VERSION "HNNBNNNYNNNNNNNNNNNNNNNNNNNNNNNNNNNNNNNNNN/4/%%%/4/'%**4NNN///"

NS_ :

BS_:

BU_: BAP_Tester ELV Gateway_Max HUD Kombi

BO_ 997 TSG_FT_02: 8 Gateway_Max
 SG_ TSG_FT_02_CRC : 0|8@1+ (1,0) [0|255] ""  Kombi
 SG_ TSG_FT_02_BZ : 8|4@1+ (1,0) [0|15] ""  Kombi
 SG_ FT_Tuer_Status : 12|2@1+ (1.0,0.0) [0.0|3] ""  Vector__XXX
 SG_ FT_Tuer_Status_QBit : 14|1@1+ (1.0,0.0) [0.0|1] ""  Vector__XXX
 SG_ FT_Lock_Taster_02 : 15|1@1+ (1.0,0.0) [0.0|1] ""  Vector__XXX
 SG_ FT_Schluesselschalter_zu_02 : 16|1@1+ (1.0,0.0) [0.0|1] ""  Vector__XXX
 SG_ FT_BFS_Tuer_Status : 17|2@1+ (1.0,0.0) [0.0|3] ""  Vector__XXX
 SG_ FT_HBFS_Tuer_Status : 19|2@1+ (1.0,0.0) [0.0|3] ""  Vector__XXX
 SG_ FT_HFS_Tuer_Status : 21|2@1+ (1.0,0.0) [0.0|3] ""  Vector__XXX
 SG_ FT_Tueroeffnen_Warnung : 23|1@1+ (1.0,0.0) [0.0|1] ""  Vector__XXX
 SG_ FT_SP_Heizung_ein : 24|1@1+ (1.0,0.0) [0.0|1] ""  Vector__XXX
 SG_ FT_Kisi_Taster_li_02 : 25|1@1+ (1.0,0.0) [0.0|1] ""  Vector__XXX
 SG_ FT_Kisi_Taster_re_02 : 26|1@1+ (1.0,0.0) [0.0|1] ""  Vector__XXX
 SG_ FT_TD_Taste_Status : 27|2@1+ (1.0,0.0) [0.0|3] ""  Vector__XXX
 SG_ FT_TCR_Mode_aktiv : 29|1@1+ (1.0,0.0) [0.0|1] ""  Vector__XXX
 SG_ TBF_FS_Touch_Event : 30|4@1+ (1.0,0.0) [0.0|15] ""  Vector__XXX
 SG_ FT_KiSi_Status_Soll_HBFS : 34|1@1+ (1.0,0.0) [0.0|1] ""  Vector__XXX
 SG_ FT_KiSi_Status_Soll_HFS : 35|1@1+ (1.0,0.0) [0.0|1] ""  Vector__XXX
 SG_ FS_Push_Tuergriff : 36|1@1+ (1.0,0.0) [0.0|1] ""  Vector__XXX
 SG_ TSG_FS_Spiegel_angeklappt : 37|1@1+ (1.0,0.0) [0.0|1] ""  Vector__XXX
 SG_ FT_Cargolock_bet : 38|1@1+ (1.0,0.0) [0.0|1] ""  Vector__XXX
 SG_ FT_kisi_asynchron : 40|1@1+ (1.0,0.0) [0.0|1] ""  Vector__XXX
 SG_ eTAB_FS_Bowdenzug_Auswerfen : 41|1@1+ (1.0,0.0) [0.0|1] ""  Vector__XXX
 SG_ FS_Status_eTAG_ext : 42|3@1+ (1.0,0.0) [0.0|7] ""  Vector__XXX
 SG_ FT_ASW_Warnton : 45|2@1+ (1.0,0.0) [0.0|3] ""  Vector__XXX
 SG_ SSA_FT_ASW_Status : 47|2@1+ (1.0,0.0) [0.0|3] ""  Vector__XXX

BO_ 975 TSG_HBFS_01: 8 Gateway_Max
 SG_ HBFS_Tuer_geoeffnet : 0|1@1+ (1.0,0.0) [0.0|1] ""  Vector__XXX
 SG_ HBFS_verriegelt : 1|1@1+ (1.0,0.0) [0.0|1] ""  Vector__XXX
 SG_ HBFS_gesafet : 2|1@1+ (1.0,0.0) [0.0|1] ""  Vector__XXX
 SG_ HBFS_Heckrollotaster_betaetigt : 3|1@1+ (1.0,0.0) [0.0|1] ""  Vector__XXX
 SG_ HBFS_Tuerschloss_defekt : 4|1@1+ (1.0,0.0) [0.0|1] ""  Vector__XXX
 SG_ HBFS_Unlock_Taster : 5|1@1+ (1.0,0.0) [0.0|1] ""  Vector__XXX
 SG_ HBFS_Lock_Taster : 6|1@1+ (1.0,0.0) [0.0|1] ""  Vector__XXX
 SG_ HBFS_Sperrklinke : 7|1@1+ (1.0,0.0) [0.0|1] ""  Vector__XXX
 SG_ HBFS_TAG_betaetigt : 8|1@1+ (1.0,0.0) [0.0|1] ""  Vector__XXX
 SG_ HBFS_TIG_betaetigt : 9|1@1+ (1.0,0.0) [0.0|1] ""  Vector__XXX
 SG_ HBFS_FH_S_HFS_AutoHoch : 10|1@1+ (1.0,0.0) [0.0|1] ""  Vector__XXX
 SG_ HBFS_FH_S_HFS_AutoTief : 11|1@1+ (1.0,0.0) [0.0|1] ""  Vector__XXX
 SG_ HBFS_FH_S_HFS_ManHoch : 12|1@1+ (1.0,0.0) [0.0|1] ""  Vector__XXX
 SG_ HBFS_FH_S_HFS_ManTief : 13|1@1+ (1.0,0.0) [0.0|1] ""  Vector__XXX
 SG_ HBFS_Tuer_Status : 14|2@1+ (1.0,0.0) [0.0|3] ""  Vector__XXX
 SG_ HBFS_SAD_Schalter : 16|4@1+ (1.0,0.0) [0.0|15] ""  Vector__XXX
 SG_ HBFS_FH_S_ManHoch : 20|1@1+ (1.0,0.0) [0.0|1] ""  Vector__XXX
 SG_ HBFS_FH_S_AutoHoch : 21|1@1+ (1.0,0.0) [0.0|1] ""  Vector__XXX
 SG_ HBFS_FH_S_ManTief : 22|1@1+ (1.0,0.0) [0.0|1] ""  Vector__XXX
 SG_ HBFS_FH_S_AutoTief : 23|1@1+ (1.0,0.0) [0.0|1] ""  Vector__XXX
 SG_ HBFS_FH_Oeffnung : 24|8@1+ (0.5,0) [0.0|100.0] "Unit_PerCent"  Vector__XXX
 SG_ HBFS_FH_Bew_hoch : 32|1@1+ (1.0,0.0) [0.0|1] ""  Vector__XXX
 SG_ HBFS_FH_Bew_tief : 33|1@1+ (1.0,0.0) [0.0|1] ""  Vector__XXX
 SG_ HBFS_FH_Fang : 34|1@1+ (1.0,0.0) [0.0|1] ""  Vector__XXX
 SG_ HBFS_FH_Block : 35|1@1+ (1.0,0.0) [0.0|1] ""  Vector__XXX
 SG_ HBFS_FH_Thermo : 36|1@1+ (1.0,0.0) [0.0|1] ""  Vector__XXX
 SG_ HBFS_UEKB_aktiviert : 37|1@1+ (1.0,0.0) [0.0|1] ""  Vector__XXX
 SG_ HBFS_Tueroeffnen_Warnung : 38|1@1+ (1.0,0.0) [0.0|1] ""  Vector__XXX
 SG_ HBFS_FH_normiert : 39|1@1+ (1.0,0.0) [0.0|1] ""  Vector__XXX
 SG_ ASW_Warnung_aktiv_HBFS : 40|1@1+ (1.0,0.0) [0.0|1] ""  Vector__XXX
 SG_ HBFS_Zuziehhilfe_aktiv : 41|1@1+ (1.0,0.0) [0.0|1] ""  Vector__XXX
 SG_ HBFS_Seitenrollo_hoch : 42|1@1+ (1.0,0.0) [0.0|1] ""  Vector__XXX
 SG_ HBFS_Seitenrollo_tief : 43|1@1+ (1.0,0.0) [0.0|1] ""  Vector__XXX
 SG_ HBFS_Status_KiSi : 44|1@1+ (1.0,0.0) [0.0|1] ""  Vector__XXX
 SG_ SSR_HBFS_Pos_Unten : 45|1@1+ (1.0,0.0) [0.0|1] ""  Vector__XXX
 SG_ HBFS_Oben_Block_erw : 46|1@1+ (1.0,0.0) [0.0|1] ""  Vector__XXX
 SG_ HBFS_Unten_Block_erw : 47|1@1+ (1.0,0.0) [0.0|1] ""  Vector__XXX
 SG_ MTHBFS_M_Taste : 48|1@1+ (1.0,0.0) [0.0|1] ""  Vector__XXX
 SG_ MTHBFS_Pos1 : 49|1@1+ (1.0,0.0) [0.0|1] ""  Vector__XXX
 SG_ MTHBFS_Pos2 : 50|1@1+ (1.0,0.0) [0.0|1] ""  Vector__XXX
 SG_ MTHBFS_Pos3 : 51|1@1+ (1.0,0.0) [0.0|1] ""  Vector__XXX
 SG_ HBFS_MRollo_Schalter : 52|3@1+ (1.0,0.0) [0.0|7] ""  Vector__XXX
 SG_ HBFS_Lock_Taster_inv : 55|1@1+ (1.0,0.0) [0.0|1] ""  Vector__XXX
 SG_ HBFS_Status_KiSi_inv : 56|1@1+ (1.0,0.0) [0.0|1] ""  Vector__XXX
 SG_ HBFS_Status_eTAG : 57|2@1+ (1.0,0.0) [0.0|3] ""  Vector__XXX
 SG_ HBFS_Tuer_Status_QBit : 59|1@1+ (1.0,0.0) [0.0|1] ""  Vector__XXX
 SG_ HBFS_TIG_betaetigt_schliessen : 60|1@1+ (1.0,0.0) [0.0|1] ""  Vector__XXX
 SG_ HBFS_TIG_betaetigt_oeffnen : 61|1@1+ (1.0,0.0) [0.0|1] ""  Vector__XXX
 SG_ HBFS_Vorraste_betaetigt : 62|1@1+ (1.0,0.0) [0.0|1] ""  Vector__XXX
 SG_ HBFS_SK_betaetigt : 63|1@1+ (1.0,0.0) [0.0|1] ""  Vector__XXX

BO_ 974 TSG_HFS_01: 8 Gateway_Max
 SG_ HFS_Tuer_geoeffnet : 0|1@1+ (1.0,0.0) [0.0|1] ""  Vector__XXX
 SG_ HFS_verriegelt : 1|1@1+ (1.0,0.0) [0.0|1] ""  Vector__XXX
 SG_ HFS_gesafet : 2|1@1+ (1.0,0.0) [0.0|1] ""  Vector__XXX
 SG_ HFS_Heckrollotaster_betaetigt : 3|1@1+ (1.0,0.0) [0.0|1] ""  Vector__XXX
 SG_ HFS_Tuerschloss_defekt : 4|1@1+ (1.0,0.0) [0.0|1] ""  Vector__XXX
 SG_ HFS_Unlock_Taster : 5|1@1+ (1.0,0.0) [0.0|1] ""  Vector__XXX
 SG_ HFS_Lock_Taster : 6|1@1+ (1.0,0.0) [0.0|1] ""  Vector__XXX
 SG_ HFS_Sperrklinke : 7|1@1+ (1.0,0.0) [0.0|1] ""  Vector__XXX
 SG_ HFS_TAG_betaetigt : 8|1@1+ (1.0,0.0) [0.0|1] ""  Vector__XXX
 SG_ HFS_TIG_betaetigt : 9|1@1+ (1.0,0.0) [0.0|1] ""  Vector__XXX
 SG_ HFS_FH_S_HBFS_AutoHoch : 10|1@1+ (1.0,0.0) [0.0|1] ""  Vector__XXX
 SG_ HFS_FH_S_HBFS_AutoTief : 11|1@1+ (1.0,0.0) [0.0|1] ""  Vector__XXX
 SG_ HFS_FH_S_HBFS_ManHoch : 12|1@1+ (1.0,0.0) [0.0|1] ""  Vector__XXX
 SG_ HFS_FH_S_HBFS_ManTief : 13|1@1+ (1.0,0.0) [0.0|1] ""  Vector__XXX
 SG_ HFS_Tuer_Status : 14|2@1+ (1.0,0.0) [0.0|3] ""  Vector__XXX
 SG_ HFS_SAD_Schalter : 16|4@1+ (1.0,0.0) [0.0|15] ""  Vector__XXX
 SG_ HFS_FH_S_ManHoch : 20|1@1+ (1.0,0.0) [0.0|1] ""  Vector__XXX
 SG_ HFS_FH_S_AutoHoch : 21|1@1+ (1.0,0.0) [0.0|1] ""  Vector__XXX
 SG_ HFS_FH_S_ManTief : 22|1@1+ (1.0,0.0) [0.0|1] ""  Vector__XXX
 SG_ HFS_FH_S_AutoTief : 23|1@1+ (1.0,0.0) [0.0|1] ""  Vector__XXX
 SG_ HFS_FH_Oeffnung : 24|8@1+ (0.5,0) [0.0|100.0] "Unit_PerCent"  Vector__XXX
 SG_ HFS_FH_Bew_hoch : 32|1@1+ (1.0,0.0) [0.0|1] ""  Vector__XXX
 SG_ HFS_FH_Bew_tief : 33|1@1+ (1.0,0.0) [0.0|1] ""  Vector__XXX
 SG_ HFS_FH_Fang : 34|1@1+ (1.0,0.0) [0.0|1] ""  Vector__XXX
 SG_ HFS_FH_Block : 35|1@1+ (1.0,0.0) [0.0|1] ""  Vector__XXX
 SG_ HFS_FH_Thermo : 36|1@1+ (1.0,0.0) [0.0|1] ""  Vector__XXX
 SG_ HFS_UEKB_aktiviert : 37|1@1+ (1.0,0.0) [0.0|1] ""  Vector__XXX
 SG_ HFS_Tueroeffnen_Warnung : 38|1@1+ (1.0,0.0) [0.0|1] ""  Vector__XXX
 SG_ HFS_FH_normiert : 39|1@1+ (1.0,0.0) [0.0|1] ""  Vector__XXX
 SG_ ASW_Warnung_aktiv_HFS : 40|1@1+ (1.0,0.0) [0.0|1] ""  Vector__XXX
 SG_ HFS_Zuziehhilfe_aktiv : 41|1@1+ (1.0,0.0) [0.0|1] ""  Vector__XXX
 SG_ HFS_Seitenrollo_hoch : 42|1@1+ (1.0,0.0) [0.0|1] ""  Vector__XXX
 SG_ HFS_Seitenrollo_tief : 43|1@1+ (1.0,0.0) [0.0|1] ""  Vector__XXX
 SG_ HFS_Status_KiSi : 44|1@1+ (1.0,0.0) [0.0|1] ""  Vector__XXX
 SG_ SSR_HFS_Pos_Unten : 45|1@1+ (1.0,0.0) [0.0|1] ""  Vector__XXX
 SG_ HFS_Oben_Block_erw : 46|1@1+ (1.0,0.0) [0.0|1] ""  Vector__XXX
 SG_ HFS_Unten_Block_erw : 47|1@1+ (1.0,0.0) [0.0|1] ""  Vector__XXX
 SG_ MTHFS_M_Taste : 48|1@1+ (1.0,0.0) [0.0|1] ""  Vector__XXX
 SG_ MTHFS_Pos1 : 49|1@1+ (1.0,0.0) [0.0|1] ""  Vector__XXX
 SG_ MTHFS_Pos2 : 50|1@1+ (1.0,0.0) [0.0|1] ""  Vector__XXX
 SG_ MTHFS_Pos3 : 51|1@1+ (1.0,0.0) [0.0|1] ""  Vector__XXX
 SG_ HFS_MRollo_Schalter : 52|3@1+ (1.0,0.0) [0.0|7] ""  Vector__XXX
 SG_ HFS_Lock_Taster_inv : 55|1@1+ (1.0,0.0) [0.0|1] ""  Vector__XXX
 SG_ HFS_Status_eTAG : 56|2@1+ (1.0,0.0) [0.0|3] ""  Vector__XXX
 SG_ HFS_Tuer_Status_QBit : 58|1@1+ (1.0,0.0) [0.0|1] ""  Vector__XXX
 SG_ HFS_TCR_Mode_aktiv : 59|1@1+ (1.0,0.0) [0.0|1] ""  Vector__XXX
 SG_ HFS_TIG_betaetigt_schliessen : 60|1@1+ (1.0,0.0) [0.0|1] ""  Vector__XXX
 SG_ HFS_TIG_betaetigt_oeffnen : 61|1@1+ (1.0,0.0) [0.0|1] ""  Vector__XXX
 SG_ HFS_Vorraste_betaetigt : 62|1@1+ (1.0,0.0) [0.0|1] ""  Vector__XXX
 SG_ HFS_SK_betaetigt : 63|1@1+ (1.0,0.0) [0.0|1] ""  Vector__XXX

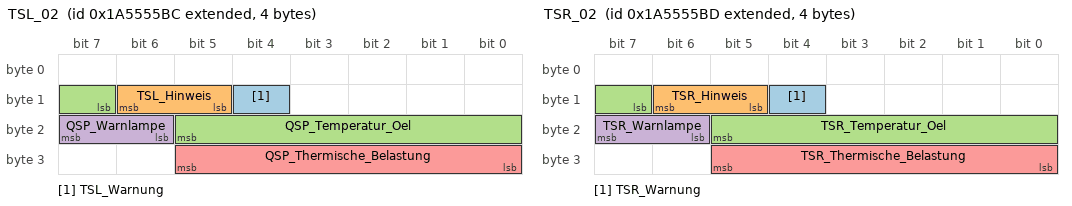
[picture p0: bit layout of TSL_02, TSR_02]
BO_ 2589283772 TSL_02: 4 Gateway_Max
 SG_ TSL_Warnung : 12|1@1+ (1.0,0.0) [0.0|1] ""  Kombi
 SG_ TSL_Hinweis : 13|2@1+ (1.0,0.0) [0.0|3] ""  Kombi
 SG_ QSP_Temperatur_Oel : 15|7@1+ (2,-40) [-40|210] "Unit_DegreCelsi"  Vector__XXX
 SG_ QSP_Warnlampe : 22|2@1+ (1.0,0.0) [0.0|3] ""  Vector__XXX
 SG_ QSP_Thermische_Belastung : 24|6@1+ (2,0) [0|100] "Unit_PerCent"  Vector__XXX

BO_ 2589283773 TSR_02: 4 Gateway_Max
 SG_ TSR_Warnung : 12|1@1+ (1.0,0.0) [0.0|1] ""  Kombi
 SG_ TSR_Hinweis : 13|2@1+ (1.0,0.0) [0.0|3] ""  Kombi
 SG_ TSR_Temperatur_Oel : 15|7@1+ (2,-40) [-40|210] "Unit_DegreCelsi"  Vector__XXX
 SG_ TSR_Warnlampe : 22|2@1+ (1.0,0.0) [0.0|3] ""  Vector__XXX
 SG_ TSR_Thermische_Belastung : 24|6@1+ (2,0) [0|100] "Unit_PerCent"  Vector__XXX

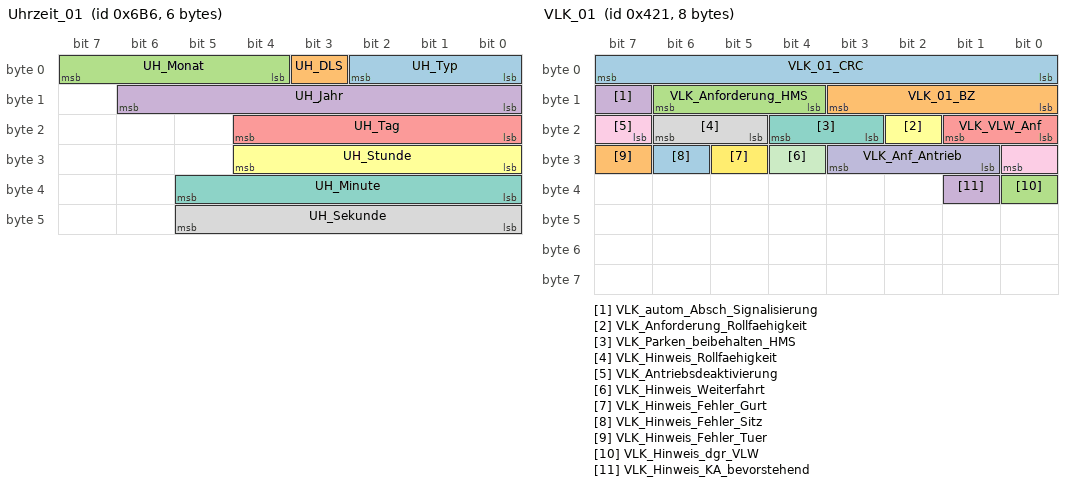
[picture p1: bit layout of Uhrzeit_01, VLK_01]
BO_ 1718 Uhrzeit_01: 6 Kombi
 SG_ UH_Typ : 0|3@1+ (1.0,0.0) [0.0|7] ""  Gateway_Max
 SG_ UH_DLS : 3|1@1+ (1.0,0.0) [0.0|1] ""  Gateway_Max
 SG_ UH_Monat : 4|4@1+ (1,0) [1|12] "Unit_Month"  Gateway_Max
 SG_ UH_Jahr : 8|7@1+ (1,2000) [2000|2127] "Unit_Year"  Gateway_Max
 SG_ UH_Tag : 16|5@1+ (1,0) [1|31] "Unit_Day"  Gateway_Max
 SG_ UH_Stunde : 24|5@1+ (1,0) [0|23] "Unit_Hours"  Gateway_Max
 SG_ UH_Minute : 32|6@1+ (1,0) [0|59] "Unit_Minut"  Gateway_Max
 SG_ UH_Sekunde : 40|6@1+ (1,0) [0|59] "Unit_Secon"  Gateway_Max

BO_ 995 Verdeck_01: 8 Gateway_Max
 SG_ VS_VD_zu_ver : 16|1@1+ (1.0,0.0) [0.0|1] ""  Vector__XXX
 SG_ VS_VD_entriegelt : 17|1@1+ (1.0,0.0) [0.0|1] ""  Vector__XXX
 SG_ VS_VD_offen_ver : 18|1@1+ (1.0,0.0) [0.0|1] ""  Vector__XXX
 SG_ VS_VD_Zwischenposition : 19|1@1+ (1.0,0.0) [0.0|1] ""  Vector__XXX
 SG_ VS_VD_Bew_auf : 20|1@1+ (1.0,0.0) [0.0|1] ""  Vector__XXX
 SG_ VS_VD_Bew_zu : 21|1@1+ (1.0,0.0) [0.0|1] ""  Vector__XXX
 SG_ VS_Verdeck_Anf : 22|1@1+ (1.0,0.0) [0.0|1] ""  Vector__XXX
 SG_ VS_Hardtop : 23|1@1+ (1.0,0.0) [0.0|1] ""  Vector__XXX
 SG_ VS_VD_Fehler : 24|1@1+ (1.0,0.0) [0.0|1] ""  Vector__XXX
 SG_ VS_Lampe_Blk : 25|1@1+ (1.0,0.0) [0.0|1] ""  Vector__XXX
 SG_ VS_Buzzer : 26|1@1+ (1.0,0.0) [0.0|1] ""  Vector__XXX
 SG_ VS_HD_sperren : 27|1@1+ (1.0,0.0) [0.0|1] ""  Vector__XXX
 SG_ VS_HHS_enable : 28|1@1+ (1.0,0.0) [0.0|1] ""  Vector__XXX
 SG_ VD_SpannungsAnf : 29|2@1+ (1.0,0.0) [0.0|3] ""  Vector__XXX
 SG_ VS_VDKD_auf : 31|1@1+ (1.0,0.0) [0.0|1] ""  Vector__XXX
 SG_ VS_FS_AutoHoch : 32|1@1+ (1.0,0.0) [0.0|1] ""  Vector__XXX
 SG_ VS_FS_AutoTief : 33|1@1+ (1.0,0.0) [0.0|1] ""  Vector__XXX
 SG_ VS_FS_ManHoch : 34|1@1+ (1.0,0.0) [0.0|1] ""  Vector__XXX
 SG_ VS_FS_ManTief : 35|1@1+ (1.0,0.0) [0.0|1] ""  Vector__XXX
 SG_ VS_BFS_AutoHoch : 36|1@1+ (1.0,0.0) [0.0|1] ""  Vector__XXX
 SG_ VS_BFS_AutoTief : 37|1@1+ (1.0,0.0) [0.0|1] ""  Vector__XXX
 SG_ VS_BFS_ManHoch : 38|1@1+ (1.0,0.0) [0.0|1] ""  Vector__XXX
 SG_ VS_BFS_ManTief : 39|1@1+ (1.0,0.0) [0.0|1] ""  Vector__XXX
 SG_ VS_HFS_AutoHoch : 40|1@1+ (1.0,0.0) [0.0|1] ""  Vector__XXX
 SG_ VS_HFS_AutoTief : 41|1@1+ (1.0,0.0) [0.0|1] ""  Vector__XXX
 SG_ VS_HFS_ManHoch : 42|1@1+ (1.0,0.0) [0.0|1] ""  Vector__XXX
 SG_ VS_HFS_ManTief : 43|1@1+ (1.0,0.0) [0.0|1] ""  Vector__XXX
 SG_ VS_HBFS_AutoHoch : 44|1@1+ (1.0,0.0) [0.0|1] ""  Vector__XXX
 SG_ VS_HBFS_AutoTief : 45|1@1+ (1.0,0.0) [0.0|1] ""  Vector__XXX
 SG_ VS_HBFS_ManHoch : 46|1@1+ (1.0,0.0) [0.0|1] ""  Vector__XXX
 SG_ VS_HBFS_ManTief : 47|1@1+ (1.0,0.0) [0.0|1] ""  Vector__XXX
 SG_ VS_FH_FT_Langhub : 49|1@1+ (1.0,0.0) [0.0|1] ""  Vector__XXX
 SG_ VS_Windschott_nicht_abgelegt : 50|1@1+ (1.0,0.0) [0.0|1] ""  Vector__XXX
 SG_ VS_FH_BT_Langhub : 51|1@1+ (1.0,0.0) [0.0|1] ""  Vector__XXX
 SG_ VS_FH_HFS_Langhub : 53|1@1+ (1.0,0.0) [0.0|1] ""  Vector__XXX
 SG_ VS_Heckschloss_auf : 54|1@1+ (1.0,0.0) [0.0|1] ""  Vector__XXX
 SG_ VS_FH_HBFS_Langhub : 55|1@1+ (1.0,0.0) [0.0|1] ""  Vector__XXX
 SG_ VSG_Meldungen : 56|6@1+ (1,0) [1|63] "Unit_None"  Kombi
 SG_ VS_StartStopp_Info : 62|2@1+ (1.0,0.0) [0.0|3] ""  Vector__XXX

BO_ 1716 VIN_01: 8 Gateway_Max
 SG_ VIN_01_MUX M  : 0|2@1+ (1,0) [0|3] ""  HUD,Kombi
 SG_ KS_Geheimnis_1 m0  : 8|8@1+ (1,0) [0|255] ""  Vector__XXX
 SG_ VIN_4 m1  : 8|8@1+ (1,0) [0|255] ""  HUD,Kombi
 SG_ VIN_11 m2  : 8|8@1+ (1,0) [0|255] ""  HUD,Kombi
 SG_ KS_Geheimnis_2 m0  : 16|8@1+ (1,0) [0|255] ""  Vector__XXX
 SG_ VIN_5 m1  : 16|8@1+ (1,0) [0|255] ""  HUD,Kombi
 SG_ VIN_12 m2  : 16|8@1+ (1,0) [0|255] ""  HUD,Kombi
 SG_ KS_Geheimnis_3 m0  : 24|8@1+ (1,0) [0|255] ""  Vector__XXX
 SG_ VIN_6 m1  : 24|8@1+ (1,0) [0|255] ""  HUD,Kombi
 SG_ VIN_13 m2  : 24|8@1+ (1,0) [0|255] ""  HUD,Kombi
 SG_ KS_Geheimnis_4 m0  : 32|8@1+ (1,0) [0|255] ""  Vector__XXX
 SG_ VIN_7 m1  : 32|8@1+ (1,0) [0|255] ""  HUD,Kombi
 SG_ VIN_14 m2  : 32|8@1+ (1,0) [0|255] ""  HUD,Kombi
 SG_ VIN_1 m0  : 40|8@1+ (1,0) [0|255] ""  HUD,Kombi
 SG_ VIN_8 m1  : 40|8@1+ (1,0) [0|255] ""  HUD,Kombi
 SG_ VIN_15 m2  : 40|8@1+ (1,0) [0|255] ""  HUD,Kombi
 SG_ VIN_2 m0  : 48|8@1+ (1,0) [0|255] ""  HUD,Kombi
 SG_ VIN_9 m1  : 48|8@1+ (1,0) [0|255] ""  HUD,Kombi
 SG_ VIN_16 m2  : 48|8@1+ (1,0) [0|255] ""  HUD,Kombi
 SG_ VIN_3 m0  : 56|8@1+ (1,0) [0|255] ""  HUD,Kombi
 SG_ VIN_10 m1  : 56|8@1+ (1,0) [0|255] ""  HUD,Kombi
 SG_ VIN_17 m2  : 56|8@1+ (1,0) [0|255] ""  HUD,Kombi

BO_ 1057 VLK_01: 8 Gateway_Max
 SG_ VLK_01_CRC : 0|8@1+ (1,0) [0|255] ""  Vector__XXX
 SG_ VLK_01_BZ : 8|4@1+ (1,0) [0|15] ""  Vector__XXX
 SG_ VLK_Anforderung_HMS : 12|3@1+ (1.0,0.0) [0.0|7] ""  Vector__XXX
 SG_ VLK_autom_Absch_Signalisierung : 15|1@1+ (1.0,0.0) [0.0|1] ""  Vector__XXX
 SG_ VLK_VLW_Anf : 16|2@1+ (1.0,0.0) [0.0|3] ""  Vector__XXX
 SG_ VLK_Anforderung_Rollfaehigkeit : 18|1@1+ (1.0,0.0) [0.0|1] ""  Vector__XXX
 SG_ VLK_Parken_beibehalten_HMS : 19|2@1+ (1.0,0.0) [0.0|3] ""  Vector__XXX
 SG_ VLK_Hinweis_Rollfaehigkeit : 21|2@1+ (1.0,0.0) [0.0|3] ""  Vector__XXX
 SG_ VLK_Antriebsdeaktivierung : 23|2@1+ (1.0,0.0) [0.0|3] ""  Vector__XXX
 SG_ VLK_Anf_Antrieb : 25|3@1+ (1.0,0.0) [0.0|7] ""  Vector__XXX
 SG_ VLK_Hinweis_Weiterfahrt : 28|1@1+ (1.0,0.0) [0.0|1] ""  Kombi
 SG_ VLK_Hinweis_Fehler_Gurt : 29|1@1+ (1.0,0.0) [0.0|1] ""  Kombi
 SG_ VLK_Hinweis_Fehler_Sitz : 30|1@1+ (1.0,0.0) [0.0|1] ""  Kombi
 SG_ VLK_Hinweis_Fehler_Tuer : 31|1@1+ (1.0,0.0) [0.0|1] ""  Kombi
 SG_ VLK_Hinweis_dgr_VLW : 32|1@1+ (1.0,0.0) [0.0|1] ""  Kombi
 SG_ VLK_Hinweis_KA_bevorstehend : 33|1@1+ (1.0,0.0) [0.0|1] ""  Kombi

BO_ 2463978663 VZE_04: 32 Gateway_Max
 SG_ VZE_Anzeigemodus : 0|2@1+ (1.0,0.0) [0.0|3] ""  HUD,Kombi
 SG_ VZE_Hinweistext : 2|3@1+ (1,0) [1|7] ""  Vector__XXX
 SG_ VZE_Akustik_Limitwechsel : 5|1@1+ (1.0,0.0) [0.0|1] ""  Kombi
 SG_ VZE_Modus_OptischeWarnung : 6|1@1+ (1.0,0.0) [0.0|1] ""  Kombi
 SG_ VZE_Verkehrszeichen_Einheit : 8|1@1+ (1.0,0.0) [0.0|1] ""  Vector__XXX
 SG_ VZE_Anzeigeunterdrueck_Zeichen_3 : 9|1@1+ (1.0,0.0) [0.0|1] ""  Vector__XXX
 SG_ VZE_Anzeigeunterdrueck_Zeichen_2 : 10|1@1+ (1.0,0.0) [0.0|1] ""  Vector__XXX
 SG_ VZE_Verkehrszeichen_1 : 11|8@1+ (1,0) [1|255] ""  Vector__XXX
 SG_ VZE_Verkehrszeichen_2 : 19|8@1+ (1,0) [1|255] ""  Vector__XXX
 SG_ VZE_Verkehrszeichen_3 : 27|8@1+ (1,0) [1|255] ""  Vector__XXX
 SG_ VZE_Warnung_Verkehrszeichen_1 : 35|1@1+ (1.0,0.0) [0.0|1] ""  HUD
 SG_ VZE_Warnung_Verkehrszeichen_2 : 36|1@1+ (1.0,0.0) [0.0|1] ""  Vector__XXX
 SG_ VZE_Warnung_Verkehrszeichen_3 : 37|1@1+ (1.0,0.0) [0.0|1] ""  Vector__XXX
 SG_ VZE_Zusatzschild_1 : 38|4@1+ (1,0) [1|15] ""  Vector__XXX
 SG_ VZE_Zusatzschild_2 : 42|4@1+ (1,0) [1|15] ""  Vector__XXX
 SG_ VZE_Zusatzschild_3 : 46|4@1+ (1,0) [1|15] ""  Vector__XXX
 SG_ VZE_Anzeigeunterdrueck_Zeichen_1 : 50|1@1+ (1.0,0.0) [0.0|1] ""  Vector__XXX
 SG_ VZE_Zeichen_01_KameraWied : 51|1@1+ (1.0,0.0) [0.0|1] ""  Vector__XXX
 SG_ VZE_Zeichen_02_KameraWied : 52|1@1+ (1.0,0.0) [0.0|1] ""  Vector__XXX
 SG_ VZE_Zeichen_03_KameraWied : 53|1@1+ (1.0,0.0) [0.0|1] ""  Vector__XXX
 SG_ VZE_Zeichen_01_Kamera : 54|1@1+ (1.0,0.0) [0.0|1] ""  HUD
 SG_ VZE_Zeichen_01_Karte : 55|1@1+ (1.0,0.0) [0.0|1] ""  HUD
 SG_ VZE_Zeichen_01_Gesetz : 56|1@1+ (1.0,0.0) [0.0|1] ""  Vector__XXX
 SG_ VZE_Zeichen_02_Kamera : 57|1@1+ (1.0,0.0) [0.0|1] ""  Vector__XXX
 SG_ VZE_Zeichen_02_Karte : 58|1@1+ (1.0,0.0) [0.0|1] ""  Vector__XXX
 SG_ VZE_Zeichen_02_Gesetz : 59|1@1+ (1.0,0.0) [0.0|1] ""  Vector__XXX
 SG_ VZE_Zeichen_03_Kamera : 60|1@1+ (1.0,0.0) [0.0|1] ""  Vector__XXX
 SG_ VZE_Zeichen_03_Karte : 61|1@1+ (1.0,0.0) [0.0|1] ""  Vector__XXX
 SG_ VZE_Zeichen_03_Gesetz : 62|1@1+ (1.0,0.0) [0.0|1] ""  Vector__XXX
 SG_ VZE_Gong : 63|1@1+ (1.0,0.0) [0.0|1] ""  Vector__XXX
 SG_ VZE_Akustik_Limitwechsel_Status : 69|1@1+ (1.0,0.0) [0.0|1] ""  Vector__XXX
 SG_ VZE_SLWF_Status : 70|2@1+ (1.0,0.0) [0.0|3] ""  Vector__XXX
 SG_ VZE_Anzeigeunterdrueck_Zeichen_5 : 72|1@1+ (1.0,0.0) [0.0|1] ""  Vector__XXX
 SG_ VZE_Zeichen_05_KameraWied : 73|1@1+ (1.0,0.0) [0.0|1] ""  Vector__XXX
 SG_ VZE_Zeichen_05_Kamera : 74|1@1+ (1.0,0.0) [0.0|1] ""  Vector__XXX
 SG_ VZE_Verkehrszeichen_4 : 75|8@1+ (1,0) [1|255] ""  Vector__XXX
 SG_ VZE_Verkehrszeichen_5 : 83|8@1+ (1,0) [1|255] ""  Vector__XXX
 SG_ VZE_Anhaenger_Vmax : 91|4@1+ (10,10) [10|140] "Unit_KiloMeterPerHour"  Vector__XXX
 SG_ VZE_Zeichen_04_Gesetz : 95|1@1+ (1.0,0.0) [0.0|1] ""  Vector__XXX
 SG_ VZE_Zeichen_04_Kamera : 96|1@1+ (1.0,0.0) [0.0|1] ""  Vector__XXX
 SG_ VZE_Zeichen_04_KameraWied : 97|1@1+ (1.0,0.0) [0.0|1] ""  Vector__XXX
 SG_ VZE_Zeichen_04_Karte : 98|1@1+ (1.0,0.0) [0.0|1] ""  Vector__XXX
 SG_ VZE_Warnung_Verkehrszeichen_4 : 99|1@1+ (1.0,0.0) [0.0|1] ""  Vector__XXX
 SG_ VZE_Warnung_Verkehrszeichen_5 : 100|1@1+ (1.0,0.0) [0.0|1] ""  Vector__XXX
 SG_ VZE_Zeichen_05_Gesetz : 101|1@1+ (1.0,0.0) [0.0|1] ""  Vector__XXX
 SG_ VZE_Zusatzschild_4 : 102|4@1+ (1,0) [1|15] ""  Vector__XXX
 SG_ VZE_Zusatzschild_5 : 106|4@1+ (1,0) [1|15] ""  Vector__XXX
 SG_ VZE_Baustelle : 110|2@1+ (1.0,0.0) [0.0|3] ""  Vector__XXX
 SG_ VZE_Zeichen_05_Karte : 112|1@1+ (1.0,0.0) [0.0|1] ""  Vector__XXX
 SG_ VZE_Zeichen_05_Entfernung : 113|7@1+ (1,0) [1|127] "Unit_Meter"  Vector__XXX
 SG_ VZE_Zeichen_05_Entfernung_StdA : 120|7@1+ (1,0) [1|127] "Unit_Meter"  Vector__XXX
 SG_ VZE_Anzeigeunterdrueck_Zeichen_4 : 127|1@1+ (1.0,0.0) [0.0|1] ""  Vector__XXX
 SG_ VZE_Verkehrszeichen_6 : 128|8@1+ (1,0) [1|255] "Unit_None"  Vector__XXX
 SG_ VZE_Zusatzschild_6 : 136|4@1+ (1,0) [1|15] ""  Vector__XXX
 SG_ VZE_Zeichen_06_Entfernung : 140|7@1+ (1,0) [1|127] "Unit_Meter"  Vector__XXX
 SG_ VZE_Zeichen_06_Entfernung_StdA : 147|7@1+ (1,0) [1|127] "Unit_Meter"  Vector__XXX
 SG_ VZE_Umweltinfo_Naesse : 154|1@1+ (1.0,0.0) [0.0|1] ""  Vector__XXX
 SG_ VZE_Umweltinfo_Nebel : 155|1@1+ (1.0,0.0) [0.0|1] ""  Vector__XXX
 SG_ VZE_Umweltinfo_Anhaengerbetrieb : 156|1@1+ (1.0,0.0) [0.0|1] ""  Vector__XXX
 SG_ VZE_Erweiterte_Information : 157|8@1+ (1,0) [1|255] "Unit_None"  Vector__XXX
 SG_ VZE_Tempowarnung_Status : 165|1@1+ (1.0,0.0) [0.0|1] ""  Vector__XXX
 SG_ VZE_Tempowarnung_Einheit : 166|1@1+ (1.0,0.0) [0.0|1] ""  Vector__XXX
 SG_ VZE_Tempowarnung_Offset : 167|5@1+ (1,0) [1|31] ""  Vector__XXX
 SG_ VZE_FoD_Status : 206|2@1+ (1.0,0.0) [0.0|3] ""  HUD,Kombi
 SG_ VZE_Anzeige_ZS_1 : 208|4@1+ (1,0) [1|15] "Unit_None"  Vector__XXX
 SG_ VZE_Anzeige_ZS_2 : 212|4@1+ (1,0) [1|15] "Unit_None"  Vector__XXX
 SG_ VZE_Anzeige_ZS_3 : 216|4@1+ (1,0) [1|15] "Unit_None"  Vector__XXX
 SG_ VZE_Hinweistext_03 : 220|4@1+ (1,0) [1|15] ""  Vector__XXX
 SG_ VZE_Land : 224|5@1+ (1,0) [1|31] ""  Vector__XXX
 SG_ VZE_Warnung_VZ_1 : 229|1@1+ (1.0,0.0) [0.0|1] ""  Vector__XXX
 SG_ VZE_Warnung_VZ_2 : 230|1@1+ (1.0,0.0) [0.0|1] ""  Vector__XXX
 SG_ VZE_Warnung_VZ_3 : 231|1@1+ (1.0,0.0) [0.0|1] ""  Vector__XXX
 SG_ VZE_Anzeige_VZ_1 : 232|8@1+ (1,0) [1|255] ""  Vector__XXX
 SG_ VZE_Anzeige_VZ_2 : 240|8@1+ (1,0) [1|255] "Unit_None"  Vector__XXX
 SG_ VZE_Anzeige_VZ_3 : 248|8@1+ (1,0) [1|255] "Unit_None"  Vector__XXX

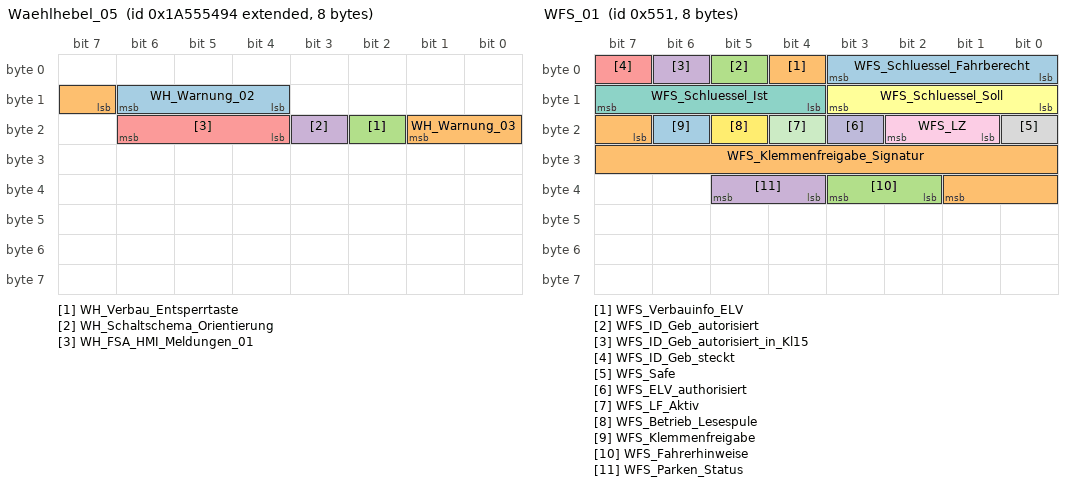
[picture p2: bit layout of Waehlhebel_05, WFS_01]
BO_ 2589283476 Waehlhebel_05: 8 Gateway_Max
 SG_ WH_Warnung_02 : 12|3@1+ (1.0,0.0) [0.0|7] ""  Kombi
 SG_ WH_Warnung_03 : 15|3@1+ (1.0,0.0) [0.0|7] ""  Vector__XXX
 SG_ WH_Verbau_Entsperrtaste : 18|1@1+ (1.0,0.0) [0.0|1] ""  Kombi
 SG_ WH_Schaltschema_Orientierung : 19|1@1+ (1.0,0.0) [0.0|1] ""  Kombi
 SG_ WH_FSA_HMI_Meldungen_01 : 20|3@1+ (1.0,0.0) [0.0|7] ""  Kombi

BO_ 916 WBA_03: 8 Gateway_Max
 SG_ WBA_03_CRC : 0|8@1+ (1,0) [0|255] ""  Kombi
 SG_ WBA_03_BZ : 8|4@1+ (1,0) [0|15] ""  Kombi
 SG_ WBA_Fahrstufe_02 : 12|4@1+ (1.0,0.0) [0.0|15] ""  HUD,Kombi
 SG_ WBA_ZielFahrstufe : 16|4@1+ (1.0,0.0) [0.0|15] ""  Vector__XXX
 SG_ WBA_GE_Warnung_02 : 20|4@1+ (1.0,0.0) [0.0|15] ""  Kombi
 SG_ WBA_eing_Gang_02 : 24|4@1+ (1.0,0.0) [0.0|15] ""  HUD,Kombi
 SG_ WBA_GE_Texte : 28|3@1+ (1.0,0.0) [0.0|7] ""  Kombi
 SG_ WBA_Segeln_aktiv : 31|1@1+ (1.0,0.0) [0.0|1] ""  Kombi
 SG_ WBA_Schaltschema_02 : 32|3@1+ (1.0,0.0) [0.0|7] ""  Kombi
 SG_ WBA_Schaltschema_FS_inaktiv : 35|2@1+ (1.0,0.0) [0.0|3] ""  Kombi
 SG_ WBA_GE_Zusatzwarnungen : 37|3@1+ (1.0,0.0) [0.0|7] ""  Kombi
 SG_ GE_Sollgang : 40|4@1+ (1.0,0.0) [0.0|15] ""  Kombi
 SG_ GE_Tipschaltempf_verfuegbar : 44|1@1+ (1.0,0.0) [0.0|1] ""  Kombi
 SG_ WBA_GE_Texte_02 : 45|3@1+ (1.0,0.0) [0.0|7] ""  Kombi
 SG_ WBA_Schaltschema_Tippgasse : 48|1@1+ (1.0,0.0) [0.0|1] ""  Kombi
 SG_ WBA_Schaltschema_Fahreraktion : 49|1@1+ (1.0,0.0) [0.0|1] ""  Kombi
 SG_ WBA_Schaltschema_FS_vorwaerts : 50|2@1+ (1.0,0.0) [0.0|3] ""  Kombi
 SG_ WBA_Shiftlock_Lampe : 52|1@1+ (1.0,0.0) [0.0|1] ""  Kombi
 SG_ WBA_Anforderung_Akustik : 53|1@1+ (1.0,0.0) [0.0|1] ""  Kombi
 SG_ WBA_Blinken : 54|1@1+ (1.0,0.0) [0.0|1] ""  Vector__XXX
 SG_ GE_Wiederstart_Anz_Std : 55|1@1+ (1.0,0.0) [0.0|1] ""  Vector__XXX
 SG_ GE_Stoppverbot_Anz_01 : 56|1@1+ (1.0,0.0) [0.0|1] ""  Vector__XXX
 SG_ GE_Stoppverbot_Anz_02 : 57|1@1+ (1.0,0.0) [0.0|1] ""  Vector__XXX
 SG_ GE_Stoppverbot_Anz_03 : 58|1@1+ (1.0,0.0) [0.0|1] ""  Vector__XXX
 SG_ GE_Stoppverbot_Anz_04 : 59|1@1+ (1.0,0.0) [0.0|1] ""  Vector__XXX
 SG_ GE_Stoppverbot_Anz_05 : 60|1@1+ (1.0,0.0) [0.0|1] ""  Vector__XXX
 SG_ GE_Stoppverbot_Anz_06 : 61|1@1+ (1.0,0.0) [0.0|1] ""  Vector__XXX
 SG_ GE_Stoppverbot_Anz_07 : 62|1@1+ (1.0,0.0) [0.0|1] ""  Vector__XXX
 SG_ GE_Stoppverbot_Anz_Std : 63|1@1+ (1.0,0.0) [0.0|1] ""  Vector__XXX

BO_ 1361 WFS_01: 8 Gateway_Max
 SG_ WFS_Schluessel_Fahrberecht : 0|4@1+ (1.0,0.0) [0.0|15] ""  Kombi
 SG_ WFS_Verbauinfo_ELV : 4|1@1+ (1.0,0.0) [0.0|1] ""  Vector__XXX
 SG_ WFS_ID_Geb_autorisiert : 5|1@1+ (1.0,0.0) [0.0|1] ""  Vector__XXX
 SG_ WFS_ID_Geb_autorisiert_in_Kl15 : 6|1@1+ (1.0,0.0) [0.0|1] ""  Vector__XXX
 SG_ WFS_ID_Geb_steckt : 7|1@1+ (1.0,0.0) [0.0|1] ""  Vector__XXX
 SG_ WFS_Schluessel_Soll : 8|4@1+ (1,0) [0|8] "Unit_None"  Kombi
 SG_ WFS_Schluessel_Ist : 12|4@1+ (1,0) [0|8] "Unit_None"  ELV,Kombi
 SG_ WFS_Safe : 16|1@1+ (1.0,0.0) [0.0|1] ""  Kombi
 SG_ WFS_LZ : 17|2@1+ (1.0,0.0) [0.0|3] ""  Kombi
 SG_ WFS_ELV_authorisiert : 19|1@1+ (1.0,0.0) [0.0|1] ""  Vector__XXX
 SG_ WFS_LF_Aktiv : 20|1@1+ (1.0,0.0) [0.0|1] ""  Vector__XXX
 SG_ WFS_Betrieb_Lesespule : 21|1@1+ (1.0,0.0) [0.0|1] ""  Vector__XXX
 SG_ WFS_Klemmenfreigabe : 22|1@1+ (1.0,0.0) [0.0|1] ""  Vector__XXX
 SG_ WFS_Klemmenfreigabe_Signatur : 23|11@1+ (1,0) [0|2047] ""  Vector__XXX
 SG_ WFS_Fahrerhinweise : 34|2@1+ (1.0,0.0) [0.0|3] ""  Kombi
 SG_ WFS_Parken_Status : 36|2@1+ (1.0,0.0) [0.0|3] ""  Vector__XXX

BO_ 34 WFS_Transponder_Req_02: 8 Gateway_Max
 SG_ WFS_Transponder_Req_02_Data : 0|64@1+ (1,0) [0|18446744073709551615] "Unit_None"  Kombi

BO_ 35 WFS_Transponder_Resp_02: 8 Kombi
 SG_ WFS_Transponder_Resp_02_Data : 0|64@1+ (1,0) [0|18446744073709551615] "Unit_None"  Gateway_Max

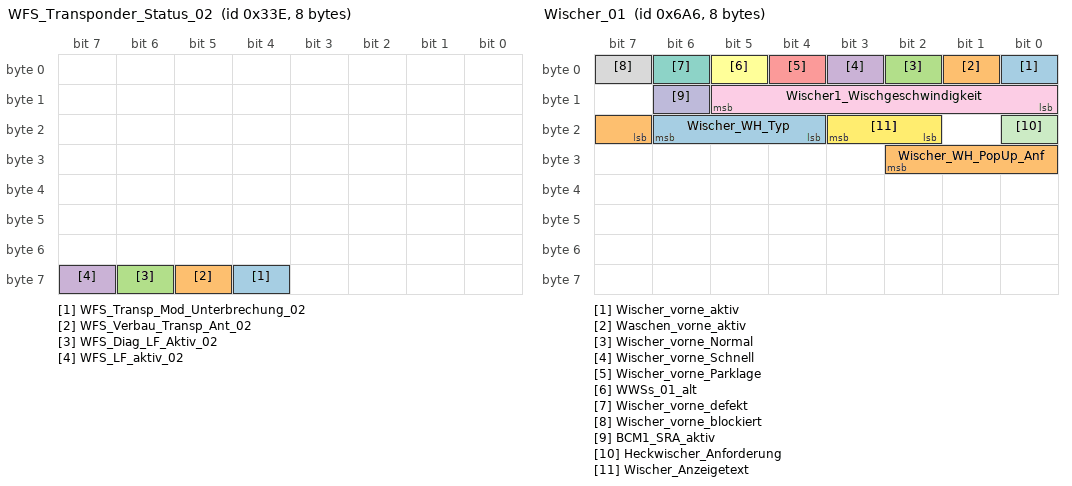
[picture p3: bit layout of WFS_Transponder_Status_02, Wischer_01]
BO_ 830 WFS_Transponder_Status_02: 8 Kombi
 SG_ WFS_Transp_Mod_Unterbrechung_02 : 60|1@1+ (1.0,0.0) [0.0|1] ""  Gateway_Max
 SG_ WFS_Verbau_Transp_Ant_02 : 61|1@1+ (1.0,0.0) [0.0|1] ""  Gateway_Max
 SG_ WFS_Diag_LF_Aktiv_02 : 62|1@1+ (1.0,0.0) [0.0|1] ""  Gateway_Max
 SG_ WFS_LF_aktiv_02 : 63|1@1+ (1.0,0.0) [0.0|1] ""  Gateway_Max

BO_ 1702 Wischer_01: 8 Gateway_Max
 SG_ Wischer_vorne_aktiv : 0|1@1+ (1.0,0.0) [0.0|1] ""  Vector__XXX
 SG_ Waschen_vorne_aktiv : 1|1@1+ (1.0,0.0) [0.0|1] ""  Vector__XXX
 SG_ Wischer_vorne_Normal : 2|1@1+ (1.0,0.0) [0.0|1] ""  Vector__XXX
 SG_ Wischer_vorne_Schnell : 3|1@1+ (1.0,0.0) [0.0|1] ""  Vector__XXX
 SG_ Wischer_vorne_Parklage : 4|1@1+ (1.0,0.0) [0.0|1] ""  Vector__XXX
 SG_ WWSs_01_alt : 5|1@1+ (1.0,0.0) [0.0|1] ""  Vector__XXX
 SG_ Wischer_vorne_defekt : 6|1@1+ (1.0,0.0) [0.0|1] ""  Kombi
 SG_ Wischer_vorne_blockiert : 7|1@1+ (1.0,0.0) [0.0|1] ""  Vector__XXX
 SG_ Wischer1_Wischgeschwindigkeit : 8|6@1+ (1,9) [10|70] "Unit_MinutInver"  Vector__XXX
 SG_ BCM1_SRA_aktiv : 14|1@1+ (1.0,0.0) [0.0|1] ""  Vector__XXX
 SG_ Heckwischer_Anforderung : 16|1@1+ (1.0,0.0) [0.0|1] ""  Vector__XXX
 SG_ Wischer_Anzeigetext : 18|2@1+ (1.0,0.0) [0.0|3] ""  Vector__XXX
 SG_ Wischer_WH_Typ : 20|3@1+ (1.0,0.0) [0.0|7] ""  Kombi
 SG_ Wischer_WH_PopUp_Anf : 23|4@1+ (1.0,0.0) [0.0|15] ""  Kombi

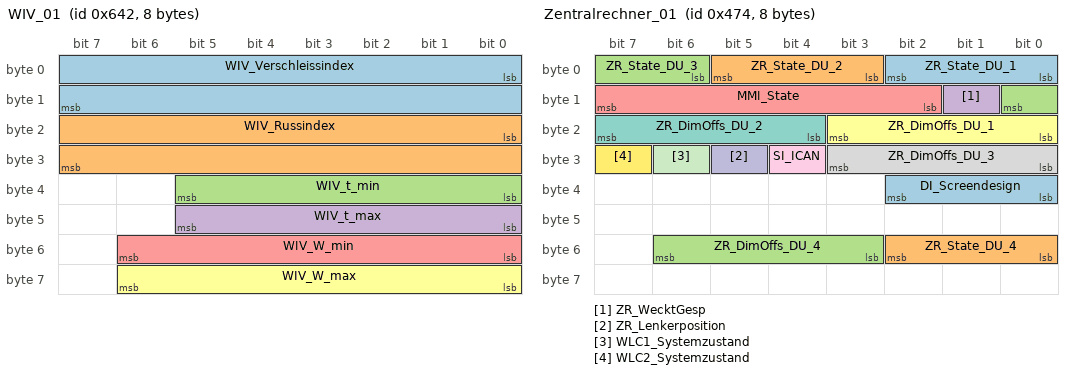
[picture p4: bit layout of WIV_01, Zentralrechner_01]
BO_ 1602 WIV_01: 8 Gateway_Max
 SG_ WIV_Verschleissindex : 0|16@1+ (2E-8,0) [0E-8|0.00131068] ""  Kombi
 SG_ WIV_Russindex : 16|16@1+ (2E-8,0) [0E-8|0.00131068] ""  Kombi
 SG_ WIV_t_min : 32|6@1+ (1,0) [0|63] "Unit_Month"  Kombi
 SG_ WIV_t_max : 40|6@1+ (1,0) [0|63] "Unit_Month"  Kombi
 SG_ WIV_W_min : 48|7@1+ (1000,0) [0|127000] "Unit_KiloMeter"  Kombi
 SG_ WIV_W_max : 56|7@1+ (1000,0) [0|127000] "Unit_KiloMeter"  Kombi

BO_ 1140 Zentralrechner_01: 8 Gateway_Max
 SG_ ZR_State_DU_1 : 0|3@1+ (1.0,0.0) [0.0|7] ""  Vector__XXX
 SG_ ZR_State_DU_2 : 3|3@1+ (1.0,0.0) [0.0|7] ""  Vector__XXX
 SG_ ZR_State_DU_3 : 6|3@1+ (1.0,0.0) [0.0|7] ""  Vector__XXX
 SG_ ZR_WecktGesp : 9|1@1+ (1.0,0.0) [0.0|1] ""  Vector__XXX
 SG_ MMI_State : 10|6@1+ (1.0,0.0) [0.0|63] ""  Vector__XXX
 SG_ ZR_DimOffs_DU_1 : 16|4@1+ (1,-5) [-5|5] "Unit_None"  Vector__XXX
 SG_ ZR_DimOffs_DU_2 : 20|4@1+ (1,-5) [-5|5] "Unit_None"  Vector__XXX
 SG_ ZR_DimOffs_DU_3 : 24|4@1+ (1,-5) [-5|5] "Unit_None"  Vector__XXX
 SG_ SI_ICAN : 28|1@1+ (1.0,0.0) [0.0|1] ""  Vector__XXX
 SG_ ZR_Lenkerposition : 29|1@1+ (1.0,0.0) [0.0|1] ""  Vector__XXX
 SG_ WLC1_Systemzustand : 30|1@1+ (1.0,0.0) [0.0|1] ""  Vector__XXX
 SG_ WLC2_Systemzustand : 31|1@1+ (1.0,0.0) [0.0|1] ""  Vector__XXX
 SG_ DI_Screendesign : 32|3@1+ (1.0,0.0) [0.0|7] ""  Kombi
 SG_ ZR_State_DU_4 : 48|3@1+ (1.0,0.0) [0.0|7] ""  Vector__XXX
 SG_ ZR_DimOffs_DU_4 : 51|4@1+ (1,-5) [-5|5] "Unit_None"  Vector__XXX

BO_ 1411 ZV_02: 8 Gateway_Max
 SG_ ZV_verriegeln_Anf : 0|1@1+ (1.0,0.0) [0.0|1] ""  Vector__XXX
 SG_ ZV_STSG_HFS_Anf : 1|1@1+ (1.0,0.0) [0.0|1] ""  Vector__XXX
 SG_ ZV_STSG_HBFS_Anf : 2|1@1+ (1.0,0.0) [0.0|1] ""  Vector__XXX
 SG_ ZV_Anf_Challenge_Auth : 3|1@1+ (1.0,0.0) [0.0|1] ""  Vector__XXX
 SG_ ZV_STSG_Crashzustand : 4|1@1+ (1.0,0.0) [0.0|1] ""  Kombi
 SG_ ZV_STSG_eKiSi_defekt : 5|1@1+ (1.0,0.0) [0.0|1] ""  Kombi
 SG_ ZV_eRWK_Umfeld_Pruefung : 6|1@1+ (1.0,0.0) [0.0|1] ""  Vector__XXX
 SG_ VIP_Sensor_STSG_HFS_betaetigt : 10|1@1+ (1.0,0.0) [0.0|1] ""  Vector__XXX
 SG_ VIP_Sensor_STSG_HBFS_betaetigt : 11|1@1+ (1.0,0.0) [0.0|1] ""  Vector__XXX
 SG_ BCM_FH_Freigabe : 12|1@1+ (1.0,0.0) [0.0|1] ""  Vector__XXX
 SG_ BCM_Komfortfkt_Freigabe : 13|1@1+ (1.0,0.0) [0.0|1] ""  Vector__XXX
 SG_ BCM_HSK_Freigabe : 14|1@1+ (1.0,0.0) [0.0|1] ""  Vector__XXX
 SG_ BCM_Verdeck_Freigabe : 15|1@1+ (1.0,0.0) [0.0|1] ""  Vector__XXX
 SG_ ZV_verriegelt_intern_ist : 16|1@1+ (1.0,0.0) [0.0|1] ""  Vector__XXX
 SG_ ZV_verriegelt_extern_ist : 17|1@1+ (1.0,0.0) [0.0|1] ""  Kombi
 SG_ ZV_verriegelt_intern_soll : 18|1@1+ (1.0,0.0) [0.0|1] ""  Vector__XXX
 SG_ ZV_verriegelt_extern_soll : 19|1@1+ (1.0,0.0) [0.0|1] ""  ELV
 SG_ ZV_gesafet_extern_ist : 20|1@1+ (1.0,0.0) [0.0|1] ""  Vector__XXX
 SG_ ZV_gesafet_extern_soll : 21|1@1+ (1.0,0.0) [0.0|1] ""  ELV
 SG_ ZV_Einzeltuerentriegelung : 22|1@1+ (1.0,0.0) [0.0|1] ""  Vector__XXX
 SG_ ZV_Heckeinzelentriegelung : 23|1@1+ (1.0,0.0) [0.0|1] ""  Vector__XXX
 SG_ ZV_FT_offen : 24|1@1+ (1.0,0.0) [0.0|1] ""  Kombi
 SG_ ZV_BT_offen : 25|1@1+ (1.0,0.0) [0.0|1] ""  Kombi
 SG_ ZV_HFS_offen : 26|1@1+ (1.0,0.0) [0.0|1] ""  Kombi
 SG_ ZV_HBFS_offen : 27|1@1+ (1.0,0.0) [0.0|1] ""  Kombi
 SG_ ZV_HD_offen : 28|1@1+ (1.0,0.0) [0.0|1] ""  Kombi
 SG_ ZV_HS_offen : 29|1@1+ (1.0,0.0) [0.0|1] ""  Kombi
 SG_ IRUE_aktiv : 30|1@1+ (1.0,0.0) [0.0|1] ""  Vector__XXX
 SG_ DWA_aktiv : 31|1@1+ (1.0,0.0) [0.0|1] ""  Vector__XXX
 SG_ HD_Hauptraste : 32|1@1+ (1.0,0.0) [0.0|1] ""  Vector__XXX
 SG_ HD_Vorraste : 33|1@1+ (1.0,0.0) [0.0|1] ""  Vector__XXX
 SG_ FFB_HDF_Taste : 34|1@1+ (1.0,0.0) [0.0|1] ""  Vector__XXX
 SG_ FFB_Panik_Taste : 35|1@1+ (1.0,0.0) [0.0|1] ""  Vector__XXX
 SG_ FFB_Auf_Taste : 36|1@1+ (1.0,0.0) [0.0|1] ""  Vector__XXX
 SG_ FFB_Zu_Taste : 37|1@1+ (1.0,0.0) [0.0|1] ""  Vector__XXX
 SG_ FFB_CarFinder : 38|1@1+ (1.0,0.0) [0.0|1] ""  Vector__XXX
 SG_ FFB_Komfortoeffnen : 39|1@1+ (1.0,0.0) [0.0|1] ""  Vector__XXX
 SG_ FFB_Komfortschliessen : 40|1@1+ (1.0,0.0) [0.0|1] ""  Vector__XXX
 SG_ FBS_IDG_in_Reichweite : 41|1@1+ (1.0,0.0) [0.0|1] ""  Vector__XXX
 SG_ ZV_Schluessel_Zugang : 42|4@1+ (1.0,0.0) [0.0|15] ""  Vector__XXX
 SG_ ZV_SafeFunktion_aktiv : 46|1@1+ (1.0,0.0) [0.0|1] ""  Kombi
 SG_ FBS_Warn_Schluessel_Batt : 47|1@1+ (1.0,0.0) [0.0|1] ""  Kombi
 SG_ ZV_Oeffnungsmodus : 48|2@1+ (1.0,0.0) [0.0|3] ""  Vector__XXX
 SG_ HFS_verriegelt : 50|1@1+ (1.0,0.0) [0.0|1] ""  Vector__XXX
 SG_ HFS_gesafet : 51|1@1+ (1.0,0.0) [0.0|1] ""  Vector__XXX
 SG_ HBFS_verriegelt : 52|1@1+ (1.0,0.0) [0.0|1] ""  Vector__XXX
 SG_ HBFS_gesafet : 53|1@1+ (1.0,0.0) [0.0|1] ""  Vector__XXX
 SG_ ZV_ist_Zustand_verfuegbar : 54|1@1+ (1.0,0.0) [0.0|1] ""  Vector__XXX
 SG_ IRUE_Taster_Fkts_LED : 55|1@1+ (1.0,0.0) [0.0|1] ""  Vector__XXX
 SG_ ZV_Tankklappe_offen : 56|1@1+ (1.0,0.0) [0.0|1] ""  Kombi
 SG_ ZV_Rollo_auf : 57|1@1+ (1.0,0.0) [0.0|1] ""  Vector__XXX
 SG_ ZV_Rollo_zu : 58|1@1+ (1.0,0.0) [0.0|1] ""  Vector__XXX
 SG_ ZV_SAD_auf : 59|1@1+ (1.0,0.0) [0.0|1] ""  Vector__XXX
 SG_ ZV_SAD_zu : 60|1@1+ (1.0,0.0) [0.0|1] ""  Vector__XXX
 SG_ BCM_Tankklappensteller_Fehler : 61|1@1+ (1.0,0.0) [0.0|1] ""  Vector__XXX
 SG_ ZV_verriegelt_soll : 62|2@1+ (1.0,0.0) [0.0|3] ""  Vector__XXX

CM_ BO_ 995 "ab MQB IS5";
CM_ BO_ 1716 "200ms bei D4 und folgende";
CM_ BO_ 916 "ersetzt WBA_02";
CM_ BO_ 1702 "MLBevo";

CM_ SG_ 997 eTAB_FS_Bowdenzug_Auswerfen "Soll den Bowdenzug für die mechanische Redundanz";
CM_ SG_ 997 FS_Push_Tuergriff "Push zum Ausfahren der Flush-Tuergriffe";
CM_ SG_ 997 FS_Status_eTAG_ext "erweitert um den Wert 'verfährt'";
CM_ SG_ 997 FT_ASW_Warnton "erzeugt ein Warnton bei AS Warnung";
CM_ SG_ 997 FT_BFS_Tuer_Status "Gesammelte Türstatusbotschaft";
CM_ SG_ 997 FT_Cargolock_bet "CargoLock-Taste betätigt";
CM_ SG_ 997 FT_HBFS_Tuer_Status "Türstatus mit Fehler und Initwert";
CM_ SG_ 997 FT_HFS_Tuer_Status "Türstatus mit Fehler und Initwert";
CM_ SG_ 997 FT_kisi_asynchron "Signal erzeugt eine seperate Warnmeldung bei ungewollter Asynchronität der 'elektrische Kindersicherung' der Schlösser.";
CM_ SG_ 997 FT_KiSi_Status_Soll_HBFS "Soll KiSi Status HBFS";
CM_ SG_ 997 FT_KiSi_Status_Soll_HFS "Soll Status der KiSi HFS";
CM_ SG_ 997 FT_Kisi_Taster_li_02 "Der Kindersicherungstaster hinten links aktiv.";
CM_ SG_ 997 FT_Kisi_Taster_re_02 "Der Kindersicherungstaster hinten rechts aktiv.";
CM_ SG_ 997 FT_Lock_Taster_02 "Lock-Taster betätigt";
CM_ SG_ 997 FT_Schluesselschalter_zu_02 "Schlüsselschalter für Schließen betätigt";
CM_ SG_ 997 FT_SP_Heizung_ein "Dieses Signal zeigt die tatsächliche Ansteuerung der  Spiegelheizung incl. PWM an. 
Zudem wird aufgrund des Teilnetzbetriebs das Signal zur Ansteuerung der Beifahrer-Spiegelheizung benutzt.

";
CM_ SG_ 997 FT_TCR_Mode_aktiv "Signal zeigt eine aktive mechanische Redundanz am Türschloss an.";
CM_ SG_ 997 FT_TD_Taste_Status "Status Taste für Tankdeckel";
CM_ SG_ 997 FT_Tuer_Status "Tür geöffnet oder Tür geschlossen";
CM_ SG_ 997 FT_Tuer_Status_QBit "Dieses Bit gibt die Zuverlässigkeit des Türkontakts an. Ein auf dieses Bit folgender Fehlereintrag ist mit dem Sender des Bits abzustimmen (gültig ab PPE).";
CM_ SG_ 997 FT_Tueroeffnen_Warnung "Bit wird gesetzt, wenn Tür während der Fahrt geoeffnet werden soll.";
CM_ SG_ 997 SSA_FT_ASW_Status "SmartSensorActor:
Rückmeldung des Status der ASW Anzeige.";
CM_ SG_ 997 TBF_FS_Touch_Event "Touch_Events für Informationen einer Funktionsauslösung auf dem TBF, welche dann für bspw. ein akustisches Signal zentral umgesetzt werden können.";
CM_ SG_ 997 TSG_FS_Spiegel_angeklappt "Funktionsrückmeldung TSG_FS über Spiegelstellung angeklappt";
CM_ SG_ 997 TSG_FT_02_BZ "4bit Botschaftszaehler, wird mit jeder Sendebotschaft inkrementiert";
CM_ SG_ 997 TSG_FT_02_CRC "Für MLB:
'Berechnung siehe Lastenheft 'Kommunikationsabsicherung für FlexRay und CAN''

Ab MQB und MLBevo:
'Berechnung siehe Lastenheft 'End-to-End Kommunikationsabsicherung''

Endwerte siehe Begleitdokument 'S-PDU Kennungsfolgen'";

CM_ SG_ 975 ASW_Warnung_aktiv_HBFS "Abschaltung der Ambientefunktion Tür hinten der Beifahrerseite bei aktiver ASW Warnung an der Fahrertür";
CM_ SG_ 975 HBFS_FH_Bew_hoch "HBFS Fenster bewegt sich in Richtung hoch";
CM_ SG_ 975 HBFS_FH_Bew_tief "HBFS Fenster bewegt sich in Richtung tief";
CM_ SG_ 975 HBFS_FH_Block "Fensterscheibe befindet sich im mechanischen Block (oben oder unten)";
CM_ SG_ 975 HBFS_FH_Fang "Fangbereich ist 4mm von oberer Lippendichtung";
CM_ SG_ 975 HBFS_FH_normiert "Die Position der Fensterheberscheibe ist bekannt.";
CM_ SG_ 975 HBFS_FH_Oeffnung "Gibt den Fensteröffnungswert in % an.";
CM_ SG_ 975 HBFS_FH_S_AutoHoch "Betaetigung FH Schalter auto tief ";
CM_ SG_ 975 HBFS_FH_S_AutoTief "Betaetigung FH Schalter auto hoch";
CM_ SG_ 975 HBFS_FH_S_HFS_AutoHoch "Automatisches Hochfahren der Seitenscheibe HFS";
CM_ SG_ 975 HBFS_FH_S_HFS_AutoTief "Automatisches Absenken der Seitenscheibe HFS";
CM_ SG_ 975 HBFS_FH_S_HFS_ManHoch "Manuelles Hochfahren der Seitenscheibe HFS";
CM_ SG_ 975 HBFS_FH_S_HFS_ManTief "Manuelles Absenken der Seitenscheibe HFS";
CM_ SG_ 975 HBFS_FH_S_ManHoch "Betaetigung FH Schalter man hoch ";
CM_ SG_ 975 HBFS_FH_S_ManTief "Betaetigung FH Schalter man tief";
CM_ SG_ 975 HBFS_FH_Thermo "gibt an ob Fensterheber im Thermoschutz ist";
CM_ SG_ 975 HBFS_gesafet "HBFS Tuer gesafet.
Im Zustand Safe wird auch das Signal HBFS_verriegelt = 1 gesendet.";
CM_ SG_ 975 HBFS_Heckrollotaster_betaetigt "Verfahren des Heckrollos in Richtung Hoch

Bei Einfachtaster wird Bit als Togglebit verwendet (Heckrollo hoch, tief)";
CM_ SG_ 975 HBFS_Lock_Taster "Betaetigung Lock-Taster";
CM_ SG_ 975 HBFS_Lock_Taster_inv "Lock Taster nicht betätigt";
CM_ SG_ 975 HBFS_MRollo_Schalter "  | MRollo2
-----------------------------
0 | nicht_betaetigt
1 | (m) Zu
2 | (a) Zu
3 | (m) Auf
4 | (a) Auf
5 | Schalter nicht verfuegbar
6 | Init
7 | Fehlerfall";
CM_ SG_ 975 HBFS_Oben_Block_erw "Fensterheber in Blockerwartung oben";
CM_ SG_ 975 HBFS_SAD_Schalter "  |   Ausstelldach MD3
-----------------------------
0 | nicht_betaetigt
1 |
2 |
3 |
4 |
5 | (m) Auf
6 | (a) Auf
7 | (m) Zu
8 | (a) Zu
13| Schalter nicht verfuegbar
14| Init
15| Fehlerfall";
CM_ SG_ 975 HBFS_Seitenrollo_tief "Seitenrollo in Bewegung Richtung tief";
CM_ SG_ 975 HBFS_SK_betaetigt "Status der Sperrklinke";
CM_ SG_ 975 HBFS_Sperrklinke "Vorraste für Schloß

zwischen Vor- und Hauptraste Signal kurz auf 1, danach wieder auf 0 wenn Tür in Hauptraste (Tür ist sicher zu wenn Sperrklinke und Türkontakt auf 0 sind)";
CM_ SG_ 975 HBFS_Status_eTAG "Status des elektrischen Tueraussengriffes Tuer Beifahrerseite hinten";
CM_ SG_ 975 HBFS_Status_KiSi "Status Kindersicherung HBFS
";
CM_ SG_ 975 HBFS_Status_KiSi_inv "Inverser Status der elektrischen Kindersicherung Beifahrerseite hinten";
CM_ SG_ 975 HBFS_TAG_betaetigt "Betaetigung Türaussengriff";
CM_ SG_ 975 HBFS_TIG_betaetigt "Betaetigung Tuerinnengriff";
CM_ SG_ 975 HBFS_TIG_betaetigt_oeffnen "Türinnenbetätigung, Taster Tür öffnen.";
CM_ SG_ 975 HBFS_TIG_betaetigt_schliessen "Türinnenbetätigung, Taster Tür schließen.";
CM_ SG_ 975 HBFS_Tuer_geoeffnet "HBFS Tuer geoeffnet";
CM_ SG_ 975 HBFS_Tuer_Status "Türstatus mit Fehler und Initwert";
CM_ SG_ 975 HBFS_Tuer_Status_QBit "Dieses Bit gibt die Zuverlässigkeit des Türkontakts an. Ein auf dieses Bit folgender Fehlereintrag ist mit dem Sender des Bits abzustimmen (gültig ab PPE).";
CM_ SG_ 975 HBFS_Tueroeffnen_Warnung "Bit wird gesetzt, wenn Tür während der Fahrt geoeffnet werden soll.";
CM_ SG_ 975 HBFS_Tuerschloss_defekt "Das hintere Tuerschloss auf der Beifahrerseite ist nicht mehr funktionsfähig.";
CM_ SG_ 975 HBFS_UEKB_aktiviert "Überschutzbegrenzungskraft bei Reversieren";
CM_ SG_ 975 HBFS_Unlock_Taster "Betaetigung Unlock Taster";
CM_ SG_ 975 HBFS_Unten_Block_erw "Fensterheber in Blockerwartung unten";
CM_ SG_ 975 HBFS_verriegelt "Verriegelungsstatus Tür";
CM_ SG_ 975 HBFS_Vorraste_betaetigt "Status der Vorraste";
CM_ SG_ 975 HBFS_Zuziehhilfe_aktiv "Zuziehhilfe aktiv";
CM_ SG_ 975 MTHBFS_M_Taste "Betätigung M-Taste HBFS";
CM_ SG_ 975 MTHBFS_Pos1 "Betätigung Postionstaste 1 HBFS";
CM_ SG_ 975 MTHBFS_Pos2 "Betätigung Postionstaste 2 HBFS
";
CM_ SG_ 975 MTHBFS_Pos3 "Betätigung Postionstaste 3 HBFS";
CM_ SG_ 975 SSR_HBFS_Pos_Unten "Signal für die 'Global Close'. Über dieses Bit wissen die anderen TSGs, ob der SSR oder der FH verfahren werden darf.";

CM_ SG_ 974 ASW_Warnung_aktiv_HFS "Abschaltung der Ambientefunktion Tür hinten der Fahrerseite bei aktiver ASW Warnung an der Fahrertür";
CM_ SG_ 974 HFS_FH_Bew_hoch "HFS Fenster bewegt sich in Richtung hoch";
CM_ SG_ 974 HFS_FH_Bew_tief "HFS Fenster bewegt sich in Richtung tief";
CM_ SG_ 974 HFS_FH_Block "Fensterscheibe befindet sich im mechanischen Block (oben oder unten)";
CM_ SG_ 974 HFS_FH_Fang "Fangbereich ist 4mm von oberer Lippendichtung";
CM_ SG_ 974 HFS_FH_normiert "Die Position der Fensterheberscheibe ist bekannt.";
CM_ SG_ 974 HFS_FH_Oeffnung "Gibt den Fensteröffnungswert in % an.";
CM_ SG_ 974 HFS_FH_S_AutoHoch "Betaetigung FH Schalter auto hoch";
CM_ SG_ 974 HFS_FH_S_AutoTief "Betaetigung FH Schalter auto tief ";
CM_ SG_ 974 HFS_FH_S_HBFS_AutoHoch "Automatisches Hochfahren der Seitenscheibe HBFS";
CM_ SG_ 974 HFS_FH_S_HBFS_AutoTief "Automatisches Absenken der Seitenscheibe HBFS";
CM_ SG_ 974 HFS_FH_S_HBFS_ManHoch "Manuelles Hochfahren der Seitenscheibe HBFS";
CM_ SG_ 974 HFS_FH_S_HBFS_ManTief "Manuelles Absenken der Seitenscheibe HBFS";
CM_ SG_ 974 HFS_FH_S_ManHoch "Betaetigung FH Schalter man hoch ";
CM_ SG_ 974 HFS_FH_S_ManTief "Betaetigung FH Schalter man tief";
CM_ SG_ 974 HFS_FH_Thermo "gibt an ob Fensterheber im Thermoschutz ist";
CM_ SG_ 974 HFS_gesafet "HFS Tuer gesafet.
Im Zustand Safe wird auch das Signal HFS_verriegelt = 1 gesendet.";
CM_ SG_ 974 HFS_Heckrollotaster_betaetigt "Verfahren des Heckrollos in Richtung Hoch

Bei Einfachtaster wird Bit als Togglebit verwendet (Heckrollo hoch, tief)";
CM_ SG_ 974 HFS_Lock_Taster "Betätigung Lock-Taster";
CM_ SG_ 974 HFS_Lock_Taster_inv "Lock Taster nicht betätigt";
CM_ SG_ 974 HFS_MRollo_Schalter "  | MRollo2
-----------------------------
0 | nicht_betaetigt
1 | (m) Zu
2 | (a) Zu
3 | (m) Auf
4 | (a) Auf
5 | Schalter nicht verfuegbar
6 | Init
7 | Fehlerfall";
CM_ SG_ 974 HFS_Oben_Block_erw "Fensterheber in Blockerwartung oben";
CM_ SG_ 974 HFS_SAD_Schalter "  |   Ausstelldach MD3
-----------------------------
0 | nicht_betaetigt
1 |
2 |
3 |
4 |
5 | (m) Auf
6 | (a) Auf
7 | (m) Zu
8 | (a) Zu
13| Schalter nicht verfuegbar
14| Init
15| Fehlerfall";
CM_ SG_ 974 HFS_Seitenrollo_hoch "Seitenrollo in Bewegung Richtung hoch";
CM_ SG_ 974 HFS_Seitenrollo_tief "Seitenrollo in Bewegung Richtung tief";
CM_ SG_ 974 HFS_SK_betaetigt "Status der Sperrklinke";
CM_ SG_ 974 HFS_Sperrklinke "Vorraste für Schloß

zwischen Vor- und Hauptraste Signal kurz auf 1, danach wieder auf 0 wenn Tür in Hauptraste (Tür ist sicher zu wenn Sperrklinke und Türkontakt auf 0 sind)";
CM_ SG_ 974 HFS_Status_eTAG "Status des elektrischen Tueraussengriffes Tuer Fahrerseite hinten";
CM_ SG_ 974 HFS_Status_KiSi "Status Kindersicherung hinten Fahrerseite";
CM_ SG_ 974 HFS_TAG_betaetigt "Betaetigung Türaussengriff";
CM_ SG_ 974 HFS_TCR_Mode_aktiv "Signal zeigt eine aktive mechanische Redundanz am Türschloss an.";
CM_ SG_ 974 HFS_TIG_betaetigt "Betaetigung Türinnengriff";
CM_ SG_ 974 HFS_TIG_betaetigt_oeffnen "Türinnenbetätigung, Taster Tür öffnen.";
CM_ SG_ 974 HFS_TIG_betaetigt_schliessen "Türinnenbetätigung, Taster Tür schließen.";
CM_ SG_ 974 HFS_Tuer_geoeffnet "HFS Tuer geoeffnet";
CM_ SG_ 974 HFS_Tuer_Status "Türstatus mit Fehler und Initwert";
CM_ SG_ 974 HFS_Tuer_Status_QBit "Dieses Bit gibt die Zuverlässigkeit des Türkontakts an. Ein auf dieses Bit folgender Fehlereintrag ist mit dem Sender des Bits abzustimmen (gültig ab PPE).";
CM_ SG_ 974 HFS_Tueroeffnen_Warnung "Bit wird gesetzt, wenn Tür während der Fahrt geoeffnet werden soll.";
CM_ SG_ 974 HFS_Tuerschloss_defekt "Das hintere Tuerschloss auf der Fahrerseite ist nicht mehr funktionsfähig.";
CM_ SG_ 974 HFS_UEKB_aktiviert "Überschutzbegrenzungskraft bei Reversieren";
CM_ SG_ 974 HFS_Unlock_Taster "Betaetigung Unlock Taster";
CM_ SG_ 974 HFS_Unten_Block_erw "Fensterheber in Blockerwartung unten";
CM_ SG_ 974 HFS_verriegelt "HFS Tuer verriegelt";
CM_ SG_ 974 HFS_Vorraste_betaetigt "Status der Vorraste";
CM_ SG_ 974 HFS_Zuziehhilfe_aktiv "Zuziehhilfe aktiv";
CM_ SG_ 974 MTHFS_M_Taste "Betätigung M-Taste HFS";
CM_ SG_ 974 MTHFS_Pos1 "Betätigung Postionstaste 1 HFS";
CM_ SG_ 974 MTHFS_Pos2 "Betätigung Postionstaste 2 HFS
";
CM_ SG_ 974 MTHFS_Pos3 "Betätigung Postionstaste 3 HFS";
CM_ SG_ 974 SSR_HFS_Pos_Unten "Signal für die 'Global Close'. Über dieses Bit wissen die anderen TSGs, ob der SSR oder der FH verfahren werden darf.";

CM_ SG_ 2589283772 QSP_Temperatur_Oel "Aktuelle Hydrauli-Oel-Temperatur";
CM_ SG_ 2589283772 QSP_Thermische_Belastung "Maximale aktuelle thermische Belastung des Gesamtsystems (Motor, ECU, Kupplungen)";
CM_ SG_ 2589283772 QSP_Warnlampe "Status der Warnlampe: aktuell anliegender Fehlerzustand";
CM_ SG_ 2589283772 TSL_Hinweis "Anzeige eines Textes, der auf Funktionsdegradierung hinweist, aber nicht zum Besuch der Werktstatt auffordert";
CM_ SG_ 2589283772 TSL_Warnung "Systemausfall mit Kundenwarnung";

CM_ SG_ 2589283773 TSR_Hinweis "Anzeige eines Textes, der auf Funktionsdegradierung hinweist, aber nicht zum Besuch der Werkstatt auffordert";
CM_ SG_ 2589283773 TSR_Temperatur_Oel "Aktuelle Hydrauli-Oel-Temperatur";
CM_ SG_ 2589283773 TSR_Thermische_Belastung "Maximale aktuelle thermische Belastung des Gesamtsystems (Motor, ECU, Kupplungen)";
CM_ SG_ 2589283773 TSR_Warnlampe "Status der Warnlampe: aktuell anliegender Fehlerzustand";
CM_ SG_ 2589283773 TSR_Warnung "Systemausfall mit Kundenwarnung";

CM_ SG_ 1718 UH_Minute "0x3C- 0x3f = Werte ungültig";
CM_ SG_ 1718 UH_Monat "0x0D, 0xF =  Werte ungültig
0x0E = Relatives Datum (nur VW)";
CM_ SG_ 1718 UH_Sekunde "0x3C- 0x3f = Werte ungültig";
CM_ SG_ 1718 UH_Stunde "0x18 - 0x1F = Werte ungültig";
CM_ SG_ 1718 UH_Tag "0x0: reserviert bei VW";
CM_ SG_ 1718 UH_Typ "0x4 - 0x7 = tbd. ";

CM_ SG_ 995 VD_SpannungsAnf "Anforderung Forderung des Verdecks zur Spannungsanhebung des Bordnetzes.";
CM_ SG_ 995 VS_BFS_AutoHoch "automatischer Hochlauf des BFS Fenster ausgelöst durch die Verdecksteuerung";
CM_ SG_ 995 VS_BFS_AutoTief "automatischer Tieflauf des BFS Fenster ausgelöst durch die Verdecksteuerung";
CM_ SG_ 995 VS_BFS_ManHoch "manueller Hochlauf des BFS Fenster ausgelöst durch die Verdecksteuerung";
CM_ SG_ 995 VS_BFS_ManTief "manueller Tieflauf des BFS Fenster ausgelöst durch die Verdecksteuerung";
CM_ SG_ 995 VS_Buzzer "Buzzeransteuerung: 'Buzzeransteuerung' für Gong 200ms (Kombi)";
CM_ SG_ 995 VS_FH_BT_Langhub "Ansteuerung Fensterheber vom Verdecksteuergeraet";
CM_ SG_ 995 VS_FH_FT_Langhub "Ansteuerung Fensterheber vom Verdecksteuergeraet";
CM_ SG_ 995 VS_FH_HBFS_Langhub "Ansteuerung Fensterheber vom Verdecksteuergeraet";
CM_ SG_ 995 VS_FH_HFS_Langhub "Ansteuerung Fensterheber vom Verdecksteuergeraet";
CM_ SG_ 995 VS_FS_AutoHoch "automatischer Hochlauf des FS Fenster ausgelöst durch die Verdecksteuerung";
CM_ SG_ 995 VS_FS_AutoTief "automatischer Tieflauf des FS Fenster ausgelöst durch die Verdecksteuerung";
CM_ SG_ 995 VS_FS_ManHoch "manueller Hochlauf des FS Fenster ausgelöst durch die Verdecksteuerung";
CM_ SG_ 995 VS_FS_ManTief "manueller Tieflauf des FS Fenster ausgelöst durch die Verdecksteuerung";
CM_ SG_ 995 VS_Hardtop "Hardtop montiert";
CM_ SG_ 995 VS_HBFS_AutoHoch "automatischer Hochlauf des HBFS Fenster ausgelöst durch die Verdecksteuerung";
CM_ SG_ 995 VS_HBFS_AutoTief "automatischer Tieflauf des HBFS Fenster ausgelöst durch die Verdecksteuerung";
CM_ SG_ 995 VS_HBFS_ManHoch "manueller Hochlauf des HBFS Fenster ausgelöst durch die Verdecksteuerung";
CM_ SG_ 995 VS_HBFS_ManTief "manueller Tieflauf des HBFS Fenster ausgelöst durch die Verdecksteuerung";
CM_ SG_ 995 VS_HD_sperren "Bei gesetztem Signal wird der Kofferraum/Heckdeckel durch den BCM2 nicht entriegelt werden.";
CM_ SG_ 995 VS_Heckschloss_auf "Signal wird gesetzt, wenn fuer einen Verdeckbetrieb das Öffnen des Heckschlosses erforderlich ist.";
CM_ SG_ 995 VS_HFS_AutoHoch "automatischer Hochlauf des HFS Fenster ausgelöst durch die Verdecksteuerung";
CM_ SG_ 995 VS_HFS_AutoTief "automatischer Tieflauf des HFS Fenster ausgelöst durch die Verdecksteuerung";
CM_ SG_ 995 VS_HFS_ManHoch "manueller Hochlauf des HFS Fenster ausgelöst durch die Verdecksteuerung";
CM_ SG_ 995 VS_HFS_ManTief "manueller Tieflauf des HFS Fenster ausgelöst durch die Verdecksteuerung";
CM_ SG_ 995 VS_HHS_enable "Fehlende Beschreibung (Import)";
CM_ SG_ 995 VS_Lampe_Blk "Ansteuerung Lampe im Kombi

Wird aktiviert bei Aufprüfen, Verdecklauf und Fehlerfall (blinkend).


";
CM_ SG_ 995 VS_StartStopp_Info "Stopp-Freigabe und Start-Anforderung an den Start-Stopp-Koordinator";
CM_ SG_ 995 VS_VD_Bew_auf "



";
CM_ SG_ 995 VS_VD_Bew_zu "


";
CM_ SG_ 995 VS_VD_entriegelt "Zustand des Verdeck entriegelt";
CM_ SG_ 995 VS_VD_Fehler "Fehlerzustand Verdeck";
CM_ SG_ 995 VS_VD_offen_ver "Zustand des Verdecks verriegelt und offen";
CM_ SG_ 995 VS_VD_zu_ver "
";
CM_ SG_ 995 VS_VD_Zwischenposition "Verdeck in Zwischenposition";
CM_ SG_ 995 VS_VDKD_auf "Signal wird gesetzt, wenn der Verdeckkastendeckel vollstaendig geoeffnet ist



";
CM_ SG_ 995 VS_Verdeck_Anf "Verdeckanforderung (Signalisierung der Bereitschaft zur Verdeckbetaetigung ueber Komfortfunktion)";
CM_ SG_ 995 VS_Windschott_nicht_abgelegt "Windschott ist aufgestellt, in Zwischenposition oder die Position ist unbekannt";
CM_ SG_ 995 VSG_Meldungen "Meldungen fuers Kombi lt. konzernübergreifender Abstimmung

0 -> keine Meldung
1 -> 'Verdeckbetrieb RDW aktiv'
2 -> 'Verdeckbetrieb NAR aktiv'
3 -> 'stehendes Verdeck in Zwischenposition (ZP)'
4 -> 'autom. Verdeck in ZP und KL15 aus'
5 -> 'manuelle";

CM_ SG_ 1716 VIN_01_MUX "Achtung:
Die Botschaft ist nicht linear gemultiplext!!!
Sondern 0,1,0,2,0, usw.";
CM_ SG_ 1716 VIN_1 "Initwert:
0x2D bei Fahrzeugen mit Wegfahrsperrengeneration >= 5 
0x58 bei Fahrzeugen mit Wegfahrsperrengeneration < 5 (z.B. WFS-4)";
CM_ SG_ 1716 VIN_10 "Initwert:
0x2D bei Fahrzeugen mit Wegfahrsperrengeneration >= 5 
0x58 bei Fahrzeugen mit Wegfahrsperrengeneration < 5 (z.B. WFS-4)";
CM_ SG_ 1716 VIN_11 "Initwert:
0x2D bei Fahrzeugen mit Wegfahrsperrengeneration >= 5 
0x58 bei Fahrzeugen mit Wegfahrsperrengeneration < 5 (z.B. WFS-4)";
CM_ SG_ 1716 VIN_12 "Initwert:
0x2D bei Fahrzeugen mit Wegfahrsperrengeneration >= 5 
0x58 bei Fahrzeugen mit Wegfahrsperrengeneration < 5 (z.B. WFS-4)";
CM_ SG_ 1716 VIN_13 "Initwert:
0x2D bei Fahrzeugen mit Wegfahrsperrengeneration >= 5 
0x58 bei Fahrzeugen mit Wegfahrsperrengeneration < 5 (z.B. WFS-4)";
CM_ SG_ 1716 VIN_14 "Initwert:
0x2D bei Fahrzeugen mit Wegfahrsperrengeneration >= 5 
0x58 bei Fahrzeugen mit Wegfahrsperrengeneration < 5 (z.B. WFS-4)";
CM_ SG_ 1716 VIN_15 "Initwert:
0x2D bei Fahrzeugen mit Wegfahrsperrengeneration >= 5 
0x58 bei Fahrzeugen mit Wegfahrsperrengeneration < 5 (z.B. WFS-4)";
CM_ SG_ 1716 VIN_16 "Initwert:
0x2D bei Fahrzeugen mit Wegfahrsperrengeneration >= 5 
0x58 bei Fahrzeugen mit Wegfahrsperrengeneration < 5 (z.B. WFS-4)";
CM_ SG_ 1716 VIN_17 "Initwert:
0x2D bei Fahrzeugen mit Wegfahrsperrengeneration >= 5 
0x58 bei Fahrzeugen mit Wegfahrsperrengeneration < 5 (z.B. WFS-4)";
CM_ SG_ 1716 VIN_2 "Initwert:
0x2D bei Fahrzeugen mit Wegfahrsperrengeneration >= 5 
0x58 bei Fahrzeugen mit Wegfahrsperrengeneration < 5 (z.B. WFS-4)";
CM_ SG_ 1716 VIN_3 "Initwert:
0x2D bei Fahrzeugen mit Wegfahrsperrengeneration >= 5 
0x58 bei Fahrzeugen mit Wegfahrsperrengeneration < 5 (z.B. WFS-4)";
CM_ SG_ 1716 VIN_4 "Initwert:
0x2D bei Fahrzeugen mit Wegfahrsperrengeneration >= 5 
0x58 bei Fahrzeugen mit Wegfahrsperrengeneration < 5 (z.B. WFS-4)";
CM_ SG_ 1716 VIN_5 "Initwert:
0x2D bei Fahrzeugen mit Wegfahrsperrengeneration >= 5 
0x58 bei Fahrzeugen mit Wegfahrsperrengeneration < 5 (z.B. WFS-4)";
CM_ SG_ 1716 VIN_6 "Initwert:
0x2D bei Fahrzeugen mit Wegfahrsperrengeneration >= 5 
0x58 bei Fahrzeugen mit Wegfahrsperrengeneration < 5 (z.B. WFS-4)";
CM_ SG_ 1716 VIN_7 "Initwert:
0x2D bei Fahrzeugen mit Wegfahrsperrengeneration >= 5 
0x58 bei Fahrzeugen mit Wegfahrsperrengeneration < 5 (z.B. WFS-4)";
CM_ SG_ 1716 VIN_8 "Initwert:
0x2D bei Fahrzeugen mit Wegfahrsperrengeneration >= 5 
0x58 bei Fahrzeugen mit Wegfahrsperrengeneration < 5 (z.B. WFS-4)";
CM_ SG_ 1716 VIN_9 "Initwert:
0x2D bei Fahrzeugen mit Wegfahrsperrengeneration >= 5 
0x58 bei Fahrzeugen mit Wegfahrsperrengeneration < 5 (z.B. WFS-4)";

CM_ SG_ 1057 VLK_01_BZ "4bit Botschaftszähler, wird mit jeder Sendebotschaft inkrementiert";
CM_ SG_ 1057 VLK_01_CRC "Für MLB:
Berechnung siehe Lastenheft 'Kommunikationsabsicherung für FlexRay und CAN'
Ab MQB und MLBevo:
Berechnung siehe Lastenheft 'End-to-End Kommunikationsabsicherung'

Endwerte siehe Begleitdokument 'S-PDU Kennungsfolgen'";
CM_ SG_ 1057 VLK_Anf_Antrieb "Anforderung zur Antriebsfreigabe seitens VLK";
CM_ SG_ 1057 VLK_Anforderung_HMS "Halteanforderung des VLK an HMS aus Funktion Rollsicherung";
CM_ SG_ 1057 VLK_Anforderung_Rollfaehigkeit "Mit diesem Signal wird vom Verlassenskonzept signalisiert, ob der Rollfähigkeitsmodus aktiviert ist.";
CM_ SG_ 1057 VLK_Antriebsdeaktivierung "VLK kann mit diesem Signal den Antrieb deaktivieren.";
CM_ SG_ 1057 VLK_autom_Absch_Signalisierung "Signalisierung einer automatisierten Deaktivierung der Zündung";
CM_ SG_ 1057 VLK_Hinweis_dgr_VLW "Dieses Signal fordert im Kombi die Meldung an, die den Fahrer auffordert das Fahrzeug nur in Fahrstufe P zu verlassen. 
Notwendig wenn aufgrund fehlerhafter Eingangssignale keine automatische Sicherung erfolgt";
CM_ SG_ 1057 VLK_Hinweis_Fehler_Gurt "Dieses Signal fordert im Kombi die Meldung an, die den Fahrer über ein defektes Gurtschloss (Fahrergurt) informiert.";
CM_ SG_ 1057 VLK_Hinweis_Fehler_Sitz "Dieses Signal fordert im Kombi die Meldung an, die den Fahrer über eine defekte Sitzbelegungserkennung (Fahrersitz) informiert.";
CM_ SG_ 1057 VLK_Hinweis_Fehler_Tuer "Dieses Signal fordert im Kombi die Meldung an, die den Fahrer über einen defekten Türkontaktschalter (Fahrertür) informiert.";
CM_ SG_ 1057 VLK_Hinweis_KA_bevorstehend "Dieses Signal fordert im Kombi die Meldung an, die den Fahrer auf eine bevorstehende Komforabschaltung hinweist.";
CM_ SG_ 1057 VLK_Hinweis_Rollfaehigkeit "Im Signal wird die Meldungsausgabe des Rollfähigkeitsmodus im iID mit bzw. ohne Akustik angefordert";
CM_ SG_ 1057 VLK_Hinweis_Weiterfahrt "Dieses Signal fordert im Kombi die Meldung an, die den Fahrer auf eine Bedienhandlung zur Weiterfahrt hinweist.";
CM_ SG_ 1057 VLK_Parken_beibehalten_HMS "Anforderung durch das Verlassenskonzept, um das Lösen der Parkbremse zu verhindern.";
CM_ SG_ 1057 VLK_VLW_Anf "Anforderndes Signal der Verlassenswarnung für Fahrzeuge auf technischer Basis MEB. Aufgrund des nicht verbauten Getriebes sind die Signalwerte um die Ersatzreaktionen auf ein fehlerhaftes p_verriegelt reduziert. Ausgabe der Verlassenswarnung erfolgt im Fa";

CM_ SG_ 2463978663 VZE_Akustik_Limitwechsel "Anforderung eines Signaltons bei Tempolimitwechsel.";
CM_ SG_ 2463978663 VZE_Akustik_Limitwechsel_Status "Das Signal überträgt die Information, ob der Kunde, in den Einstellungen, die akustische Information, bei einem Tempolimitwechsel, ausgewählt hat.";
CM_ SG_ 2463978663 VZE_Anhaenger_Vmax "Übertragung der aus Kundeneinstellung und länderspezifischen Regelungen (StVO, Rechtsprechung...) berechneten legalen Höchstgeschwindigkeit für das Gespann.

10+ 0*10 = 10 km/h
10+ 1*10 = 20 km/h
...
10+ 5*10 = 60 km/h
10+ 6*10 = 70 km/h
...
10+ 1";
CM_ SG_ 2463978663 VZE_Anzeige_VZ_1 "Das Signal spiegelt eines der Verkehrszeichen: Geschwindigkeitsgebot, Überholverbot, Aufhebungszeichen wider.

Wertebereich lt. Hashtabelle";
CM_ SG_ 2463978663 VZE_Anzeige_VZ_2 "Das Signal spiegelt eines der Verkehrszeichen: Geschwindigkeitsgebot, Überholverbot, Aufhebungszeichen wider.

Wertebereich lt. Hashtabelle";
CM_ SG_ 2463978663 VZE_Anzeige_VZ_3 "Das Signal spiegelt eines der Verkehrszeichen: Geschwindigkeitsgebot, Überholverbot, Aufhebungszeichen wider.

Wertebereich lt. Hashtabelle";
CM_ SG_ 2463978663 VZE_Anzeige_ZS_1 "Zusatzsschild, das zu Verkehrszeichen 1 angezeigt werden soll.

Wertebereich lt. Hashtabelle";
CM_ SG_ 2463978663 VZE_Anzeige_ZS_2 "Zusatzsschild, das zu Verkehrszeichen 1 angezeigt werden soll.

Wertebereich lt. Hashtabelle";
CM_ SG_ 2463978663 VZE_Anzeige_ZS_3 "Zusatzsschild, das zu Verkehrszeichen 1 angezeigt werden soll.

Wertebereich lt. Hashtabelle";
CM_ SG_ 2463978663 VZE_Anzeigemodus "Steuert die verschiedenen Möglichkeiten der Anzeige.";
CM_ SG_ 2463978663 VZE_Anzeigeunterdrueck_Zeichen_1 "Steuerungssignal zur Steuerung der Sichtbarkeit von Verkehrszeichen ";
CM_ SG_ 2463978663 VZE_Anzeigeunterdrueck_Zeichen_2 "Anzeigerelevanz des Zeichens in VZE_Verkehrszeichen_2";
CM_ SG_ 2463978663 VZE_Anzeigeunterdrueck_Zeichen_3 "Anzeigerelevanz des Zeichens in VZE_Verkehrszeichen_3";
CM_ SG_ 2463978663 VZE_Anzeigeunterdrueck_Zeichen_4 "Anzeigerelevanz des Zeichens in VZE_Anzeigerelevanz_Zeichen_4";
CM_ SG_ 2463978663 VZE_Anzeigeunterdrueck_Zeichen_5 "Anzeigerelevanz des Zeichens in VZE_Anzeigerelevanz_Zeichen_5";
CM_ SG_ 2463978663 VZE_Baustelle "Das Signal gibt an, ob aktuell ein Baustellenschild von der VZE erkannt wurde.";
CM_ SG_ 2463978663 VZE_Erweiterte_Information "In dem Signal spiegelt erweiterte Verkehrszeicheninformationen wieder (Ortsschild, Autobahnbeginn, Autobahnende)

Wertebereich lt. Hashtabelle";
CM_ SG_ 2463978663 VZE_FoD_Status "Status der VZE für FoD";
CM_ SG_ 2463978663 VZE_Gong "Das Signal signalisiert dem Kombiinstrument ob bei der VZE-Tempowarnung ein Gong getriggert werden soll.";
CM_ SG_ 2463978663 VZE_Hinweistext "Über Index wird ein Hinweistext beschrieben, der durch das Kombi dargestellte werden soll.

Wertebereich lt. Hashtabelle";
CM_ SG_ 2463978663 VZE_Hinweistext_03 "Über Index wird ein Hinweistext beschrieben, der durch das Kombi dargestellte werden soll.

Wertebereich lt. Hashtabelle";
CM_ SG_ 2463978663 VZE_Land "Steuert die verschiedenen Möglichkeiten der Anzeige.";
CM_ SG_ 2463978663 VZE_Modus_OptischeWarnung "Das Signal gibt an, ob eine optische Warnung blinkend oder dauerhaft ausgegeben werden soll.";
CM_ SG_ 2463978663 VZE_SLWF_Status "Das Signal zeigt den SLWF Zustand der VZE an.";
CM_ SG_ 2463978663 VZE_Tempowarnung_Einheit "0 - Einheit Warnoffset km/h
1 -  Einheit Warnoffset mph";
CM_ SG_ 2463978663 VZE_Tempowarnung_Offset "das Signal überträgt den im CAR:Menü gewählten Offset für die VZE-Tempowarnung an das pACC Steuergerät. Die zugrhörige Einheit wird im Signal VZE_Tempowarnung_Einheit übertragen";
CM_ SG_ 2463978663 VZE_Tempowarnung_Status "0 - Tempowarnung aktiv
1 -  Tempowarnung desktiv";
CM_ SG_ 2463978663 VZE_Umweltinfo_Anhaengerbetrieb "In dem Signal werden für die Verkehrszeichenerkennung relevante Umweltinformationen übertragen.

Info: Anhängerbetrieb";
CM_ SG_ 2463978663 VZE_Umweltinfo_Naesse "In dem Signal werden für die Verkehrszeichenerkennung relevante Umweltinformationen übertragen.

Info: Nässe";
CM_ SG_ 2463978663 VZE_Umweltinfo_Nebel "In dem Signal werden für die Verkehrszeichenerkennung relevante Umweltinformationen übertragen.

Info: Nebel";
CM_ SG_ 2463978663 VZE_Verkehrszeichen_1 "Das Signal spiegelt eines der Verkehrszeichen: Geschwindigkeitsgebot, Überholverbot, Aufhebungszeichen wider.

Wertebereich lt. Hashtabelle";
CM_ SG_ 2463978663 VZE_Verkehrszeichen_2 "Das Signal spiegelt eines der Verkehrszeichen: Geschwindigkeitsgebot, Überholverbot, Aufhebungszeichen wider.

Wertebereich lt. Hashtabelle";
CM_ SG_ 2463978663 VZE_Verkehrszeichen_3 "Das Signal spiegelt eines der Verkehrszeichen: Geschwindigkeitsgebot, Überholverbot, Aufhebungszeichen wider.

Wertebereich lt. Hashtabelle";
CM_ SG_ 2463978663 VZE_Verkehrszeichen_4 "Das Signal spiegelt eines der Verkehrszeichen: Geschwindigkeitsgebot, Überholverbot, Aufhebungszeichen wider.

Wertebereich lt. Hashtabelle";
CM_ SG_ 2463978663 VZE_Verkehrszeichen_5 "Das Signal spiegelt eines der Verkehrszeichen: Geschwindigkeitsgebot, Überholverbot, Aufhebungszeichen wider.

Wertebereich lt. Hashtabelle";
CM_ SG_ 2463978663 VZE_Verkehrszeichen_6 "Das Signal spiegelt eines der Verkehrszeichen: Geschwindigkeitsgebot, Überholverbot, Aufhebungszeichen wider.

Wertebereich lt. Hashtabelle";
CM_ SG_ 2463978663 VZE_Verkehrszeichen_Einheit "Signal gibt an ob das übertragene Verkehrszeichen in mph oder km/h übermittelt wird";
CM_ SG_ 2463978663 VZE_Warnung_Verkehrszeichen_1 "Ist das Signal gesetzt, so ist für das Verkehrszeichen 1 eine Warnung auszugeben.";
CM_ SG_ 2463978663 VZE_Warnung_Verkehrszeichen_2 "Ist das Signal gesetzt, so ist für das Verkehrszeichen 2 eine Warnung auszugeben.";
CM_ SG_ 2463978663 VZE_Warnung_Verkehrszeichen_3 "Ist das Signal gesetzt, so ist für das Verkehrszeichen 3 eine Warnung auszugeben.";
CM_ SG_ 2463978663 VZE_Warnung_Verkehrszeichen_4 "Ist das Signal gesetzt, so ist für das Verkehrszeichen 4 eine Warnung auszugeben.";
CM_ SG_ 2463978663 VZE_Warnung_Verkehrszeichen_5 "Ist das Signal gesetzt, so ist für das Verkehrszeichen 5 eine Warnung auszugeben.";
CM_ SG_ 2463978663 VZE_Warnung_VZ_1 "Ist das Signal gesetzt, so ist für das Verkehrszeichen 1 eine Warnung auszugeben.";
CM_ SG_ 2463978663 VZE_Warnung_VZ_2 "Ist das Signal gesetzt, so ist für das Verkehrszeichen 1 eine Warnung auszugeben.";
CM_ SG_ 2463978663 VZE_Warnung_VZ_3 "Ist das Signal gesetzt, so ist für das Verkehrszeichen 1 eine Warnung auszugeben.";
CM_ SG_ 2463978663 VZE_Zeichen_01_Gesetz "Das VZE-Tempolimit in Verkehrszeichen1  ist das gesetzlich geltende Tempolimit (je Land/Straßenklasse).";
CM_ SG_ 2463978663 VZE_Zeichen_01_Kamera "Das VZE-Tempolimit in Verkehrszeichen1 wurde von der Kamera erkannt.";
CM_ SG_ 2463978663 VZE_Zeichen_01_KameraWied "Das VZE-Tempolimit  in Verkehrszeichen1 wurde als Wiederholungsschild von der Kamera erkannt.";
CM_ SG_ 2463978663 VZE_Zeichen_01_Karte "Das VZE-Tempolimit in Verkehrszeichen1 stammt aus den Navigationskartendaten.";
CM_ SG_ 2463978663 VZE_Zeichen_02_Gesetz "Das VZE-Tempolimit in Verkehrszeichen2  ist das gesetzlich geltende Tempolimit (je Land/Straßenklasse).";
CM_ SG_ 2463978663 VZE_Zeichen_02_Kamera "Das VZE-Tempolimit in Verkehrszeichen2 wurde von der Kamera erkannt.";
CM_ SG_ 2463978663 VZE_Zeichen_02_KameraWied "Das VZE-Tempolimit  in Verkehrszeichen2 wurde als Wiederholungsschild von der Kamera erkannt.";
CM_ SG_ 2463978663 VZE_Zeichen_02_Karte "Das VZE-Tempolimit in Verkehrszeichen2 stammt aus den Navigationskartendaten.";
CM_ SG_ 2463978663 VZE_Zeichen_03_Gesetz "Das VZE-Tempolimit in Verkehrszeichen3  ist das gesetzlich geltende Tempolimit (je Land/Straßenklasse).";
CM_ SG_ 2463978663 VZE_Zeichen_03_Kamera "Das VZE-Tempolimit in Verkehrszeichen3 wurde von der Kamera erkannt.";
CM_ SG_ 2463978663 VZE_Zeichen_03_KameraWied "Das VZE-Tempolimit  in Verkehrszeichen3 wurde als Wiederholungsschild von der Kamera erkannt.";
CM_ SG_ 2463978663 VZE_Zeichen_03_Karte "Das VZE-Tempolimit in Verkehrszeichen3 stammt aus den Navigationskartendaten.";
CM_ SG_ 2463978663 VZE_Zeichen_04_Gesetz "Das VZE-Tempolimit ist das gesetzlich geltende Tempolimit (je Land/Straßenklasse).";
CM_ SG_ 2463978663 VZE_Zeichen_04_Kamera "Das VZE-Tempolimit wurde von der Kamera erkannt.";
CM_ SG_ 2463978663 VZE_Zeichen_04_KameraWied "Das VZE-Tempolimit wurde als Wiederholungsschild von der Kamera erkannt.";
CM_ SG_ 2463978663 VZE_Zeichen_04_Karte "Das VZE-Tempolimit stammt aus den Navigationskartendaten.";
CM_ SG_ 2463978663 VZE_Zeichen_05_Entfernung "In dem Signal wird die Entfernung zum Verkehrszeichen5 übertragen";
CM_ SG_ 2463978663 VZE_Zeichen_05_Entfernung_StdA "In dem Signal wird die Standardabweichung bzgl. der Entfernung zum Verkehrszeichen5 übertragen ";
CM_ SG_ 2463978663 VZE_Zeichen_05_Gesetz "Das VZE-Tempolimit ist das gesetzlich geltende Tempolimit (je Land/Straßenklasse).";
CM_ SG_ 2463978663 VZE_Zeichen_05_Kamera "Das VZE-Tempolimit wurde von der Kamera erkannt.";
CM_ SG_ 2463978663 VZE_Zeichen_05_KameraWied "Das VZE-Tempolimit wurde als Wiederholungsschild von der Kamera erkannt.";
CM_ SG_ 2463978663 VZE_Zeichen_05_Karte "Das VZE-Tempolimit stammt aus den Navigationskartendaten.";
CM_ SG_ 2463978663 VZE_Zeichen_06_Entfernung "In dem Signal wird die Entfernung zum Verkehrszeichen6 übertragen";
CM_ SG_ 2463978663 VZE_Zeichen_06_Entfernung_StdA "In dem Signal wird die Standardabweichung bzgl. der Entfernung zum Verkehrszeichen6 übertragen ";
CM_ SG_ 2463978663 VZE_Zusatzschild_1 "Zusatzsschild, das zu Verkehrszeichen 1 angezeigt werden soll.

Wertebereich lt. Hashtabelle";
CM_ SG_ 2463978663 VZE_Zusatzschild_2 "Zusatzsschild, das zu Verkehrszeichen 2 angezeigt werden soll.

Wertebereich lt. Hashtabelle";
CM_ SG_ 2463978663 VZE_Zusatzschild_3 "Zusatzsschild, das zu Verkehrszeichen 3 angezeigt werden soll.

Wertebereich lt. Hashtabelle";
CM_ SG_ 2463978663 VZE_Zusatzschild_4 "Zusatzsschild, das zu Verkehrszeichen 4 angezeigt werden soll.

Wertebereich lt. Hashtabelle";
CM_ SG_ 2463978663 VZE_Zusatzschild_5 "Zusatzsschild, das zu Verkehrszeichen 5 angezeigt werden soll.

Wertebereich lt. Hashtabelle";
CM_ SG_ 2463978663 VZE_Zusatzschild_6 "Zusatzsschild, das zu Verkehrszeichen 6 angezeigt werden soll.

Wertebereich lt. Hashtabelle";

CM_ SG_ 2589283476 WH_FSA_HMI_Meldungen_01 "FuRe Fahrstufenauswahl: Fahrerhinweise für das HMI";
CM_ SG_ 2589283476 WH_Schaltschema_Orientierung "Gibt für die Schaltschemaanzeige im Kombi an, wie die Fahrstufen auf der Schaltbetätigung positioniert sind. Die erstgenannte Fahrstufe liegt 'vorne' (in Kombianzeige 'oben'), die letztgenannte 'hinten' (in Kombianzeige 'unten'). Das Signal ist nur im Zus";
CM_ SG_ 2589283476 WH_Verbau_Entsperrtaste "Zeigt dem Kombi-Instument den Verbau der Entsperrtaste in der Schaltbetätigung an.
Diese Info wird benötigt, um zwischen „Zum Einlegen einer Fahrstufe Fußbremse betätigen' und „Zum Einlegen einer Fahrstufe Fußbremse UND ENTSPERRTASTE betätigen“ untersche";
CM_ SG_ 2589283476 WH_Warnung_02 "Warnmeldungen vom Waehlhebel an das Kombi";
CM_ SG_ 2589283476 WH_Warnung_03 "Warnungen des CGS im Lambo Urus";

CM_ SG_ 916 GE_Sollgang "Signalisiert den Sollgang, in den getippt werden soll. Abhängig vom Signal 'WBA_eing_Gang_02' und dem Sollgang kann dann das Kombi die Hochschaltempfehlung in Tip darstellen.";
CM_ SG_ 916 GE_Stoppverbot_Anz_01 "Dieses Signal gibt die detaillierte Begründung für ein Stoppverbot vom Getriebesteuergerät an.";
CM_ SG_ 916 GE_Stoppverbot_Anz_02 "Dieses Signal gibt die detaillierte Begründung für ein Stoppverbot vom Getriebesteuergerät an.";
CM_ SG_ 916 GE_Stoppverbot_Anz_03 "Dieses Signal gibt die detaillierte Begründung für ein Stoppverbot vom Getriebesteuergerät an.";
CM_ SG_ 916 GE_Stoppverbot_Anz_04 "Dieses Signal gibt die detaillierte Begründung für ein Stoppverbot vom Getriebesteuergerät an.";
CM_ SG_ 916 GE_Stoppverbot_Anz_05 "Dieses Signal gibt die detaillierte Begründung für ein Stoppverbot vom Getriebesteuergerät an.";
CM_ SG_ 916 GE_Stoppverbot_Anz_06 "Dieses Signal gibt die detaillierte Begründung für ein Stoppverbot vom Getriebesteuergerät an.";
CM_ SG_ 916 GE_Stoppverbot_Anz_07 "Dieses Signal gibt die detaillierte Begründung für ein Stoppverbot vom Getriebesteuergerät an.";
CM_ SG_ 916 GE_Stoppverbot_Anz_Std "Dieses Signal gibt die detaillierte Begründung für ein Stoppverbot vom Getriebesteuergerät an.";
CM_ SG_ 916 GE_Tipschaltempf_verfuegbar "Signalisierung, ob eine Hochschaltempfehlung im Tipmodus verfügbar ist oder nicht.";
CM_ SG_ 916 GE_Wiederstart_Anz_Std "Dieses Signal gibt die detaillierte Begründung für einen Wiederstart vom Getriebesteuergerät an. ";
CM_ SG_ 916 WBA_03_CRC "Für MLB:
'Berechnung siehe Lastenheft 'Kommunikationsabsicherung für FlexRay und CAN''

Ab MQB und MLBevo:
'Berechnung siehe Lastenheft 'End-to-End Kommunikationsabsicherung''

Endwerte siehe Begleitdokument 'S-PDU Kennungsfolgen'";
CM_ SG_ 916 WBA_Anforderung_Akustik "Anforderung eines Signaltons bei Anwahl der Fahrstufe R";
CM_ SG_ 916 WBA_Blinken "Dieses Bit steuert die Fehlerlampe an oder wird zum Blinken der WBA-Anzeige genutzt - nur falls WBA_Senderkennung = 00 (GSG)
";
CM_ SG_ 916 WBA_eing_Gang_02 "Das Automatikgetriebe gibt den aktuell eingelegten Gang aus.
Besonderheiten:
0x0 = marktabhängig wird auf Ganganzeige zur Fahrstufe komplett verzichtet
0xA = kurzzeitige Unterdrückung der Ganganzeige (z. B. Segeln, Zwischenstellung, etc.)";
CM_ SG_ 916 WBA_Fahrstufe_02 "Bei Automatgetrieben wird in diesem Signal die aktuelle anzuzeigende Fahrstufe ausgegeben.

Die Signalkodierungen 0x9, 0xA und 0xB werden im MSS-R8NF und MQB-A1/B/A2 verwendet.

Die Signalkodierungen 0xC und 0xD werden nur im MQB-A1/B/A2 verwendet.
";
CM_ SG_ 916 WBA_GE_Texte "Fahrerhinweise für das Kombi";
CM_ SG_ 916 WBA_GE_Texte_02 "Fahrerhinweise für das Kombi";
CM_ SG_ 916 WBA_GE_Warnung_02 "Prioritätswarnungen Getriebe";
CM_ SG_ 916 WBA_GE_Zusatzwarnungen "Prioritaetswarnungen Getriebe an Kombi
Audi MLB Wertebereich 0 bis 3
VW MQB Projekte verwenden nur den Wertebereich 0 bis 2
VW MQB Getriebefehler werden über das Signal  GE_Warnungen_02 gesendet.";
CM_ SG_ 916 WBA_Schaltschema_02 "Basis-Layout des Schaltschemas zur Anzeige im Kombiinstrument";
CM_ SG_ 916 WBA_Schaltschema_Fahreraktion "Signalisiert Fahreraktion an der Schaltbetaetigung";
CM_ SG_ 916 WBA_Schaltschema_FS_inaktiv "Gibt an, welche Fahrstufen innerhalb von WBA_Schaltschema_02 aktuell nicht erreichbar sind (z.B. aufgrund zu hoher Fahrzeuggeschwindigkeit oder fehlender Fahrbereitschaft).";
CM_ SG_ 916 WBA_Schaltschema_FS_vorwaerts "Zeigt an, welche der zwei Vorwärtsfahrstufen aktiv ist und ob in die inaktive geschaltet werden kann.";
CM_ SG_ 916 WBA_Schaltschema_Tippgasse "Zeigt den Verbau einer Tippgasse zur Anzeige im Schaltschema an.";
CM_ SG_ 916 WBA_Segeln_aktiv "Getriebe geht in den Segelbetrieb";
CM_ SG_ 916 WBA_Shiftlock_Lampe "Signalisiert dem Kombi, dass die Shiftlock-Lampe (grünes 'Bremse treten' Symbol) anzuzeigen ist.

Anmerkung: Signal ist nur von Kombis auszuwerten, die die Shiftlock-Info über Soft- oder Hard-LED und nicht als reine Textmeldung anzeigen.";
CM_ SG_ 916 WBA_ZielFahrstufe "Zielfahrprogramm (Darstellung), für getipptes S/E/M mit neuem Wählhebel im MQB";

CM_ SG_ 1361 WFS_Betrieb_Lesespule "Schlüsselkommunikation über die Lesespule";
CM_ SG_ 1361 WFS_ELV_authorisiert "Authorisierung der elektrischen Lenkungsverriegelung an der WFS";
CM_ SG_ 1361 WFS_Fahrerhinweise "Meldungen, Fahrer- und Warnhinweise der Wegfahrsperre";
CM_ SG_ 1361 WFS_ID_Geb_autorisiert "Authorisierung Schluessel (ID-Geber)";
CM_ SG_ 1361 WFS_ID_Geb_autorisiert_in_Kl15 "Authorisierung des Schlüssels im aktiven Klemme-15-Zyklus";
CM_ SG_ 1361 WFS_ID_Geb_steckt "Schluessel (ID-Geber) im Zuendschloss
";
CM_ SG_ 1361 WFS_Klemmenfreigabe "Freigabe von der WFS zum Einschalten der Klemme 15 und Klemme S";
CM_ SG_ 1361 WFS_Klemmenfreigabe_Signatur "Signatur zur Klemmenfreigabe durch die WFS";
CM_ SG_ 1361 WFS_LF_Aktiv "LF Schluesselkommunikation
";
CM_ SG_ 1361 WFS_LZ "Anforderung aus Lastenheft WFS V
";
CM_ SG_ 1361 WFS_Parken_Status "Schnittstelle zwischen WFS und ZFAS für das Pilotierte Parken um in Richtung ZFAS den Status der WFS im BCM2 zu kommunizieren";
CM_ SG_ 1361 WFS_Safe "Status WFS";
CM_ SG_ 1361 WFS_Schluessel_Fahrberecht "Schlüsselnummer Fahrberechtigung
0 = ungueltig, xxxx = Schluessel-Nr.";
CM_ SG_ 1361 WFS_Schluessel_Ist "Istwert der gelernten Schluessel";
CM_ SG_ 1361 WFS_Schluessel_Soll "Sollwert der zu lernenden Schluessel";
CM_ SG_ 1361 WFS_Verbauinfo_ELV "Info über die Konfiguration der ELV im WFS-Master";

CM_ SG_ 34 WFS_Transponder_Req_02_Data "Transponderdaten von WFS-Master an Kombi senden";

CM_ SG_ 35 WFS_Transponder_Resp_02_Data "Transponderdaten von Kombi an WFS-Master senden";

CM_ SG_ 830 WFS_Diag_LF_Aktiv_02 "Transponderdiagnose ist aktiv (nicht WFS)";
CM_ SG_ 830 WFS_LF_aktiv_02 "LF aktiv, Zugriff auf Transponder";
CM_ SG_ 830 WFS_Transp_Mod_Unterbrechung_02 "Transponder Gateway verlässt Modus Sleep oder Unterspannung";
CM_ SG_ 830 WFS_Verbau_Transp_Ant_02 "Kodierung Funktion Transponderantenne";

CM_ SG_ 1702 BCM1_SRA_aktiv "Status Scheinwerferreinigungsanlage";
CM_ SG_ 1702 Heckwischer_Anforderung "Das Signal beschreibt die Anforderung an den Signalausgang im BCM2 zur Ansteuerung des Heckwischers.";
CM_ SG_ 1702 Waschen_vorne_aktiv "Status: Waschen vorne aktiv";
CM_ SG_ 1702 Wischer1_Wischgeschwindigkeit "aktuelle, durch Sensorik gemessene Wischgeschwindigkeit";
CM_ SG_ 1702 Wischer_Anzeigetext "Das Signal fordert einen Kombi-Pop-Up mit entsprechenden Texten an";
CM_ SG_ 1702 Wischer_vorne_aktiv "Status: Wischer vorne";
CM_ SG_ 1702 Wischer_vorne_blockiert "Blockade Wischer vorne (z.B. durch Schnee)";
CM_ SG_ 1702 Wischer_vorne_defekt "Fehlerstatus Wischer vorne (Anzeige im Kombi)";
CM_ SG_ 1702 Wischer_vorne_Normal "Wischer Front normal aktiv";
CM_ SG_ 1702 Wischer_vorne_Parklage "Wischer Front in Parklage";
CM_ SG_ 1702 Wischer_vorne_Schnell "Wischer vorne schnell aktiv";
CM_ SG_ 1702 Wischer_WH_PopUp_Anf "Anzeige von Wischerstufen im Kombi.";
CM_ SG_ 1702 Wischer_WH_Typ "Signal beinhaltet Lenkstockschaltertyp für grafische Anzeige im Kombi zur Wischerfunktion";
CM_ SG_ 1702 WWSs_01_alt "Veraltet Bit für die LIN-Botschaft WWSs_01.

Betroffene Signale:

Wischer_vorne_aktiv";

CM_ SG_ 1602 WIV_Russindex "Nur für Diesel, Rußwert, bei Otto Wert = 0";
CM_ SG_ 1602 WIV_t_max "Maximales Wartungsintervall für WIV in Monaten";
CM_ SG_ 1602 WIV_t_min "Minimales Wartungsintervall für WIV in Monaten";
CM_ SG_ 1602 WIV_Verschleissindex "Bei Otto Verbrauch, bei Diesel Verschleiss";
CM_ SG_ 1602 WIV_W_max "Maximales Wartungsintervall für WIV in km";
CM_ SG_ 1602 WIV_W_min "Minimales Wartungsintervall für WIV in km";

CM_ SG_ 1140 DI_Screendesign "Information welcher Designwunsch ausgewählt wurde zur Kennlinienumschaltung";
CM_ SG_ 1140 MMI_State "Powerstate des Zentralrechners. MMI_Off wird im Zustand dead mode gesendet.";
CM_ SG_ 1140 SI_ICAN "MQB: Busruhe ICAN.
E3: Busruhe ABCAN.";
CM_ SG_ 1140 WLC1_Systemzustand "0 = Wireless Charger off (Message produced by HMI)
1 = Wireless Charger on (Message produced by HMI)";
CM_ SG_ 1140 WLC2_Systemzustand "0 = Wireless Charger off
1 = Wireless Charger on";
CM_ SG_ 1140 ZR_DimOffs_DU_1 "Dimmungs-Offset der Display Unit.";
CM_ SG_ 1140 ZR_DimOffs_DU_2 "Dimmungs-Offset der Display Unit.";
CM_ SG_ 1140 ZR_DimOffs_DU_3 "Dimmungs-Offset der Display Unit.";
CM_ SG_ 1140 ZR_DimOffs_DU_4 "Dimmungs-Offset der Display Unit.";
CM_ SG_ 1140 ZR_Lenkerposition "Ueber Diagnose (Codierung) im Zentralrechner eingespeicherte Lenkerposition
  ";
CM_ SG_ 1140 ZR_State_DU_1 "Kontrollbit für Display, Hintergrundbeleuchtung aus, Hintergrundbeleuchtung an, Energiesparmodus.
";
CM_ SG_ 1140 ZR_State_DU_2 "Kontrollbit für Display, Hintergrundbeleuchtung aus, Hintergrundbeleuchtung an, Energiesparmodus.
";
CM_ SG_ 1140 ZR_State_DU_3 "Kontrollbit für Display, Hintergrundbeleuchtung aus, Hintergrundbeleuchtung an, Energiesparmodus.
";
CM_ SG_ 1140 ZR_State_DU_4 "Kontrollbit für Display, Hintergrundbeleuchtung aus, Hintergrundbeleuchtung an, Energiesparmodus.";
CM_ SG_ 1140 ZR_WecktGesp "Befehl zum Sperren der Wecktasten am Bedienteil.";

CM_ SG_ 1411 BCM_FH_Freigabe "Funktionsfreigabe Fensterheber";
CM_ SG_ 1411 BCM_HSK_Freigabe "Handschuhkastenfreigabe";
CM_ SG_ 1411 BCM_Komfortfkt_Freigabe "globale Freigabe der Komfortfunktion";
CM_ SG_ 1411 BCM_Tankklappensteller_Fehler "Fehler: nicht Funktionalität des Tankklappenstellers";
CM_ SG_ 1411 BCM_Verdeck_Freigabe "Freigabe Verdeckbetrieb
";
CM_ SG_ 1411 DWA_aktiv "Status DWA  aktiv";
CM_ SG_ 1411 FBS_IDG_in_Reichweite "Für elektrisch betätigte Türen und Klappen muss für eine Betätigung über Funk eine Reichweitenbegrenzung eingeführt werden. Diese Bit zeigt an, dass sich der Funkschlüssel innerhalb der geforderten Reichweite befindet";
CM_ SG_ 1411 FBS_Warn_Schluessel_Batt "Kombi Prio Warnung Schluessel Batterie
'Bitte Schlüsselbatterie wechseln!'";
CM_ SG_ 1411 FFB_Auf_Taste "Auf-Taste Funkschluessel

";
CM_ SG_ 1411 FFB_CarFinder "Car Finder Funktion (Blinken ohne zu entriegeln)";
CM_ SG_ 1411 FFB_HDF_Taste "HDF Taste am Funkschluessel
";
CM_ SG_ 1411 FFB_Komfortoeffnen "Komfortoeffnen Funk
";
CM_ SG_ 1411 FFB_Komfortschliessen "Komfortschliessen Funk
";
CM_ SG_ 1411 FFB_Panik_Taste "Panik Taste Funkschluessel
";
CM_ SG_ 1411 FFB_Zu_Taste "Zu-Taste Funkschluessel
";
CM_ SG_ 1411 HBFS_gesafet "HBFS Tuer gesafet.
Im Zustand Safe wird auch das Signal HBFS_verriegelt = 1 gesendet.";
CM_ SG_ 1411 HBFS_verriegelt "Verriegelungsstatus Tür";
CM_ SG_ 1411 HD_Hauptraste "SBL-Schloss (MQB/MLBevo): Drehfalle Heckdeckel
sonst (MQB): Hauptraste Heckdeckel";
CM_ SG_ 1411 HD_Vorraste "SBL_Schloss (MQB/MLBevo): Sperrklinke Heckdeckel
sonst (MQB): Vorraste Heckdeckel";
CM_ SG_ 1411 HFS_gesafet "HFS Tuer gesafet.
Im Zustand Safe wird auch das Signal HFS_verriegelt = 1 gesendet.";
CM_ SG_ 1411 HFS_verriegelt "HFS Tuer verriegelt";
CM_ SG_ 1411 IRUE_aktiv "Status Innenraumüberwachung
";
CM_ SG_ 1411 IRUE_Taster_Fkts_LED "Anforderung Funktions-LED IRUE-Taster (LED wird vom TSG angesteuert)
MQB: Bei Verbau eines einzelnen Taster zur Deaktivierung von IRUE und NGS wird dieses Signal zur Ansteuerung der Funktions-LED gesendet.";
CM_ SG_ 1411 VIP_Sensor_STSG_HBFS_betaetigt "Schiebetürlauf HBFS wurde durch VIP angefordert und als berechtigt eingestuft.";
CM_ SG_ 1411 VIP_Sensor_STSG_HFS_betaetigt "Schiebetürlauf HFS wurde durch VIP angefordert und als berechtigt eingestuft.";
CM_ SG_ 1411 ZV_Anf_Challenge_Auth "Anforderung an alle beteiligten Steuergeräte die Challenge an den ZV-Master zu senden.";
CM_ SG_ 1411 ZV_BT_offen "gespiegeltes Bit BT_Tuer_geoeffnet TSG_BT_1 Botschaft";
CM_ SG_ 1411 ZV_Einzeltuerentriegelung "Einzeltürentriegelung ZV
";
CM_ SG_ 1411 ZV_eRWK_Umfeld_Pruefung "Anforderung an PDC/PLA im eRWK-Modus eine Umfeldprüfung durchzuführen";
CM_ SG_ 1411 ZV_FT_offen "gespiegeltes Bit FT_Tuer_geoeffnet TSG_FT_1 Botschaft";
CM_ SG_ 1411 ZV_gesafet_extern_ist "Istzustand: Fahrzeug aussen gesafet
";
CM_ SG_ 1411 ZV_gesafet_extern_soll "Sollzustand: Fahrzeug gesafet extern
";
CM_ SG_ 1411 ZV_HBFS_offen "gespiegeltes Bit HBFS_Tuer_geoeffnet TSG_HBFS_1 Botschaft";
CM_ SG_ 1411 ZV_HD_offen "Status Heckdeckel
";
CM_ SG_ 1411 ZV_Heckeinzelentriegelung "Heckdeckeleinzelentriegelung";
CM_ SG_ 1411 ZV_HFS_offen "gespiegeltes Bit HFS_Tuer_geoeffnet TSG_HFS_1 Botschaft";
CM_ SG_ 1411 ZV_HS_offen "Status Heckscheibe
";
CM_ SG_ 1411 ZV_ist_Zustand_verfuegbar "Verfügbarkeit IST-Zustand ZV

";
CM_ SG_ 1411 ZV_Oeffnungsmodus "Konfigurierter Oeffnungsmodus fuer ZV:
0 = globale Oeffnung (alle Tueren)
1 = ZV mit Einzeltuerentriegelung (FFB - nur Fahrertuer, Kessy - nur bediente Tuer)
2 = ZV individuell selektive Oeffnung (FFB - Fahrerseite, Kessy - bediente Tuer + Fahrertuer)";
CM_ SG_ 1411 ZV_Rollo_auf "Komfortöffnen des Dachrollos";
CM_ SG_ 1411 ZV_Rollo_zu "Komfortschließen des Dachrollos";
CM_ SG_ 1411 ZV_SAD_auf "Komfortöffnen des Schiebeausstelldaches";
CM_ SG_ 1411 ZV_SAD_zu "Komfortschließen des Schiebeausstelldaches";
CM_ SG_ 1411 ZV_SafeFunktion_aktiv "Statusübermittlung ob die Safe Funktion im Fzg. aktiv ist. Das Kombi benötigt das Signal, um den Text Safelock aktiv anzuzeigen. ";
CM_ SG_ 1411 ZV_Schluessel_Zugang "aktuelle Funkschlüsselnummer";
CM_ SG_ 1411 ZV_STSG_Crashzustand "Statusübermittlung ob der Crashzustand der Schiebetüren dauerhaft im Fzg. aktiv ist. Das Kombi benötigt das Signal, um die Meldung anzuzeigen.";
CM_ SG_ 1411 ZV_STSG_eKiSi_defekt "Statusübermittlung ob die elektronische Kindersicherung der Schiebetüren im Fzg. defekt ist. Das Kombi benötigt das Signal, um die Meldung anzuzeigen.";
CM_ SG_ 1411 ZV_STSG_HBFS_Anf "Die ZV fordert einen Lauf bzw. Stopp der Schiebetür an.";
CM_ SG_ 1411 ZV_STSG_HFS_Anf "Die ZV fordert einen Lauf bzw. Stopp der Schiebetür an.";
CM_ SG_ 1411 ZV_Tankklappe_offen "Öffnungsstatus der Tankklappe";
CM_ SG_ 1411 ZV_verriegeln_Anf "Gesammelte externe ZV-Verriegelungsanforderung des Kunden (z. B. zur Aktivierung der Anzeige des Ladezustands über Aussenlicht).";
CM_ SG_ 1411 ZV_verriegelt_extern_ist "Istzustand: Verriegelung Fahrzeug aussen
";
CM_ SG_ 1411 ZV_verriegelt_extern_soll "Sollzustand: Verriegelung Fahrzeug aussen
";
CM_ SG_ 1411 ZV_verriegelt_intern_ist "Istzustand: Verriegelung Fahrzeug innen
";
CM_ SG_ 1411 ZV_verriegelt_intern_soll "Sollzustand: Verriegelung Fahrzeug innen
";
CM_ SG_ 1411 ZV_verriegelt_soll "Fahrzeug Gesamtverriegelungsstatus Sollzustand für Ladestecker- und Ladeklappenverriegelung. ";
BA_DEF_REL_ BU_SG_REL_  "GenSigTimeoutTime" INT 0 65535;
BA_DEF_ BO_  "DiagRequest" ENUM "No", "Yes";
BA_DEF_ BO_  "DiagResponse" ENUM "No", "Yes";
BA_DEF_ BO_  "DiagState" ENUM "No", "Yes";
BA_DEF_ BO_  "GenMsgChkConstant" HEX 0 4095;
BA_DEF_ BO_  "GenMsgCycleTime" INT 0 65535;
BA_DEF_ BO_  "GenMsgCycleTimeFast" INT 0 65535;
BA_DEF_ BO_  "GenMsgDelayTime" INT 0 100000;
BA_DEF_ BO_  "GenMsgILSupport" ENUM "No", "Yes";
BA_DEF_ BO_  "GenMsgNrOfRepetition" INT 0 100;
BA_DEF_ BO_  "GenMsgPDUConstants" STRING;
BA_DEF_ BO_  "GenMsgSendType" ENUM "Cyclic", "not_used", "not_used", "not_used", "not_used", "not_used", "not_used", "IfActive", "NoMsgSendType";
BA_DEF_ BO_  "GenMsgStartDelayTime" INT 0 100000;
BA_DEF_ BO_  "NmMessage" ENUM "No", "Yes";
BA_DEF_ BO_  "NmhMessage" ENUM "No", "Yes";
BA_DEF_ BO_  "MsgType" ENUM "Application", "NM ", "NMH", "TP2.0", "ISO-TP ", "BAP", "EID", "KS", "XCP_PRE_CONFIGURED", "XCP_RUNTIME_CONFIGURED";
BA_DEF_ BO_  "VAGTP20_API" HEX 0 255;
BA_DEF_ BO_  "VAGTP20_DynConnection" ENUM "No", "Yes";
BA_DEF_ BO_  "VAGTP20_DynSetup" ENUM "No", "Yes";
BA_DEF_ BO_  "VAGTP20_StatConnection" ENUM "No", "Yes";
BA_DEF_ BO_  "CANFD_BRS" ENUM "0", "1";
BA_DEF_ BO_  "VFrameFormat" ENUM "StandardCAN", "ExtendedCAN", "reserved", "reserved", "reserved", "reserved", "reserved", "reserved", "reserved", "reserved", "reserved", "reserved", "reserved", "reserved", "StandardCAN_FD", "ExtendedCAN_FD";
BA_DEF_ SG_  "GenSigActiveRepetitions" INT -2147483648 2147483647;
BA_DEF_ SG_  "GenSigInactiveValue" INT -2147483648 2147483647;
BA_DEF_ SG_  "GenSigSendType" ENUM "Cyclic", "OnWrite", "OnWriteWithRepetition", "OnChange", "OnChangeWithRepetition", "IfActive", "IfActiveWithRepetition", "NoSigSendType", "OnChangeAndIfActive", "OnChangeAndIfActiveWithRepetition";
BA_DEF_ SG_  "GenSigStartValue" INT -2147483648 2147483647;
BA_DEF_ SG_  "NWM-WakeupAllowed" ENUM "No", "Yes";
BA_DEF_ SG_  "GenSigFuncType" ENUM "NoFunction", "MsgCounter", "CRC-8", "XOR", "XOR-2", "DatedBit", "SW-Kl15", "CHK", "Constant", "Protocol", "CRC-8-SAE_J1850", "CRC-32", "DataLength", "DataID", "MsgCounter16", "SOK-Signatur", "Cluster";
BA_DEF_ SG_  "GenSigSwitchedByIgnition" ENUM "No", "Yes";
BA_DEF_ SG_  "Fehlerwert" HEX 0 2147483647;
BA_DEF_ SG_  "GenSigMissingSourceValue" HEX 0 2147483647;
BA_DEF_DEF_REL_  "GenSigTimeoutTime" 0;
BA_DEF_DEF_  "DiagRequest" "No";
BA_DEF_DEF_  "DiagResponse" "No";
BA_DEF_DEF_  "DiagState" "No";
BA_DEF_DEF_  "GenMsgChkConstant" 0;
BA_DEF_DEF_  "GenMsgCycleTime" 0;
BA_DEF_DEF_  "GenMsgCycleTimeFast" 0;
BA_DEF_DEF_  "GenMsgDelayTime" 0;
BA_DEF_DEF_  "GenMsgILSupport" "No";
BA_DEF_DEF_  "GenMsgNrOfRepetition" 0;
BA_DEF_DEF_  "GenMsgPDUConstants" "";
BA_DEF_DEF_  "GenMsgSendType" "NoMsgSendType";
BA_DEF_DEF_  "GenMsgStartDelayTime" 0;
BA_DEF_DEF_  "NmMessage" "No";
BA_DEF_DEF_  "NmhMessage" "No";
BA_DEF_DEF_  "MsgType" "Application";
BA_DEF_DEF_  "VAGTP20_API" 0;
BA_DEF_DEF_  "VAGTP20_DynConnection" "No";
BA_DEF_DEF_  "VAGTP20_DynSetup" "No";
BA_DEF_DEF_  "VAGTP20_StatConnection" "No";
BA_DEF_DEF_  "CANFD_BRS" "1";
BA_DEF_DEF_  "VFrameFormat" "StandardCAN";
BA_DEF_DEF_  "GenSigActiveRepetitions" 0;
BA_DEF_DEF_  "GenSigInactiveValue" 0;
BA_DEF_DEF_  "GenSigSendType" "NoSigSendType";
BA_DEF_DEF_  "GenSigStartValue" 0;
BA_DEF_DEF_  "NWM-WakeupAllowed" "No";
BA_DEF_DEF_  "GenSigFuncType" "NoFunction";
BA_DEF_DEF_  "GenSigSwitchedByIgnition" "Yes";
BA_DEF_DEF_  "Fehlerwert" 0;
BA_DEF_DEF_  "GenSigMissingSourceValue" 0;
BA_ "GenMsgCycleTime" BO_ 997 100;
BA_ "GenMsgDelayTime" BO_ 997 20;
BA_ "GenMsgILSupport" BO_ 997 1;
BA_ "GenMsgPDUConstants" BO_ 997 "0xc4,0x6a,0x69,0x30,0xcf,0x61,0x58,0x51,0x1b,0x86,0x99,0xd3,0xf6,0x1d,0x9a,0x37";
BA_ "GenMsgSendType" BO_ 997 0;
BA_ "VFrameFormat" BO_ 997 14;
BA_ "GenMsgCycleTime" BO_ 975 100;
BA_ "GenMsgDelayTime" BO_ 975 20;
BA_ "GenMsgILSupport" BO_ 975 1;
BA_ "GenMsgSendType" BO_ 975 0;
BA_ "VFrameFormat" BO_ 975 14;
BA_ "GenMsgCycleTime" BO_ 974 100;
BA_ "GenMsgDelayTime" BO_ 974 20;
BA_ "GenMsgILSupport" BO_ 974 1;
BA_ "GenMsgSendType" BO_ 974 0;
BA_ "VFrameFormat" BO_ 974 14;
BA_ "GenMsgCycleTime" BO_ 2589283772 1000;
BA_ "GenMsgILSupport" BO_ 2589283772 1;
BA_ "GenMsgSendType" BO_ 2589283772 0;
BA_ "VFrameFormat" BO_ 2589283772 15;
BA_ "GenMsgCycleTime" BO_ 2589283773 1000;
BA_ "GenMsgILSupport" BO_ 2589283773 1;
BA_ "GenMsgSendType" BO_ 2589283773 0;
BA_ "VFrameFormat" BO_ 2589283773 15;
BA_ "GenMsgCycleTime" BO_ 1718 1000;
BA_ "GenMsgILSupport" BO_ 1718 1;
BA_ "GenMsgSendType" BO_ 1718 0;
BA_ "VFrameFormat" BO_ 1718 14;
BA_ "GenMsgCycleTime" BO_ 995 100;
BA_ "GenMsgCycleTimeFast" BO_ 995 50;
BA_ "GenMsgDelayTime" BO_ 995 50;
BA_ "GenMsgILSupport" BO_ 995 1;
BA_ "GenMsgNrOfRepetition" BO_ 995 5;
BA_ "GenMsgSendType" BO_ 995 0;
BA_ "VFrameFormat" BO_ 995 14;
BA_ "GenMsgCycleTime" BO_ 1716 200;
BA_ "GenMsgILSupport" BO_ 1716 1;
BA_ "GenMsgSendType" BO_ 1716 0;
BA_ "VFrameFormat" BO_ 1716 14;
BA_ "GenMsgCycleTime" BO_ 1057 100;
BA_ "GenMsgDelayTime" BO_ 1057 50;
BA_ "GenMsgILSupport" BO_ 1057 1;
BA_ "GenMsgPDUConstants" BO_ 1057 "0x8e,0x95,0xed,0x45,0x8d,0x80,0x23,0x35,0x30,0x56,0x14,0xf1,0x38,0x42,0xba,0x1d";
BA_ "GenMsgSendType" BO_ 1057 0;
BA_ "VFrameFormat" BO_ 1057 14;
BA_ "GenMsgCycleTime" BO_ 2463978663 200;
BA_ "GenMsgDelayTime" BO_ 2463978663 40;
BA_ "GenMsgILSupport" BO_ 2463978663 1;
BA_ "GenMsgSendType" BO_ 2463978663 0;
BA_ "VFrameFormat" BO_ 2463978663 15;
BA_ "GenMsgCycleTime" BO_ 2589283476 1000;
BA_ "GenMsgDelayTime" BO_ 2589283476 100;
BA_ "GenMsgILSupport" BO_ 2589283476 1;
BA_ "GenMsgSendType" BO_ 2589283476 0;
BA_ "VFrameFormat" BO_ 2589283476 15;
BA_ "GenMsgCycleTime" BO_ 916 160;
BA_ "GenMsgCycleTimeFast" BO_ 916 10;
BA_ "GenMsgDelayTime" BO_ 916 10;
BA_ "GenMsgILSupport" BO_ 916 1;
BA_ "GenMsgNrOfRepetition" BO_ 916 3;
BA_ "GenMsgPDUConstants" BO_ 916 "0x47,0x94,0x92,0x6a,0x67,0xb5,0x0d,0x38,0xe3,0x8a,0x5d,0xb4,0x54,0xab,0xae,0x27";
BA_ "GenMsgSendType" BO_ 916 0;
BA_ "VFrameFormat" BO_ 916 14;
BA_ "GenMsgCycleTime" BO_ 1361 200;
BA_ "GenMsgDelayTime" BO_ 1361 50;
BA_ "GenMsgILSupport" BO_ 1361 1;
BA_ "GenMsgSendType" BO_ 1361 0;
BA_ "VFrameFormat" BO_ 1361 14;
BA_ "VFrameFormat" BO_ 34 14;
BA_ "VFrameFormat" BO_ 35 14;
BA_ "GenMsgCycleTime" BO_ 830 1000;
BA_ "GenMsgDelayTime" BO_ 830 10;
BA_ "GenMsgILSupport" BO_ 830 1;
BA_ "GenMsgSendType" BO_ 830 0;
BA_ "VFrameFormat" BO_ 830 14;
BA_ "GenMsgCycleTime" BO_ 1702 1000;
BA_ "GenMsgDelayTime" BO_ 1702 50;
BA_ "GenMsgILSupport" BO_ 1702 1;
BA_ "GenMsgSendType" BO_ 1702 0;
BA_ "VFrameFormat" BO_ 1702 14;
BA_ "GenMsgCycleTime" BO_ 1602 2000;
BA_ "GenMsgILSupport" BO_ 1602 1;
BA_ "GenMsgSendType" BO_ 1602 0;
BA_ "VFrameFormat" BO_ 1602 14;
BA_ "GenMsgCycleTime" BO_ 1140 1000;
BA_ "GenMsgDelayTime" BO_ 1140 40;
BA_ "GenMsgILSupport" BO_ 1140 1;
BA_ "GenMsgSendType" BO_ 1140 0;
BA_ "VFrameFormat" BO_ 1140 14;
BA_ "GenMsgCycleTime" BO_ 1411 200;
BA_ "GenMsgCycleTimeFast" BO_ 1411 50;
BA_ "GenMsgDelayTime" BO_ 1411 20;
BA_ "GenMsgILSupport" BO_ 1411 1;
BA_ "GenMsgNrOfRepetition" BO_ 1411 3;
BA_ "GenMsgSendType" BO_ 1411 0;
BA_ "VFrameFormat" BO_ 1411 14;
BA_ "GenSigSendType" SG_ 997 eTAB_FS_Bowdenzug_Auswerfen 3;
BA_ "GenSigSwitchedByIgnition" SG_ 997 eTAB_FS_Bowdenzug_Auswerfen 0;
BA_ "GenSigSendType" SG_ 997 FS_Push_Tuergriff 3;
BA_ "GenSigSwitchedByIgnition" SG_ 997 FS_Push_Tuergriff 0;
BA_ "GenSigSendType" SG_ 997 FS_Status_eTAG_ext 3;
BA_ "GenSigStartValue" SG_ 997 FS_Status_eTAG_ext 3;
BA_ "GenSigSwitchedByIgnition" SG_ 997 FS_Status_eTAG_ext 0;
BA_ "Fehlerwert" SG_ 997 FS_Status_eTAG_ext 4;
BA_ "GenSigSendType" SG_ 997 FT_ASW_Warnton 0;
BA_ "GenSigSwitchedByIgnition" SG_ 997 FT_ASW_Warnton 0;
BA_ "Fehlerwert" SG_ 997 FT_ASW_Warnton 3;
BA_ "GenSigSendType" SG_ 997 FT_BFS_Tuer_Status 3;
BA_ "GenSigSwitchedByIgnition" SG_ 997 FT_BFS_Tuer_Status 0;
BA_ "Fehlerwert" SG_ 997 FT_BFS_Tuer_Status 3;
BA_ "GenSigSendType" SG_ 997 FT_Cargolock_bet 3;
BA_ "GenSigSwitchedByIgnition" SG_ 997 FT_Cargolock_bet 0;
BA_ "GenSigSendType" SG_ 997 FT_HBFS_Tuer_Status 3;
BA_ "GenSigSwitchedByIgnition" SG_ 997 FT_HBFS_Tuer_Status 0;
BA_ "Fehlerwert" SG_ 997 FT_HBFS_Tuer_Status 3;
BA_ "GenSigSendType" SG_ 997 FT_HFS_Tuer_Status 3;
BA_ "GenSigSwitchedByIgnition" SG_ 997 FT_HFS_Tuer_Status 0;
BA_ "Fehlerwert" SG_ 997 FT_HFS_Tuer_Status 3;
BA_ "GenSigSendType" SG_ 997 FT_kisi_asynchron 3;
BA_ "GenSigSwitchedByIgnition" SG_ 997 FT_kisi_asynchron 0;
BA_ "GenSigSendType" SG_ 997 FT_KiSi_Status_Soll_HBFS 0;
BA_ "GenSigSwitchedByIgnition" SG_ 997 FT_KiSi_Status_Soll_HBFS 0;
BA_ "GenSigSendType" SG_ 997 FT_KiSi_Status_Soll_HFS 0;
BA_ "GenSigSwitchedByIgnition" SG_ 997 FT_KiSi_Status_Soll_HFS 0;
BA_ "GenSigSendType" SG_ 997 FT_Kisi_Taster_li_02 3;
BA_ "GenSigSwitchedByIgnition" SG_ 997 FT_Kisi_Taster_li_02 0;
BA_ "GenSigSendType" SG_ 997 FT_Kisi_Taster_re_02 3;
BA_ "GenSigSwitchedByIgnition" SG_ 997 FT_Kisi_Taster_re_02 0;
BA_ "GenSigSendType" SG_ 997 FT_Lock_Taster_02 0;
BA_ "GenSigSwitchedByIgnition" SG_ 997 FT_Lock_Taster_02 0;
BA_ "GenSigSendType" SG_ 997 FT_Schluesselschalter_zu_02 0;
BA_ "GenSigSwitchedByIgnition" SG_ 997 FT_Schluesselschalter_zu_02 0;
BA_ "GenSigSendType" SG_ 997 FT_SP_Heizung_ein 3;
BA_ "GenSigSwitchedByIgnition" SG_ 997 FT_SP_Heizung_ein 0;
BA_ "GenSigSendType" SG_ 997 FT_TCR_Mode_aktiv 3;
BA_ "GenSigSwitchedByIgnition" SG_ 997 FT_TCR_Mode_aktiv 0;
BA_ "GenSigSendType" SG_ 997 FT_TD_Taste_Status 3;
BA_ "GenSigSwitchedByIgnition" SG_ 997 FT_TD_Taste_Status 0;
BA_ "GenSigSendType" SG_ 997 FT_Tuer_Status 3;
BA_ "GenSigSwitchedByIgnition" SG_ 997 FT_Tuer_Status 0;
BA_ "Fehlerwert" SG_ 997 FT_Tuer_Status 3;
BA_ "GenSigSendType" SG_ 997 FT_Tuer_Status_QBit 0;
BA_ "GenSigSwitchedByIgnition" SG_ 997 FT_Tuer_Status_QBit 0;
BA_ "GenSigSendType" SG_ 997 FT_Tueroeffnen_Warnung 3;
BA_ "GenSigSwitchedByIgnition" SG_ 997 FT_Tueroeffnen_Warnung 0;
BA_ "GenSigSendType" SG_ 997 SSA_FT_ASW_Status 3;
BA_ "GenSigSwitchedByIgnition" SG_ 997 SSA_FT_ASW_Status 0;
BA_ "GenSigSendType" SG_ 997 TBF_FS_Touch_Event 3;
BA_ "GenSigSwitchedByIgnition" SG_ 997 TBF_FS_Touch_Event 0;
BA_ "GenSigSendType" SG_ 997 TSG_FS_Spiegel_angeklappt 3;
BA_ "GenSigSwitchedByIgnition" SG_ 997 TSG_FS_Spiegel_angeklappt 0;
BA_ "GenSigSendType" SG_ 997 TSG_FT_02_BZ 0;
BA_ "GenSigFuncType" SG_ 997 TSG_FT_02_BZ 1;
BA_ "GenSigSwitchedByIgnition" SG_ 997 TSG_FT_02_BZ 0;
BA_ "GenSigSendType" SG_ 997 TSG_FT_02_CRC 0;
BA_ "GenSigFuncType" SG_ 997 TSG_FT_02_CRC 2;
BA_ "GenSigSwitchedByIgnition" SG_ 997 TSG_FT_02_CRC 0;
BA_ "GenSigSendType" SG_ 975 ASW_Warnung_aktiv_HBFS 3;
BA_ "GenSigSwitchedByIgnition" SG_ 975 ASW_Warnung_aktiv_HBFS 0;
BA_ "GenSigSendType" SG_ 975 HBFS_FH_Bew_hoch 3;
BA_ "GenSigSwitchedByIgnition" SG_ 975 HBFS_FH_Bew_hoch 0;
BA_ "GenSigSendType" SG_ 975 HBFS_FH_Bew_tief 3;
BA_ "GenSigSwitchedByIgnition" SG_ 975 HBFS_FH_Bew_tief 0;
BA_ "GenSigSendType" SG_ 975 HBFS_FH_Block 3;
BA_ "GenSigSwitchedByIgnition" SG_ 975 HBFS_FH_Block 0;
BA_ "GenSigSendType" SG_ 975 HBFS_FH_Fang 3;
BA_ "GenSigSwitchedByIgnition" SG_ 975 HBFS_FH_Fang 0;
BA_ "GenSigSendType" SG_ 975 HBFS_FH_normiert 3;
BA_ "GenSigSwitchedByIgnition" SG_ 975 HBFS_FH_normiert 0;
BA_ "GenSigSendType" SG_ 975 HBFS_FH_Oeffnung 3;
BA_ "GenSigSwitchedByIgnition" SG_ 975 HBFS_FH_Oeffnung 0;
BA_ "GenSigSendType" SG_ 975 HBFS_FH_S_AutoHoch 3;
BA_ "GenSigSwitchedByIgnition" SG_ 975 HBFS_FH_S_AutoHoch 0;
BA_ "GenSigSendType" SG_ 975 HBFS_FH_S_AutoTief 3;
BA_ "GenSigSwitchedByIgnition" SG_ 975 HBFS_FH_S_AutoTief 0;
BA_ "GenSigSendType" SG_ 975 HBFS_FH_S_HFS_AutoHoch 3;
BA_ "GenSigSwitchedByIgnition" SG_ 975 HBFS_FH_S_HFS_AutoHoch 0;
BA_ "GenSigSendType" SG_ 975 HBFS_FH_S_HFS_AutoTief 3;
BA_ "GenSigSwitchedByIgnition" SG_ 975 HBFS_FH_S_HFS_AutoTief 0;
BA_ "GenSigSendType" SG_ 975 HBFS_FH_S_HFS_ManHoch 3;
BA_ "GenSigSwitchedByIgnition" SG_ 975 HBFS_FH_S_HFS_ManHoch 0;
BA_ "GenSigSendType" SG_ 975 HBFS_FH_S_HFS_ManTief 3;
BA_ "GenSigSwitchedByIgnition" SG_ 975 HBFS_FH_S_HFS_ManTief 0;
BA_ "GenSigSendType" SG_ 975 HBFS_FH_S_ManHoch 3;
BA_ "GenSigSwitchedByIgnition" SG_ 975 HBFS_FH_S_ManHoch 0;
BA_ "GenSigSendType" SG_ 975 HBFS_FH_S_ManTief 3;
BA_ "GenSigSwitchedByIgnition" SG_ 975 HBFS_FH_S_ManTief 0;
BA_ "GenSigSendType" SG_ 975 HBFS_FH_Thermo 3;
BA_ "GenSigSwitchedByIgnition" SG_ 975 HBFS_FH_Thermo 0;
BA_ "GenSigSendType" SG_ 975 HBFS_gesafet 3;
BA_ "GenSigSwitchedByIgnition" SG_ 975 HBFS_gesafet 0;
BA_ "GenSigSendType" SG_ 975 HBFS_Heckrollotaster_betaetigt 3;
BA_ "GenSigSwitchedByIgnition" SG_ 975 HBFS_Heckrollotaster_betaetigt 0;
BA_ "GenSigSendType" SG_ 975 HBFS_Lock_Taster 3;
BA_ "GenSigSwitchedByIgnition" SG_ 975 HBFS_Lock_Taster 0;
BA_ "GenSigSendType" SG_ 975 HBFS_Lock_Taster_inv 3;
BA_ "GenSigStartValue" SG_ 975 HBFS_Lock_Taster_inv 1;
BA_ "GenSigSwitchedByIgnition" SG_ 975 HBFS_Lock_Taster_inv 0;
BA_ "GenSigSendType" SG_ 975 HBFS_MRollo_Schalter 3;
BA_ "GenSigStartValue" SG_ 975 HBFS_MRollo_Schalter 6;
BA_ "GenSigSwitchedByIgnition" SG_ 975 HBFS_MRollo_Schalter 0;
BA_ "Fehlerwert" SG_ 975 HBFS_MRollo_Schalter 7;
BA_ "GenSigSendType" SG_ 975 HBFS_Oben_Block_erw 3;
BA_ "GenSigSwitchedByIgnition" SG_ 975 HBFS_Oben_Block_erw 0;
BA_ "GenSigSendType" SG_ 975 HBFS_SAD_Schalter 3;
BA_ "GenSigSwitchedByIgnition" SG_ 975 HBFS_SAD_Schalter 0;
BA_ "Fehlerwert" SG_ 975 HBFS_SAD_Schalter 15;
BA_ "GenSigSendType" SG_ 975 HBFS_Seitenrollo_hoch 3;
BA_ "GenSigSwitchedByIgnition" SG_ 975 HBFS_Seitenrollo_hoch 0;
BA_ "GenSigSendType" SG_ 975 HBFS_Seitenrollo_tief 3;
BA_ "GenSigSwitchedByIgnition" SG_ 975 HBFS_Seitenrollo_tief 0;
BA_ "GenSigSendType" SG_ 975 HBFS_SK_betaetigt 3;
BA_ "GenSigSwitchedByIgnition" SG_ 975 HBFS_SK_betaetigt 0;
BA_ "GenSigSendType" SG_ 975 HBFS_Sperrklinke 3;
BA_ "GenSigSwitchedByIgnition" SG_ 975 HBFS_Sperrklinke 0;
BA_ "GenSigSendType" SG_ 975 HBFS_Status_eTAG 0;
BA_ "GenSigSwitchedByIgnition" SG_ 975 HBFS_Status_eTAG 0;
BA_ "Fehlerwert" SG_ 975 HBFS_Status_eTAG 3;
BA_ "GenSigSendType" SG_ 975 HBFS_Status_KiSi 3;
BA_ "GenSigSwitchedByIgnition" SG_ 975 HBFS_Status_KiSi 0;
BA_ "GenSigSendType" SG_ 975 HBFS_Status_KiSi_inv 3;
BA_ "GenSigStartValue" SG_ 975 HBFS_Status_KiSi_inv 1;
BA_ "GenSigSwitchedByIgnition" SG_ 975 HBFS_Status_KiSi_inv 0;
BA_ "GenSigSendType" SG_ 975 HBFS_TAG_betaetigt 3;
BA_ "GenSigSwitchedByIgnition" SG_ 975 HBFS_TAG_betaetigt 0;
BA_ "GenSigSendType" SG_ 975 HBFS_TIG_betaetigt 3;
BA_ "GenSigSwitchedByIgnition" SG_ 975 HBFS_TIG_betaetigt 0;
BA_ "GenSigSendType" SG_ 975 HBFS_TIG_betaetigt_oeffnen 3;
BA_ "GenSigSwitchedByIgnition" SG_ 975 HBFS_TIG_betaetigt_oeffnen 0;
BA_ "GenSigSendType" SG_ 975 HBFS_TIG_betaetigt_schliessen 3;
BA_ "GenSigSwitchedByIgnition" SG_ 975 HBFS_TIG_betaetigt_schliessen 0;
BA_ "GenSigSendType" SG_ 975 HBFS_Tuer_geoeffnet 3;
BA_ "GenSigSwitchedByIgnition" SG_ 975 HBFS_Tuer_geoeffnet 0;
BA_ "GenSigSendType" SG_ 975 HBFS_Tuer_Status 3;
BA_ "GenSigSwitchedByIgnition" SG_ 975 HBFS_Tuer_Status 0;
BA_ "Fehlerwert" SG_ 975 HBFS_Tuer_Status 3;
BA_ "GenSigSendType" SG_ 975 HBFS_Tuer_Status_QBit 3;
BA_ "GenSigSwitchedByIgnition" SG_ 975 HBFS_Tuer_Status_QBit 0;
BA_ "GenSigSendType" SG_ 975 HBFS_Tueroeffnen_Warnung 3;
BA_ "GenSigSwitchedByIgnition" SG_ 975 HBFS_Tueroeffnen_Warnung 0;
BA_ "GenSigSendType" SG_ 975 HBFS_Tuerschloss_defekt 0;
BA_ "GenSigSwitchedByIgnition" SG_ 975 HBFS_Tuerschloss_defekt 0;
BA_ "GenSigSendType" SG_ 975 HBFS_UEKB_aktiviert 3;
BA_ "GenSigSwitchedByIgnition" SG_ 975 HBFS_UEKB_aktiviert 0;
BA_ "GenSigSendType" SG_ 975 HBFS_Unlock_Taster 3;
BA_ "GenSigSwitchedByIgnition" SG_ 975 HBFS_Unlock_Taster 0;
BA_ "GenSigSendType" SG_ 975 HBFS_Unten_Block_erw 3;
BA_ "GenSigSwitchedByIgnition" SG_ 975 HBFS_Unten_Block_erw 0;
BA_ "GenSigSendType" SG_ 975 HBFS_verriegelt 3;
BA_ "GenSigSwitchedByIgnition" SG_ 975 HBFS_verriegelt 0;
BA_ "GenSigSendType" SG_ 975 HBFS_Vorraste_betaetigt 3;
BA_ "GenSigSwitchedByIgnition" SG_ 975 HBFS_Vorraste_betaetigt 0;
BA_ "GenSigSendType" SG_ 975 HBFS_Zuziehhilfe_aktiv 3;
BA_ "GenSigSwitchedByIgnition" SG_ 975 HBFS_Zuziehhilfe_aktiv 0;
BA_ "GenSigSendType" SG_ 975 MTHBFS_M_Taste 3;
BA_ "GenSigSwitchedByIgnition" SG_ 975 MTHBFS_M_Taste 0;
BA_ "GenSigSendType" SG_ 975 MTHBFS_Pos1 3;
BA_ "GenSigSwitchedByIgnition" SG_ 975 MTHBFS_Pos1 0;
BA_ "GenSigSendType" SG_ 975 MTHBFS_Pos2 3;
BA_ "GenSigSwitchedByIgnition" SG_ 975 MTHBFS_Pos2 0;
BA_ "GenSigSendType" SG_ 975 MTHBFS_Pos3 3;
BA_ "GenSigSwitchedByIgnition" SG_ 975 MTHBFS_Pos3 0;
BA_ "GenSigSendType" SG_ 975 SSR_HBFS_Pos_Unten 0;
BA_ "GenSigSwitchedByIgnition" SG_ 975 SSR_HBFS_Pos_Unten 0;
BA_ "GenSigSendType" SG_ 974 ASW_Warnung_aktiv_HFS 3;
BA_ "GenSigSwitchedByIgnition" SG_ 974 ASW_Warnung_aktiv_HFS 0;
BA_ "GenSigSendType" SG_ 974 HFS_FH_Bew_hoch 3;
BA_ "GenSigSwitchedByIgnition" SG_ 974 HFS_FH_Bew_hoch 0;
BA_ "GenSigSendType" SG_ 974 HFS_FH_Bew_tief 3;
BA_ "GenSigSwitchedByIgnition" SG_ 974 HFS_FH_Bew_tief 0;
BA_ "GenSigSendType" SG_ 974 HFS_FH_Block 3;
BA_ "GenSigSwitchedByIgnition" SG_ 974 HFS_FH_Block 0;
BA_ "GenSigSendType" SG_ 974 HFS_FH_Fang 3;
BA_ "GenSigSwitchedByIgnition" SG_ 974 HFS_FH_Fang 0;
BA_ "GenSigSendType" SG_ 974 HFS_FH_normiert 3;
BA_ "GenSigSwitchedByIgnition" SG_ 974 HFS_FH_normiert 0;
BA_ "GenSigSendType" SG_ 974 HFS_FH_Oeffnung 3;
BA_ "GenSigSwitchedByIgnition" SG_ 974 HFS_FH_Oeffnung 0;
BA_ "GenSigSendType" SG_ 974 HFS_FH_S_AutoHoch 3;
BA_ "GenSigSwitchedByIgnition" SG_ 974 HFS_FH_S_AutoHoch 0;
BA_ "GenSigSendType" SG_ 974 HFS_FH_S_AutoTief 3;
BA_ "GenSigSwitchedByIgnition" SG_ 974 HFS_FH_S_AutoTief 0;
BA_ "GenSigSendType" SG_ 974 HFS_FH_S_HBFS_AutoHoch 3;
BA_ "GenSigSwitchedByIgnition" SG_ 974 HFS_FH_S_HBFS_AutoHoch 0;
BA_ "GenSigSendType" SG_ 974 HFS_FH_S_HBFS_AutoTief 3;
BA_ "GenSigSwitchedByIgnition" SG_ 974 HFS_FH_S_HBFS_AutoTief 0;
BA_ "GenSigSendType" SG_ 974 HFS_FH_S_HBFS_ManHoch 3;
BA_ "GenSigSwitchedByIgnition" SG_ 974 HFS_FH_S_HBFS_ManHoch 0;
BA_ "GenSigSendType" SG_ 974 HFS_FH_S_HBFS_ManTief 3;
BA_ "GenSigSwitchedByIgnition" SG_ 974 HFS_FH_S_HBFS_ManTief 0;
BA_ "GenSigSendType" SG_ 974 HFS_FH_S_ManHoch 3;
BA_ "GenSigSwitchedByIgnition" SG_ 974 HFS_FH_S_ManHoch 0;
BA_ "GenSigSendType" SG_ 974 HFS_FH_S_ManTief 3;
BA_ "GenSigSwitchedByIgnition" SG_ 974 HFS_FH_S_ManTief 0;
BA_ "GenSigSendType" SG_ 974 HFS_FH_Thermo 3;
BA_ "GenSigSwitchedByIgnition" SG_ 974 HFS_FH_Thermo 0;
BA_ "GenSigSendType" SG_ 974 HFS_gesafet 3;
BA_ "GenSigSwitchedByIgnition" SG_ 974 HFS_gesafet 0;
BA_ "GenSigSendType" SG_ 974 HFS_Heckrollotaster_betaetigt 3;
BA_ "GenSigSwitchedByIgnition" SG_ 974 HFS_Heckrollotaster_betaetigt 0;
BA_ "GenSigSendType" SG_ 974 HFS_Lock_Taster 3;
BA_ "GenSigSwitchedByIgnition" SG_ 974 HFS_Lock_Taster 0;
BA_ "GenSigSendType" SG_ 974 HFS_Lock_Taster_inv 3;
BA_ "GenSigSwitchedByIgnition" SG_ 974 HFS_Lock_Taster_inv 0;
BA_ "GenSigSendType" SG_ 974 HFS_MRollo_Schalter 3;
BA_ "GenSigStartValue" SG_ 974 HFS_MRollo_Schalter 6;
BA_ "GenSigSwitchedByIgnition" SG_ 974 HFS_MRollo_Schalter 0;
BA_ "Fehlerwert" SG_ 974 HFS_MRollo_Schalter 7;
BA_ "GenSigSendType" SG_ 974 HFS_Oben_Block_erw 3;
BA_ "GenSigSwitchedByIgnition" SG_ 974 HFS_Oben_Block_erw 0;
BA_ "GenSigSendType" SG_ 974 HFS_SAD_Schalter 3;
BA_ "GenSigStartValue" SG_ 974 HFS_SAD_Schalter 14;
BA_ "GenSigSwitchedByIgnition" SG_ 974 HFS_SAD_Schalter 0;
BA_ "Fehlerwert" SG_ 974 HFS_SAD_Schalter 15;
BA_ "GenSigSendType" SG_ 974 HFS_Seitenrollo_hoch 3;
BA_ "GenSigSwitchedByIgnition" SG_ 974 HFS_Seitenrollo_hoch 0;
BA_ "GenSigSendType" SG_ 974 HFS_Seitenrollo_tief 3;
BA_ "GenSigSwitchedByIgnition" SG_ 974 HFS_Seitenrollo_tief 0;
BA_ "GenSigSendType" SG_ 974 HFS_SK_betaetigt 3;
BA_ "GenSigSwitchedByIgnition" SG_ 974 HFS_SK_betaetigt 0;
BA_ "GenSigSendType" SG_ 974 HFS_Sperrklinke 3;
BA_ "GenSigSwitchedByIgnition" SG_ 974 HFS_Sperrklinke 0;
BA_ "GenSigSendType" SG_ 974 HFS_Status_eTAG 0;
BA_ "GenSigSwitchedByIgnition" SG_ 974 HFS_Status_eTAG 0;
BA_ "Fehlerwert" SG_ 974 HFS_Status_eTAG 3;
BA_ "GenSigSendType" SG_ 974 HFS_Status_KiSi 3;
BA_ "GenSigSwitchedByIgnition" SG_ 974 HFS_Status_KiSi 0;
BA_ "GenSigSendType" SG_ 974 HFS_TAG_betaetigt 3;
BA_ "GenSigSwitchedByIgnition" SG_ 974 HFS_TAG_betaetigt 0;
BA_ "GenSigSendType" SG_ 974 HFS_TCR_Mode_aktiv 3;
BA_ "GenSigSwitchedByIgnition" SG_ 974 HFS_TCR_Mode_aktiv 0;
BA_ "GenSigSendType" SG_ 974 HFS_TIG_betaetigt 3;
BA_ "GenSigSwitchedByIgnition" SG_ 974 HFS_TIG_betaetigt 0;
BA_ "GenSigSendType" SG_ 974 HFS_TIG_betaetigt_oeffnen 3;
BA_ "GenSigSwitchedByIgnition" SG_ 974 HFS_TIG_betaetigt_oeffnen 0;
BA_ "GenSigSendType" SG_ 974 HFS_TIG_betaetigt_schliessen 3;
BA_ "GenSigSwitchedByIgnition" SG_ 974 HFS_TIG_betaetigt_schliessen 0;
BA_ "GenSigSendType" SG_ 974 HFS_Tuer_geoeffnet 3;
BA_ "GenSigSwitchedByIgnition" SG_ 974 HFS_Tuer_geoeffnet 0;
BA_ "GenSigSendType" SG_ 974 HFS_Tuer_Status 3;
BA_ "GenSigSwitchedByIgnition" SG_ 974 HFS_Tuer_Status 0;
BA_ "Fehlerwert" SG_ 974 HFS_Tuer_Status 3;
BA_ "GenSigSendType" SG_ 974 HFS_Tuer_Status_QBit 0;
BA_ "GenSigSwitchedByIgnition" SG_ 974 HFS_Tuer_Status_QBit 0;
BA_ "GenSigSendType" SG_ 974 HFS_Tueroeffnen_Warnung 3;
BA_ "GenSigSwitchedByIgnition" SG_ 974 HFS_Tueroeffnen_Warnung 0;
BA_ "GenSigSendType" SG_ 974 HFS_Tuerschloss_defekt 0;
BA_ "GenSigSwitchedByIgnition" SG_ 974 HFS_Tuerschloss_defekt 0;
BA_ "GenSigSendType" SG_ 974 HFS_UEKB_aktiviert 3;
BA_ "GenSigSwitchedByIgnition" SG_ 974 HFS_UEKB_aktiviert 0;
BA_ "GenSigSendType" SG_ 974 HFS_Unlock_Taster 3;
BA_ "GenSigSwitchedByIgnition" SG_ 974 HFS_Unlock_Taster 0;
BA_ "GenSigSendType" SG_ 974 HFS_Unten_Block_erw 3;
BA_ "GenSigSwitchedByIgnition" SG_ 974 HFS_Unten_Block_erw 0;
BA_ "GenSigSendType" SG_ 974 HFS_verriegelt 3;
BA_ "GenSigSwitchedByIgnition" SG_ 974 HFS_verriegelt 0;
BA_ "GenSigSendType" SG_ 974 HFS_Vorraste_betaetigt 3;
BA_ "GenSigSwitchedByIgnition" SG_ 974 HFS_Vorraste_betaetigt 0;
BA_ "GenSigSendType" SG_ 974 HFS_Zuziehhilfe_aktiv 3;
BA_ "GenSigSwitchedByIgnition" SG_ 974 HFS_Zuziehhilfe_aktiv 0;
BA_ "GenSigSendType" SG_ 974 MTHFS_M_Taste 3;
BA_ "GenSigSwitchedByIgnition" SG_ 974 MTHFS_M_Taste 0;
BA_ "GenSigSendType" SG_ 974 MTHFS_Pos1 3;
BA_ "GenSigSwitchedByIgnition" SG_ 974 MTHFS_Pos1 0;
BA_ "GenSigSendType" SG_ 974 MTHFS_Pos2 3;
BA_ "GenSigSwitchedByIgnition" SG_ 974 MTHFS_Pos2 0;
BA_ "GenSigSendType" SG_ 974 MTHFS_Pos3 3;
BA_ "GenSigSwitchedByIgnition" SG_ 974 MTHFS_Pos3 0;
BA_ "GenSigSendType" SG_ 974 SSR_HFS_Pos_Unten 0;
BA_ "GenSigSwitchedByIgnition" SG_ 974 SSR_HFS_Pos_Unten 0;
BA_ "GenSigSendType" SG_ 2589283772 QSP_Temperatur_Oel 0;
BA_ "Fehlerwert" SG_ 2589283772 QSP_Temperatur_Oel 127;
BA_ "GenSigSendType" SG_ 2589283772 QSP_Thermische_Belastung 0;
BA_ "Fehlerwert" SG_ 2589283772 QSP_Thermische_Belastung 63;
BA_ "GenSigSendType" SG_ 2589283772 QSP_Warnlampe 0;
BA_ "GenSigSwitchedByIgnition" SG_ 2589283772 QSP_Warnlampe 0;
BA_ "GenSigSendType" SG_ 2589283772 TSL_Hinweis 0;
BA_ "GenSigSwitchedByIgnition" SG_ 2589283772 TSL_Hinweis 0;
BA_ "GenSigSendType" SG_ 2589283772 TSL_Warnung 0;
BA_ "GenSigSwitchedByIgnition" SG_ 2589283772 TSL_Warnung 0;
BA_ "GenSigSendType" SG_ 2589283773 TSR_Hinweis 0;
BA_ "GenSigSwitchedByIgnition" SG_ 2589283773 TSR_Hinweis 0;
BA_ "GenSigSendType" SG_ 2589283773 TSR_Temperatur_Oel 0;
BA_ "Fehlerwert" SG_ 2589283773 TSR_Temperatur_Oel 127;
BA_ "GenSigSendType" SG_ 2589283773 TSR_Thermische_Belastung 0;
BA_ "Fehlerwert" SG_ 2589283773 TSR_Thermische_Belastung 63;
BA_ "GenSigSendType" SG_ 2589283773 TSR_Warnlampe 0;
BA_ "GenSigSendType" SG_ 2589283773 TSR_Warnung 0;
BA_ "GenSigSwitchedByIgnition" SG_ 2589283773 TSR_Warnung 0;
BA_ "GenSigSendType" SG_ 1718 UH_DLS 0;
BA_ "GenSigSwitchedByIgnition" SG_ 1718 UH_DLS 0;
BA_ "GenSigSendType" SG_ 1718 UH_Jahr 0;
BA_ "GenSigSwitchedByIgnition" SG_ 1718 UH_Jahr 0;
BA_ "GenSigSendType" SG_ 1718 UH_Minute 0;
BA_ "GenSigSwitchedByIgnition" SG_ 1718 UH_Minute 0;
BA_ "GenSigSendType" SG_ 1718 UH_Monat 0;
BA_ "GenSigSwitchedByIgnition" SG_ 1718 UH_Monat 0;
BA_ "Fehlerwert" SG_ 1718 UH_Monat 15;
BA_ "GenSigSendType" SG_ 1718 UH_Sekunde 0;
BA_ "GenSigSwitchedByIgnition" SG_ 1718 UH_Sekunde 0;
BA_ "GenSigSendType" SG_ 1718 UH_Stunde 0;
BA_ "GenSigSwitchedByIgnition" SG_ 1718 UH_Stunde 0;
BA_ "GenSigSendType" SG_ 1718 UH_Tag 0;
BA_ "GenSigSwitchedByIgnition" SG_ 1718 UH_Tag 0;
BA_ "GenSigSendType" SG_ 1718 UH_Typ 0;
BA_ "GenSigFuncType" SG_ 1718 UH_Typ 8;
BA_ "GenSigSwitchedByIgnition" SG_ 1718 UH_Typ 0;
BA_ "GenSigSendType" SG_ 995 VD_SpannungsAnf 3;
BA_ "GenSigSwitchedByIgnition" SG_ 995 VD_SpannungsAnf 0;
BA_ "GenSigActiveRepetitions" SG_ 995 VS_BFS_AutoHoch 5;
BA_ "GenSigSendType" SG_ 995 VS_BFS_AutoHoch 4;
BA_ "GenSigSwitchedByIgnition" SG_ 995 VS_BFS_AutoHoch 0;
BA_ "GenSigActiveRepetitions" SG_ 995 VS_BFS_AutoTief 5;
BA_ "GenSigSendType" SG_ 995 VS_BFS_AutoTief 4;
BA_ "GenSigSwitchedByIgnition" SG_ 995 VS_BFS_AutoTief 0;
BA_ "GenSigActiveRepetitions" SG_ 995 VS_BFS_ManHoch 5;
BA_ "GenSigSendType" SG_ 995 VS_BFS_ManHoch 4;
BA_ "GenSigSwitchedByIgnition" SG_ 995 VS_BFS_ManHoch 0;
BA_ "GenSigActiveRepetitions" SG_ 995 VS_BFS_ManTief 5;
BA_ "GenSigSendType" SG_ 995 VS_BFS_ManTief 4;
BA_ "GenSigSwitchedByIgnition" SG_ 995 VS_BFS_ManTief 0;
BA_ "GenSigSendType" SG_ 995 VS_Buzzer 3;
BA_ "GenSigSwitchedByIgnition" SG_ 995 VS_Buzzer 0;
BA_ "GenSigSendType" SG_ 995 VS_FH_BT_Langhub 3;
BA_ "GenSigSwitchedByIgnition" SG_ 995 VS_FH_BT_Langhub 0;
BA_ "GenSigSendType" SG_ 995 VS_FH_FT_Langhub 3;
BA_ "GenSigSwitchedByIgnition" SG_ 995 VS_FH_FT_Langhub 0;
BA_ "GenSigSendType" SG_ 995 VS_FH_HBFS_Langhub 3;
BA_ "GenSigSwitchedByIgnition" SG_ 995 VS_FH_HBFS_Langhub 0;
BA_ "GenSigSendType" SG_ 995 VS_FH_HFS_Langhub 3;
BA_ "GenSigSwitchedByIgnition" SG_ 995 VS_FH_HFS_Langhub 0;
BA_ "GenSigActiveRepetitions" SG_ 995 VS_FS_AutoHoch 5;
BA_ "GenSigSendType" SG_ 995 VS_FS_AutoHoch 4;
BA_ "GenSigSwitchedByIgnition" SG_ 995 VS_FS_AutoHoch 0;
BA_ "GenSigActiveRepetitions" SG_ 995 VS_FS_AutoTief 5;
BA_ "GenSigSendType" SG_ 995 VS_FS_AutoTief 4;
BA_ "GenSigSwitchedByIgnition" SG_ 995 VS_FS_AutoTief 0;
BA_ "GenSigActiveRepetitions" SG_ 995 VS_FS_ManHoch 5;
BA_ "GenSigSendType" SG_ 995 VS_FS_ManHoch 4;
BA_ "GenSigSwitchedByIgnition" SG_ 995 VS_FS_ManHoch 0;
BA_ "GenSigActiveRepetitions" SG_ 995 VS_FS_ManTief 5;
BA_ "GenSigSendType" SG_ 995 VS_FS_ManTief 4;
BA_ "GenSigSwitchedByIgnition" SG_ 995 VS_FS_ManTief 0;
BA_ "GenSigSendType" SG_ 995 VS_Hardtop 3;
BA_ "GenSigSwitchedByIgnition" SG_ 995 VS_Hardtop 0;
BA_ "GenSigActiveRepetitions" SG_ 995 VS_HBFS_AutoHoch 5;
BA_ "GenSigSendType" SG_ 995 VS_HBFS_AutoHoch 4;
BA_ "GenSigSwitchedByIgnition" SG_ 995 VS_HBFS_AutoHoch 0;
BA_ "GenSigActiveRepetitions" SG_ 995 VS_HBFS_AutoTief 5;
BA_ "GenSigSendType" SG_ 995 VS_HBFS_AutoTief 4;
BA_ "GenSigSwitchedByIgnition" SG_ 995 VS_HBFS_AutoTief 0;
BA_ "GenSigActiveRepetitions" SG_ 995 VS_HBFS_ManHoch 5;
BA_ "GenSigSendType" SG_ 995 VS_HBFS_ManHoch 4;
BA_ "GenSigSwitchedByIgnition" SG_ 995 VS_HBFS_ManHoch 0;
BA_ "GenSigActiveRepetitions" SG_ 995 VS_HBFS_ManTief 5;
BA_ "GenSigSendType" SG_ 995 VS_HBFS_ManTief 4;
BA_ "GenSigSwitchedByIgnition" SG_ 995 VS_HBFS_ManTief 0;
BA_ "GenSigSendType" SG_ 995 VS_HD_sperren 3;
BA_ "GenSigSwitchedByIgnition" SG_ 995 VS_HD_sperren 0;
BA_ "GenSigSendType" SG_ 995 VS_Heckschloss_auf 3;
BA_ "GenSigSwitchedByIgnition" SG_ 995 VS_Heckschloss_auf 0;
BA_ "GenSigActiveRepetitions" SG_ 995 VS_HFS_AutoHoch 5;
BA_ "GenSigSendType" SG_ 995 VS_HFS_AutoHoch 4;
BA_ "GenSigSwitchedByIgnition" SG_ 995 VS_HFS_AutoHoch 0;
BA_ "GenSigActiveRepetitions" SG_ 995 VS_HFS_AutoTief 5;
BA_ "GenSigSendType" SG_ 995 VS_HFS_AutoTief 4;
BA_ "GenSigSwitchedByIgnition" SG_ 995 VS_HFS_AutoTief 0;
BA_ "GenSigActiveRepetitions" SG_ 995 VS_HFS_ManHoch 5;
BA_ "GenSigSendType" SG_ 995 VS_HFS_ManHoch 4;
BA_ "GenSigSwitchedByIgnition" SG_ 995 VS_HFS_ManHoch 0;
BA_ "GenSigActiveRepetitions" SG_ 995 VS_HFS_ManTief 5;
BA_ "GenSigSendType" SG_ 995 VS_HFS_ManTief 4;
BA_ "GenSigSwitchedByIgnition" SG_ 995 VS_HFS_ManTief 0;
BA_ "GenSigSendType" SG_ 995 VS_HHS_enable 3;
BA_ "GenSigSwitchedByIgnition" SG_ 995 VS_HHS_enable 0;
BA_ "GenSigSendType" SG_ 995 VS_Lampe_Blk 3;
BA_ "GenSigSwitchedByIgnition" SG_ 995 VS_Lampe_Blk 0;
BA_ "GenSigSendType" SG_ 995 VS_StartStopp_Info 3;
BA_ "GenSigSwitchedByIgnition" SG_ 995 VS_StartStopp_Info 0;
BA_ "Fehlerwert" SG_ 995 VS_StartStopp_Info 3;
BA_ "GenSigSendType" SG_ 995 VS_VD_Bew_auf 3;
BA_ "GenSigSwitchedByIgnition" SG_ 995 VS_VD_Bew_auf 0;
BA_ "GenSigSendType" SG_ 995 VS_VD_Bew_zu 3;
BA_ "GenSigSwitchedByIgnition" SG_ 995 VS_VD_Bew_zu 0;
BA_ "GenSigSendType" SG_ 995 VS_VD_entriegelt 3;
BA_ "GenSigSwitchedByIgnition" SG_ 995 VS_VD_entriegelt 0;
BA_ "GenSigSendType" SG_ 995 VS_VD_Fehler 3;
BA_ "GenSigSwitchedByIgnition" SG_ 995 VS_VD_Fehler 0;
BA_ "GenSigSendType" SG_ 995 VS_VD_offen_ver 3;
BA_ "GenSigSwitchedByIgnition" SG_ 995 VS_VD_offen_ver 0;
BA_ "GenSigSendType" SG_ 995 VS_VD_zu_ver 3;
BA_ "GenSigSwitchedByIgnition" SG_ 995 VS_VD_zu_ver 0;
BA_ "GenSigSendType" SG_ 995 VS_VD_Zwischenposition 3;
BA_ "GenSigSwitchedByIgnition" SG_ 995 VS_VD_Zwischenposition 0;
BA_ "GenSigSendType" SG_ 995 VS_VDKD_auf 3;
BA_ "GenSigSwitchedByIgnition" SG_ 995 VS_VDKD_auf 0;
BA_ "GenSigSendType" SG_ 995 VS_Verdeck_Anf 3;
BA_ "GenSigSwitchedByIgnition" SG_ 995 VS_Verdeck_Anf 0;
BA_ "GenSigSendType" SG_ 995 VS_Windschott_nicht_abgelegt 3;
BA_ "GenSigSwitchedByIgnition" SG_ 995 VS_Windschott_nicht_abgelegt 0;
BA_ "GenSigSendType" SG_ 995 VSG_Meldungen 3;
BA_ "GenSigSwitchedByIgnition" SG_ 995 VSG_Meldungen 0;
BA_ "GenSigSwitchedByIgnition" SG_ 1716 KS_Geheimnis_1 0;
BA_ "GenSigSwitchedByIgnition" SG_ 1716 KS_Geheimnis_2 0;
BA_ "GenSigSwitchedByIgnition" SG_ 1716 KS_Geheimnis_3 0;
BA_ "GenSigSwitchedByIgnition" SG_ 1716 KS_Geheimnis_4 0;
BA_ "GenSigSendType" SG_ 1716 VIN_01_MUX 0;
BA_ "GenSigSwitchedByIgnition" SG_ 1716 VIN_01_MUX 0;
BA_ "GenSigStartValue" SG_ 1716 VIN_1 45;
BA_ "GenSigSwitchedByIgnition" SG_ 1716 VIN_1 0;
BA_ "GenSigStartValue" SG_ 1716 VIN_10 45;
BA_ "GenSigSwitchedByIgnition" SG_ 1716 VIN_10 0;
BA_ "GenSigStartValue" SG_ 1716 VIN_11 45;
BA_ "GenSigSwitchedByIgnition" SG_ 1716 VIN_11 0;
BA_ "GenSigStartValue" SG_ 1716 VIN_12 45;
BA_ "GenSigSwitchedByIgnition" SG_ 1716 VIN_12 0;
BA_ "GenSigStartValue" SG_ 1716 VIN_13 45;
BA_ "GenSigSwitchedByIgnition" SG_ 1716 VIN_13 0;
BA_ "GenSigStartValue" SG_ 1716 VIN_14 45;
BA_ "GenSigSwitchedByIgnition" SG_ 1716 VIN_14 0;
BA_ "GenSigStartValue" SG_ 1716 VIN_15 45;
BA_ "GenSigSwitchedByIgnition" SG_ 1716 VIN_15 0;
BA_ "GenSigStartValue" SG_ 1716 VIN_16 45;
BA_ "GenSigSwitchedByIgnition" SG_ 1716 VIN_16 0;
BA_ "GenSigStartValue" SG_ 1716 VIN_17 45;
BA_ "GenSigSwitchedByIgnition" SG_ 1716 VIN_17 0;
BA_ "GenSigStartValue" SG_ 1716 VIN_2 45;
BA_ "GenSigSwitchedByIgnition" SG_ 1716 VIN_2 0;
BA_ "GenSigStartValue" SG_ 1716 VIN_3 45;
BA_ "GenSigSwitchedByIgnition" SG_ 1716 VIN_3 0;
BA_ "GenSigStartValue" SG_ 1716 VIN_4 45;
BA_ "GenSigSwitchedByIgnition" SG_ 1716 VIN_4 0;
BA_ "GenSigStartValue" SG_ 1716 VIN_5 45;
BA_ "GenSigSwitchedByIgnition" SG_ 1716 VIN_5 0;
BA_ "GenSigStartValue" SG_ 1716 VIN_6 45;
BA_ "GenSigSwitchedByIgnition" SG_ 1716 VIN_6 0;
BA_ "GenSigStartValue" SG_ 1716 VIN_7 45;
BA_ "GenSigSwitchedByIgnition" SG_ 1716 VIN_7 0;
BA_ "GenSigStartValue" SG_ 1716 VIN_8 45;
BA_ "GenSigSwitchedByIgnition" SG_ 1716 VIN_8 0;
BA_ "GenSigStartValue" SG_ 1716 VIN_9 45;
BA_ "GenSigSwitchedByIgnition" SG_ 1716 VIN_9 0;
BA_ "GenSigSendType" SG_ 1057 VLK_01_BZ 0;
BA_ "GenSigFuncType" SG_ 1057 VLK_01_BZ 1;
BA_ "GenSigSwitchedByIgnition" SG_ 1057 VLK_01_BZ 0;
BA_ "GenSigSendType" SG_ 1057 VLK_01_CRC 0;
BA_ "GenSigFuncType" SG_ 1057 VLK_01_CRC 2;
BA_ "GenSigSwitchedByIgnition" SG_ 1057 VLK_01_CRC 0;
BA_ "GenSigSendType" SG_ 1057 VLK_Anf_Antrieb 3;
BA_ "GenSigSwitchedByIgnition" SG_ 1057 VLK_Anf_Antrieb 0;
BA_ "Fehlerwert" SG_ 1057 VLK_Anf_Antrieb 7;
BA_ "GenSigSendType" SG_ 1057 VLK_Anforderung_HMS 3;
BA_ "GenSigSwitchedByIgnition" SG_ 1057 VLK_Anforderung_HMS 0;
BA_ "GenSigSendType" SG_ 1057 VLK_Anforderung_Rollfaehigkeit 0;
BA_ "GenSigSwitchedByIgnition" SG_ 1057 VLK_Anforderung_Rollfaehigkeit 0;
BA_ "GenSigSendType" SG_ 1057 VLK_Antriebsdeaktivierung 3;
BA_ "GenSigSwitchedByIgnition" SG_ 1057 VLK_Antriebsdeaktivierung 0;
BA_ "Fehlerwert" SG_ 1057 VLK_Antriebsdeaktivierung 3;
BA_ "GenSigSendType" SG_ 1057 VLK_autom_Absch_Signalisierung 0;
BA_ "GenSigSwitchedByIgnition" SG_ 1057 VLK_autom_Absch_Signalisierung 0;
BA_ "GenSigSendType" SG_ 1057 VLK_Hinweis_dgr_VLW 3;
BA_ "GenSigSwitchedByIgnition" SG_ 1057 VLK_Hinweis_dgr_VLW 0;
BA_ "GenSigSendType" SG_ 1057 VLK_Hinweis_Fehler_Gurt 3;
BA_ "GenSigSwitchedByIgnition" SG_ 1057 VLK_Hinweis_Fehler_Gurt 0;
BA_ "GenSigSendType" SG_ 1057 VLK_Hinweis_Fehler_Sitz 3;
BA_ "GenSigSwitchedByIgnition" SG_ 1057 VLK_Hinweis_Fehler_Sitz 0;
BA_ "GenSigSendType" SG_ 1057 VLK_Hinweis_Fehler_Tuer 3;
BA_ "GenSigSwitchedByIgnition" SG_ 1057 VLK_Hinweis_Fehler_Tuer 0;
BA_ "GenSigSendType" SG_ 1057 VLK_Hinweis_KA_bevorstehend 3;
BA_ "GenSigSwitchedByIgnition" SG_ 1057 VLK_Hinweis_KA_bevorstehend 0;
BA_ "GenSigSendType" SG_ 1057 VLK_Hinweis_Rollfaehigkeit 3;
BA_ "GenSigSwitchedByIgnition" SG_ 1057 VLK_Hinweis_Rollfaehigkeit 0;
BA_ "GenSigSendType" SG_ 1057 VLK_Hinweis_Weiterfahrt 3;
BA_ "GenSigSwitchedByIgnition" SG_ 1057 VLK_Hinweis_Weiterfahrt 0;
BA_ "GenSigSendType" SG_ 1057 VLK_Parken_beibehalten_HMS 3;
BA_ "GenSigStartValue" SG_ 1057 VLK_Parken_beibehalten_HMS 2;
BA_ "GenSigSwitchedByIgnition" SG_ 1057 VLK_Parken_beibehalten_HMS 0;
BA_ "Fehlerwert" SG_ 1057 VLK_Parken_beibehalten_HMS 3;
BA_ "GenSigSendType" SG_ 1057 VLK_VLW_Anf 3;
BA_ "GenSigSwitchedByIgnition" SG_ 1057 VLK_VLW_Anf 0;
BA_ "GenSigSendType" SG_ 2463978663 VZE_Akustik_Limitwechsel 0;
BA_ "GenSigSendType" SG_ 2463978663 VZE_Akustik_Limitwechsel_Status 0;
BA_ "GenSigSendType" SG_ 2463978663 VZE_Anhaenger_Vmax 3;
BA_ "GenSigStartValue" SG_ 2463978663 VZE_Anhaenger_Vmax 14;
BA_ "Fehlerwert" SG_ 2463978663 VZE_Anhaenger_Vmax 15;
BA_ "GenSigSendType" SG_ 2463978663 VZE_Anzeige_VZ_1 0;
BA_ "GenSigSendType" SG_ 2463978663 VZE_Anzeige_VZ_2 0;
BA_ "GenSigSendType" SG_ 2463978663 VZE_Anzeige_VZ_3 0;
BA_ "GenSigSendType" SG_ 2463978663 VZE_Anzeige_ZS_1 0;
BA_ "GenSigSendType" SG_ 2463978663 VZE_Anzeige_ZS_2 0;
BA_ "GenSigSendType" SG_ 2463978663 VZE_Anzeige_ZS_3 0;
BA_ "GenSigSendType" SG_ 2463978663 VZE_Anzeigemodus 3;
BA_ "GenSigSendType" SG_ 2463978663 VZE_Anzeigeunterdrueck_Zeichen_1 3;
BA_ "GenSigSendType" SG_ 2463978663 VZE_Anzeigeunterdrueck_Zeichen_2 3;
BA_ "GenSigSendType" SG_ 2463978663 VZE_Anzeigeunterdrueck_Zeichen_3 3;
BA_ "GenSigSendType" SG_ 2463978663 VZE_Anzeigeunterdrueck_Zeichen_4 3;
BA_ "GenSigSendType" SG_ 2463978663 VZE_Anzeigeunterdrueck_Zeichen_5 3;
BA_ "GenSigSendType" SG_ 2463978663 VZE_Baustelle 3;
BA_ "GenSigSendType" SG_ 2463978663 VZE_Erweiterte_Information 0;
BA_ "GenSigSendType" SG_ 2463978663 VZE_FoD_Status 0;
BA_ "GenSigSendType" SG_ 2463978663 VZE_Gong 3;
BA_ "GenSigSendType" SG_ 2463978663 VZE_Hinweistext 3;
BA_ "GenSigSendType" SG_ 2463978663 VZE_Hinweistext_03 0;
BA_ "GenSigSendType" SG_ 2463978663 VZE_Land 0;
BA_ "GenSigSendType" SG_ 2463978663 VZE_Modus_OptischeWarnung 0;
BA_ "GenSigSendType" SG_ 2463978663 VZE_SLWF_Status 0;
BA_ "GenSigSendType" SG_ 2463978663 VZE_Tempowarnung_Einheit 0;
BA_ "GenSigSendType" SG_ 2463978663 VZE_Tempowarnung_Offset 0;
BA_ "GenSigSendType" SG_ 2463978663 VZE_Tempowarnung_Status 0;
BA_ "GenSigSendType" SG_ 2463978663 VZE_Umweltinfo_Anhaengerbetrieb 0;
BA_ "GenSigSendType" SG_ 2463978663 VZE_Umweltinfo_Naesse 0;
BA_ "GenSigSendType" SG_ 2463978663 VZE_Umweltinfo_Nebel 0;
BA_ "GenSigSendType" SG_ 2463978663 VZE_Verkehrszeichen_1 3;
BA_ "GenSigSendType" SG_ 2463978663 VZE_Verkehrszeichen_2 3;
BA_ "GenSigSendType" SG_ 2463978663 VZE_Verkehrszeichen_3 3;
BA_ "GenSigSendType" SG_ 2463978663 VZE_Verkehrszeichen_4 3;
BA_ "GenSigSendType" SG_ 2463978663 VZE_Verkehrszeichen_5 3;
BA_ "GenSigSendType" SG_ 2463978663 VZE_Verkehrszeichen_6 0;
BA_ "GenSigSendType" SG_ 2463978663 VZE_Verkehrszeichen_Einheit 3;
BA_ "GenSigSendType" SG_ 2463978663 VZE_Warnung_Verkehrszeichen_1 3;
BA_ "GenSigSendType" SG_ 2463978663 VZE_Warnung_Verkehrszeichen_2 3;
BA_ "GenSigSendType" SG_ 2463978663 VZE_Warnung_Verkehrszeichen_3 3;
BA_ "GenSigSendType" SG_ 2463978663 VZE_Warnung_Verkehrszeichen_4 3;
BA_ "GenSigSendType" SG_ 2463978663 VZE_Warnung_Verkehrszeichen_5 3;
BA_ "GenSigSendType" SG_ 2463978663 VZE_Warnung_VZ_1 0;
BA_ "GenSigSendType" SG_ 2463978663 VZE_Warnung_VZ_2 0;
BA_ "GenSigSendType" SG_ 2463978663 VZE_Warnung_VZ_3 0;
BA_ "GenSigSendType" SG_ 2463978663 VZE_Zeichen_01_Gesetz 3;
BA_ "GenSigSendType" SG_ 2463978663 VZE_Zeichen_01_Kamera 3;
BA_ "GenSigSendType" SG_ 2463978663 VZE_Zeichen_01_KameraWied 3;
BA_ "GenSigSendType" SG_ 2463978663 VZE_Zeichen_01_Karte 3;
BA_ "GenSigSendType" SG_ 2463978663 VZE_Zeichen_02_Gesetz 3;
BA_ "GenSigSendType" SG_ 2463978663 VZE_Zeichen_02_Kamera 3;
BA_ "GenSigSendType" SG_ 2463978663 VZE_Zeichen_02_KameraWied 3;
BA_ "GenSigSendType" SG_ 2463978663 VZE_Zeichen_02_Karte 3;
BA_ "GenSigSendType" SG_ 2463978663 VZE_Zeichen_03_Gesetz 3;
BA_ "GenSigSendType" SG_ 2463978663 VZE_Zeichen_03_Kamera 3;
BA_ "GenSigSendType" SG_ 2463978663 VZE_Zeichen_03_KameraWied 3;
BA_ "GenSigSendType" SG_ 2463978663 VZE_Zeichen_03_Karte 3;
BA_ "GenSigSendType" SG_ 2463978663 VZE_Zeichen_04_Gesetz 3;
BA_ "GenSigSendType" SG_ 2463978663 VZE_Zeichen_04_Kamera 3;
BA_ "GenSigSendType" SG_ 2463978663 VZE_Zeichen_04_KameraWied 3;
BA_ "GenSigSendType" SG_ 2463978663 VZE_Zeichen_04_Karte 3;
BA_ "GenSigSendType" SG_ 2463978663 VZE_Zeichen_05_Entfernung 0;
BA_ "GenSigSendType" SG_ 2463978663 VZE_Zeichen_05_Entfernung_StdA 0;
BA_ "GenSigSendType" SG_ 2463978663 VZE_Zeichen_05_Gesetz 3;
BA_ "GenSigSendType" SG_ 2463978663 VZE_Zeichen_05_Kamera 3;
BA_ "GenSigSendType" SG_ 2463978663 VZE_Zeichen_05_KameraWied 3;
BA_ "GenSigSendType" SG_ 2463978663 VZE_Zeichen_05_Karte 3;
BA_ "GenSigSendType" SG_ 2463978663 VZE_Zeichen_06_Entfernung 0;
BA_ "GenSigSendType" SG_ 2463978663 VZE_Zeichen_06_Entfernung_StdA 0;
BA_ "GenSigSendType" SG_ 2463978663 VZE_Zusatzschild_1 3;
BA_ "GenSigSendType" SG_ 2463978663 VZE_Zusatzschild_2 3;
BA_ "GenSigSendType" SG_ 2463978663 VZE_Zusatzschild_3 3;
BA_ "GenSigSendType" SG_ 2463978663 VZE_Zusatzschild_4 3;
BA_ "GenSigSendType" SG_ 2463978663 VZE_Zusatzschild_5 3;
BA_ "GenSigSendType" SG_ 2463978663 VZE_Zusatzschild_6 0;
BA_ "GenSigSendType" SG_ 2589283476 WH_FSA_HMI_Meldungen_01 0;
BA_ "GenSigSwitchedByIgnition" SG_ 2589283476 WH_FSA_HMI_Meldungen_01 0;
BA_ "GenSigSendType" SG_ 2589283476 WH_Schaltschema_Orientierung 0;
BA_ "GenSigSwitchedByIgnition" SG_ 2589283476 WH_Schaltschema_Orientierung 0;
BA_ "GenSigSendType" SG_ 2589283476 WH_Verbau_Entsperrtaste 0;
BA_ "GenSigSwitchedByIgnition" SG_ 2589283476 WH_Verbau_Entsperrtaste 0;
BA_ "GenSigSendType" SG_ 2589283476 WH_Warnung_02 3;
BA_ "GenSigSwitchedByIgnition" SG_ 2589283476 WH_Warnung_02 0;
BA_ "GenSigSendType" SG_ 2589283476 WH_Warnung_03 3;
BA_ "GenSigSwitchedByIgnition" SG_ 2589283476 WH_Warnung_03 0;
BA_ "GenSigSendType" SG_ 916 GE_Sollgang 4;
BA_ "GenSigSwitchedByIgnition" SG_ 916 GE_Sollgang 0;
BA_ "GenSigSendType" SG_ 916 GE_Stoppverbot_Anz_01 0;
BA_ "GenSigSwitchedByIgnition" SG_ 916 GE_Stoppverbot_Anz_01 0;
BA_ "GenSigSendType" SG_ 916 GE_Stoppverbot_Anz_02 0;
BA_ "GenSigSwitchedByIgnition" SG_ 916 GE_Stoppverbot_Anz_02 0;
BA_ "GenSigSendType" SG_ 916 GE_Stoppverbot_Anz_03 0;
BA_ "GenSigSwitchedByIgnition" SG_ 916 GE_Stoppverbot_Anz_03 0;
BA_ "GenSigSendType" SG_ 916 GE_Stoppverbot_Anz_04 0;
BA_ "GenSigSwitchedByIgnition" SG_ 916 GE_Stoppverbot_Anz_04 0;
BA_ "GenSigSendType" SG_ 916 GE_Stoppverbot_Anz_05 0;
BA_ "GenSigSwitchedByIgnition" SG_ 916 GE_Stoppverbot_Anz_05 0;
BA_ "GenSigSendType" SG_ 916 GE_Stoppverbot_Anz_06 0;
BA_ "GenSigSwitchedByIgnition" SG_ 916 GE_Stoppverbot_Anz_06 0;
BA_ "GenSigSendType" SG_ 916 GE_Stoppverbot_Anz_07 0;
BA_ "GenSigSwitchedByIgnition" SG_ 916 GE_Stoppverbot_Anz_07 0;
BA_ "GenSigSendType" SG_ 916 GE_Stoppverbot_Anz_Std 0;
BA_ "GenSigSwitchedByIgnition" SG_ 916 GE_Stoppverbot_Anz_Std 0;
BA_ "GenSigSendType" SG_ 916 GE_Tipschaltempf_verfuegbar 0;
BA_ "GenSigFuncType" SG_ 916 GE_Tipschaltempf_verfuegbar 8;
BA_ "GenSigSwitchedByIgnition" SG_ 916 GE_Tipschaltempf_verfuegbar 0;
BA_ "GenSigSendType" SG_ 916 GE_Wiederstart_Anz_Std 0;
BA_ "GenSigSwitchedByIgnition" SG_ 916 GE_Wiederstart_Anz_Std 0;
BA_ "GenSigSendType" SG_ 916 WBA_03_BZ 0;
BA_ "GenSigFuncType" SG_ 916 WBA_03_BZ 1;
BA_ "GenSigSwitchedByIgnition" SG_ 916 WBA_03_BZ 0;
BA_ "GenSigSendType" SG_ 916 WBA_03_CRC 0;
BA_ "GenSigFuncType" SG_ 916 WBA_03_CRC 2;
BA_ "GenSigSwitchedByIgnition" SG_ 916 WBA_03_CRC 0;
BA_ "GenSigSendType" SG_ 916 WBA_Anforderung_Akustik 4;
BA_ "GenSigSwitchedByIgnition" SG_ 916 WBA_Anforderung_Akustik 0;
BA_ "GenSigSendType" SG_ 916 WBA_Blinken 3;
BA_ "GenSigSwitchedByIgnition" SG_ 916 WBA_Blinken 0;
BA_ "GenSigSendType" SG_ 916 WBA_eing_Gang_02 4;
BA_ "GenSigSwitchedByIgnition" SG_ 916 WBA_eing_Gang_02 0;
BA_ "GenSigSendType" SG_ 916 WBA_Fahrstufe_02 4;
BA_ "GenSigSwitchedByIgnition" SG_ 916 WBA_Fahrstufe_02 0;
BA_ "GenSigSendType" SG_ 916 WBA_GE_Texte 4;
BA_ "GenSigSwitchedByIgnition" SG_ 916 WBA_GE_Texte 0;
BA_ "GenSigSendType" SG_ 916 WBA_GE_Texte_02 0;
BA_ "GenSigSwitchedByIgnition" SG_ 916 WBA_GE_Texte_02 0;
BA_ "GenSigSendType" SG_ 916 WBA_GE_Warnung_02 4;
BA_ "GenSigSwitchedByIgnition" SG_ 916 WBA_GE_Warnung_02 0;
BA_ "GenSigSendType" SG_ 916 WBA_GE_Zusatzwarnungen 4;
BA_ "GenSigSwitchedByIgnition" SG_ 916 WBA_GE_Zusatzwarnungen 0;
BA_ "GenSigSendType" SG_ 916 WBA_Schaltschema_02 4;
BA_ "GenSigSwitchedByIgnition" SG_ 916 WBA_Schaltschema_02 0;
BA_ "GenSigSendType" SG_ 916 WBA_Schaltschema_Fahreraktion 4;
BA_ "GenSigSwitchedByIgnition" SG_ 916 WBA_Schaltschema_Fahreraktion 0;
BA_ "GenSigSendType" SG_ 916 WBA_Schaltschema_FS_inaktiv 4;
BA_ "GenSigSwitchedByIgnition" SG_ 916 WBA_Schaltschema_FS_inaktiv 0;
BA_ "GenSigSendType" SG_ 916 WBA_Schaltschema_FS_vorwaerts 4;
BA_ "GenSigSwitchedByIgnition" SG_ 916 WBA_Schaltschema_FS_vorwaerts 0;
BA_ "GenSigSendType" SG_ 916 WBA_Schaltschema_Tippgasse 4;
BA_ "GenSigSwitchedByIgnition" SG_ 916 WBA_Schaltschema_Tippgasse 0;
BA_ "GenSigSendType" SG_ 916 WBA_Segeln_aktiv 4;
BA_ "GenSigSwitchedByIgnition" SG_ 916 WBA_Segeln_aktiv 0;
BA_ "GenSigSendType" SG_ 916 WBA_Shiftlock_Lampe 4;
BA_ "GenSigSwitchedByIgnition" SG_ 916 WBA_Shiftlock_Lampe 0;
BA_ "GenSigSendType" SG_ 916 WBA_ZielFahrstufe 3;
BA_ "GenSigSwitchedByIgnition" SG_ 916 WBA_ZielFahrstufe 0;
BA_ "GenSigSendType" SG_ 1361 WFS_Betrieb_Lesespule 3;
BA_ "GenSigSwitchedByIgnition" SG_ 1361 WFS_Betrieb_Lesespule 0;
BA_ "GenSigSendType" SG_ 1361 WFS_ELV_authorisiert 3;
BA_ "GenSigSwitchedByIgnition" SG_ 1361 WFS_ELV_authorisiert 0;
BA_ "GenSigSendType" SG_ 1361 WFS_Fahrerhinweise 3;
BA_ "GenSigSwitchedByIgnition" SG_ 1361 WFS_Fahrerhinweise 0;
BA_ "GenSigSendType" SG_ 1361 WFS_ID_Geb_autorisiert 3;
BA_ "GenSigSwitchedByIgnition" SG_ 1361 WFS_ID_Geb_autorisiert 0;
BA_ "GenSigSendType" SG_ 1361 WFS_ID_Geb_autorisiert_in_Kl15 3;
BA_ "GenSigSwitchedByIgnition" SG_ 1361 WFS_ID_Geb_autorisiert_in_Kl15 0;
BA_ "GenSigSendType" SG_ 1361 WFS_ID_Geb_steckt 3;
BA_ "GenSigSwitchedByIgnition" SG_ 1361 WFS_ID_Geb_steckt 0;
BA_ "GenSigSendType" SG_ 1361 WFS_Klemmenfreigabe 3;
BA_ "GenSigSwitchedByIgnition" SG_ 1361 WFS_Klemmenfreigabe 0;
BA_ "GenSigSendType" SG_ 1361 WFS_Klemmenfreigabe_Signatur 3;
BA_ "GenSigSwitchedByIgnition" SG_ 1361 WFS_Klemmenfreigabe_Signatur 0;
BA_ "GenSigSendType" SG_ 1361 WFS_LF_Aktiv 3;
BA_ "GenSigSwitchedByIgnition" SG_ 1361 WFS_LF_Aktiv 0;
BA_ "GenSigSendType" SG_ 1361 WFS_LZ 3;
BA_ "GenSigSwitchedByIgnition" SG_ 1361 WFS_LZ 0;
BA_ "GenSigSendType" SG_ 1361 WFS_Parken_Status 3;
BA_ "GenSigSwitchedByIgnition" SG_ 1361 WFS_Parken_Status 0;
BA_ "GenSigSendType" SG_ 1361 WFS_Safe 3;
BA_ "GenSigSwitchedByIgnition" SG_ 1361 WFS_Safe 0;
BA_ "GenSigSendType" SG_ 1361 WFS_Schluessel_Fahrberecht 0;
BA_ "GenSigSwitchedByIgnition" SG_ 1361 WFS_Schluessel_Fahrberecht 0;
BA_ "GenSigSendType" SG_ 1361 WFS_Schluessel_Ist 3;
BA_ "GenSigSwitchedByIgnition" SG_ 1361 WFS_Schluessel_Ist 0;
BA_ "GenSigSendType" SG_ 1361 WFS_Schluessel_Soll 3;
BA_ "GenSigSwitchedByIgnition" SG_ 1361 WFS_Schluessel_Soll 0;
BA_ "GenSigSendType" SG_ 1361 WFS_Verbauinfo_ELV 3;
BA_ "GenSigSwitchedByIgnition" SG_ 1361 WFS_Verbauinfo_ELV 0;
BA_ "GenSigSendType" SG_ 34 WFS_Transponder_Req_02_Data 1;
BA_ "GenSigFuncType" SG_ 34 WFS_Transponder_Req_02_Data 9;
BA_ "GenSigSwitchedByIgnition" SG_ 34 WFS_Transponder_Req_02_Data 0;
BA_ "GenSigSendType" SG_ 35 WFS_Transponder_Resp_02_Data 3;
BA_ "GenSigFuncType" SG_ 35 WFS_Transponder_Resp_02_Data 9;
BA_ "GenSigSwitchedByIgnition" SG_ 35 WFS_Transponder_Resp_02_Data 0;
BA_ "GenSigSendType" SG_ 830 WFS_Diag_LF_Aktiv_02 3;
BA_ "GenSigSwitchedByIgnition" SG_ 830 WFS_Diag_LF_Aktiv_02 0;
BA_ "GenSigSendType" SG_ 830 WFS_LF_aktiv_02 3;
BA_ "GenSigSwitchedByIgnition" SG_ 830 WFS_LF_aktiv_02 0;
BA_ "GenSigSendType" SG_ 830 WFS_Transp_Mod_Unterbrechung_02 3;
BA_ "GenSigSwitchedByIgnition" SG_ 830 WFS_Transp_Mod_Unterbrechung_02 0;
BA_ "GenSigSendType" SG_ 830 WFS_Verbau_Transp_Ant_02 3;
BA_ "GenSigSwitchedByIgnition" SG_ 830 WFS_Verbau_Transp_Ant_02 0;
BA_ "GenSigSendType" SG_ 1702 BCM1_SRA_aktiv 3;
BA_ "GenSigSwitchedByIgnition" SG_ 1702 BCM1_SRA_aktiv 0;
BA_ "GenSigActiveRepetitions" SG_ 1702 Heckwischer_Anforderung 3;
BA_ "GenSigSendType" SG_ 1702 Heckwischer_Anforderung 4;
BA_ "GenSigSwitchedByIgnition" SG_ 1702 Heckwischer_Anforderung 0;
BA_ "GenSigSendType" SG_ 1702 Waschen_vorne_aktiv 3;
BA_ "GenSigSwitchedByIgnition" SG_ 1702 Waschen_vorne_aktiv 0;
BA_ "GenSigSendType" SG_ 1702 Wischer1_Wischgeschwindigkeit 0;
BA_ "GenSigStartValue" SG_ 1702 Wischer1_Wischgeschwindigkeit 62;
BA_ "GenSigSwitchedByIgnition" SG_ 1702 Wischer1_Wischgeschwindigkeit 0;
BA_ "Fehlerwert" SG_ 1702 Wischer1_Wischgeschwindigkeit 63;
BA_ "GenSigSendType" SG_ 1702 Wischer_Anzeigetext 3;
BA_ "GenSigSwitchedByIgnition" SG_ 1702 Wischer_Anzeigetext 0;
BA_ "GenSigSendType" SG_ 1702 Wischer_vorne_aktiv 3;
BA_ "GenSigSwitchedByIgnition" SG_ 1702 Wischer_vorne_aktiv 0;
BA_ "GenSigSendType" SG_ 1702 Wischer_vorne_blockiert 3;
BA_ "GenSigSwitchedByIgnition" SG_ 1702 Wischer_vorne_blockiert 0;
BA_ "GenSigSendType" SG_ 1702 Wischer_vorne_defekt 3;
BA_ "GenSigSwitchedByIgnition" SG_ 1702 Wischer_vorne_defekt 0;
BA_ "GenSigSendType" SG_ 1702 Wischer_vorne_Normal 3;
BA_ "GenSigSwitchedByIgnition" SG_ 1702 Wischer_vorne_Normal 0;
BA_ "GenSigSendType" SG_ 1702 Wischer_vorne_Parklage 3;
BA_ "GenSigStartValue" SG_ 1702 Wischer_vorne_Parklage 1;
BA_ "GenSigSwitchedByIgnition" SG_ 1702 Wischer_vorne_Parklage 0;
BA_ "GenSigSendType" SG_ 1702 Wischer_vorne_Schnell 3;
BA_ "GenSigSwitchedByIgnition" SG_ 1702 Wischer_vorne_Schnell 0;
BA_ "GenSigSendType" SG_ 1702 Wischer_WH_PopUp_Anf 3;
BA_ "GenSigSwitchedByIgnition" SG_ 1702 Wischer_WH_PopUp_Anf 0;
BA_ "GenSigSendType" SG_ 1702 Wischer_WH_Typ 0;
BA_ "GenSigSwitchedByIgnition" SG_ 1702 Wischer_WH_Typ 0;
BA_ "GenSigSendType" SG_ 1702 WWSs_01_alt 0;
BA_ "GenSigStartValue" SG_ 1702 WWSs_01_alt 1;
BA_ "GenSigFuncType" SG_ 1702 WWSs_01_alt 5;
BA_ "GenSigSwitchedByIgnition" SG_ 1702 WWSs_01_alt 0;
BA_ "GenSigSendType" SG_ 1602 WIV_Russindex 0;
BA_ "GenSigSwitchedByIgnition" SG_ 1602 WIV_Russindex 0;
BA_ "Fehlerwert" SG_ 1602 WIV_Russindex 65535;
BA_ "GenSigSendType" SG_ 1602 WIV_t_max 0;
BA_ "GenSigStartValue" SG_ 1602 WIV_t_max 24;
BA_ "GenSigSwitchedByIgnition" SG_ 1602 WIV_t_max 0;
BA_ "GenSigSendType" SG_ 1602 WIV_t_min 0;
BA_ "GenSigStartValue" SG_ 1602 WIV_t_min 12;
BA_ "GenSigSwitchedByIgnition" SG_ 1602 WIV_t_min 0;
BA_ "GenSigSendType" SG_ 1602 WIV_Verschleissindex 0;
BA_ "GenSigSwitchedByIgnition" SG_ 1602 WIV_Verschleissindex 0;
BA_ "Fehlerwert" SG_ 1602 WIV_Verschleissindex 65535;
BA_ "GenSigSendType" SG_ 1602 WIV_W_max 0;
BA_ "GenSigStartValue" SG_ 1602 WIV_W_max 31;
BA_ "GenSigSwitchedByIgnition" SG_ 1602 WIV_W_max 0;
BA_ "GenSigSendType" SG_ 1602 WIV_W_min 0;
BA_ "GenSigStartValue" SG_ 1602 WIV_W_min 17;
BA_ "GenSigSwitchedByIgnition" SG_ 1602 WIV_W_min 0;
BA_ "GenSigSendType" SG_ 1140 DI_Screendesign 3;
BA_ "GenSigStartValue" SG_ 1140 DI_Screendesign 6;
BA_ "GenSigSwitchedByIgnition" SG_ 1140 DI_Screendesign 0;
BA_ "Fehlerwert" SG_ 1140 DI_Screendesign 7;
BA_ "GenSigSendType" SG_ 1140 MMI_State 3;
BA_ "GenSigSwitchedByIgnition" SG_ 1140 MMI_State 0;
BA_ "GenSigSendType" SG_ 1140 SI_ICAN 3;
BA_ "GenSigStartValue" SG_ 1140 SI_ICAN 1;
BA_ "GenSigSwitchedByIgnition" SG_ 1140 SI_ICAN 0;
BA_ "GenSigSendType" SG_ 1140 WLC1_Systemzustand 3;
BA_ "GenSigSwitchedByIgnition" SG_ 1140 WLC1_Systemzustand 0;
BA_ "GenSigSendType" SG_ 1140 WLC2_Systemzustand 3;
BA_ "GenSigSwitchedByIgnition" SG_ 1140 WLC2_Systemzustand 0;
BA_ "GenSigSendType" SG_ 1140 ZR_DimOffs_DU_1 3;
BA_ "GenSigStartValue" SG_ 1140 ZR_DimOffs_DU_1 14;
BA_ "GenSigSwitchedByIgnition" SG_ 1140 ZR_DimOffs_DU_1 0;
BA_ "GenSigSendType" SG_ 1140 ZR_DimOffs_DU_2 3;
BA_ "GenSigStartValue" SG_ 1140 ZR_DimOffs_DU_2 14;
BA_ "GenSigSwitchedByIgnition" SG_ 1140 ZR_DimOffs_DU_2 0;
BA_ "GenSigSendType" SG_ 1140 ZR_DimOffs_DU_3 3;
BA_ "GenSigStartValue" SG_ 1140 ZR_DimOffs_DU_3 14;
BA_ "GenSigSwitchedByIgnition" SG_ 1140 ZR_DimOffs_DU_3 0;
BA_ "GenSigSendType" SG_ 1140 ZR_DimOffs_DU_4 3;
BA_ "GenSigSendType" SG_ 1140 ZR_Lenkerposition 0;
BA_ "GenSigSwitchedByIgnition" SG_ 1140 ZR_Lenkerposition 0;
BA_ "GenSigSendType" SG_ 1140 ZR_State_DU_1 3;
BA_ "GenSigSwitchedByIgnition" SG_ 1140 ZR_State_DU_1 0;
BA_ "GenSigSendType" SG_ 1140 ZR_State_DU_2 3;
BA_ "GenSigSwitchedByIgnition" SG_ 1140 ZR_State_DU_2 0;
BA_ "GenSigSendType" SG_ 1140 ZR_State_DU_3 3;
BA_ "GenSigSwitchedByIgnition" SG_ 1140 ZR_State_DU_3 0;
BA_ "GenSigSendType" SG_ 1140 ZR_State_DU_4 3;
BA_ "GenSigSendType" SG_ 1140 ZR_WecktGesp 3;
BA_ "GenSigSwitchedByIgnition" SG_ 1140 ZR_WecktGesp 0;
BA_ "GenSigSendType" SG_ 1411 BCM_FH_Freigabe 3;
BA_ "GenSigSwitchedByIgnition" SG_ 1411 BCM_FH_Freigabe 0;
BA_ "GenSigSendType" SG_ 1411 BCM_HSK_Freigabe 3;
BA_ "GenSigSwitchedByIgnition" SG_ 1411 BCM_HSK_Freigabe 0;
BA_ "GenSigSendType" SG_ 1411 BCM_Komfortfkt_Freigabe 3;
BA_ "GenSigSwitchedByIgnition" SG_ 1411 BCM_Komfortfkt_Freigabe 0;
BA_ "GenSigSendType" SG_ 1411 BCM_Tankklappensteller_Fehler 0;
BA_ "GenSigSwitchedByIgnition" SG_ 1411 BCM_Tankklappensteller_Fehler 0;
BA_ "Fehlerwert" SG_ 1411 BCM_Tankklappensteller_Fehler 1;
BA_ "GenSigSendType" SG_ 1411 BCM_Verdeck_Freigabe 3;
BA_ "GenSigSwitchedByIgnition" SG_ 1411 BCM_Verdeck_Freigabe 0;
BA_ "GenSigSendType" SG_ 1411 DWA_aktiv 3;
BA_ "GenSigSwitchedByIgnition" SG_ 1411 DWA_aktiv 0;
BA_ "GenSigSendType" SG_ 1411 FBS_IDG_in_Reichweite 6;
BA_ "GenSigSwitchedByIgnition" SG_ 1411 FBS_IDG_in_Reichweite 0;
BA_ "GenSigSendType" SG_ 1411 FBS_Warn_Schluessel_Batt 3;
BA_ "GenSigSwitchedByIgnition" SG_ 1411 FBS_Warn_Schluessel_Batt 0;
BA_ "GenSigSendType" SG_ 1411 FFB_Auf_Taste 6;
BA_ "GenSigSwitchedByIgnition" SG_ 1411 FFB_Auf_Taste 0;
BA_ "GenSigSendType" SG_ 1411 FFB_CarFinder 6;
BA_ "GenSigSwitchedByIgnition" SG_ 1411 FFB_CarFinder 0;
BA_ "GenSigSendType" SG_ 1411 FFB_HDF_Taste 6;
BA_ "GenSigSwitchedByIgnition" SG_ 1411 FFB_HDF_Taste 0;
BA_ "GenSigSendType" SG_ 1411 FFB_Komfortoeffnen 6;
BA_ "GenSigSwitchedByIgnition" SG_ 1411 FFB_Komfortoeffnen 0;
BA_ "GenSigSendType" SG_ 1411 FFB_Komfortschliessen 6;
BA_ "GenSigSwitchedByIgnition" SG_ 1411 FFB_Komfortschliessen 0;
BA_ "GenSigSendType" SG_ 1411 FFB_Panik_Taste 6;
BA_ "GenSigSwitchedByIgnition" SG_ 1411 FFB_Panik_Taste 0;
BA_ "GenSigSendType" SG_ 1411 FFB_Zu_Taste 6;
BA_ "GenSigSwitchedByIgnition" SG_ 1411 FFB_Zu_Taste 0;
BA_ "GenSigSendType" SG_ 1411 HBFS_gesafet 3;
BA_ "GenSigSwitchedByIgnition" SG_ 1411 HBFS_gesafet 0;
BA_ "GenSigSendType" SG_ 1411 HBFS_verriegelt 3;
BA_ "GenSigSwitchedByIgnition" SG_ 1411 HBFS_verriegelt 0;
BA_ "GenSigSendType" SG_ 1411 HD_Hauptraste 3;
BA_ "GenSigSwitchedByIgnition" SG_ 1411 HD_Hauptraste 0;
BA_ "GenSigSendType" SG_ 1411 HD_Vorraste 3;
BA_ "GenSigSwitchedByIgnition" SG_ 1411 HD_Vorraste 0;
BA_ "GenSigSendType" SG_ 1411 HFS_gesafet 3;
BA_ "GenSigSwitchedByIgnition" SG_ 1411 HFS_gesafet 0;
BA_ "GenSigSendType" SG_ 1411 HFS_verriegelt 3;
BA_ "GenSigSwitchedByIgnition" SG_ 1411 HFS_verriegelt 0;
BA_ "GenSigSendType" SG_ 1411 IRUE_aktiv 3;
BA_ "GenSigSwitchedByIgnition" SG_ 1411 IRUE_aktiv 0;
BA_ "GenSigSendType" SG_ 1411 IRUE_Taster_Fkts_LED 3;
BA_ "GenSigSwitchedByIgnition" SG_ 1411 IRUE_Taster_Fkts_LED 0;
BA_ "GenSigSendType" SG_ 1411 VIP_Sensor_STSG_HBFS_betaetigt 6;
BA_ "GenSigSwitchedByIgnition" SG_ 1411 VIP_Sensor_STSG_HBFS_betaetigt 0;
BA_ "GenSigSendType" SG_ 1411 VIP_Sensor_STSG_HFS_betaetigt 6;
BA_ "GenSigSwitchedByIgnition" SG_ 1411 VIP_Sensor_STSG_HFS_betaetigt 0;
BA_ "GenSigSendType" SG_ 1411 ZV_Anf_Challenge_Auth 6;
BA_ "GenSigSwitchedByIgnition" SG_ 1411 ZV_Anf_Challenge_Auth 0;
BA_ "GenSigSendType" SG_ 1411 ZV_BT_offen 3;
BA_ "GenSigSwitchedByIgnition" SG_ 1411 ZV_BT_offen 0;
BA_ "GenSigSendType" SG_ 1411 ZV_Einzeltuerentriegelung 3;
BA_ "GenSigSwitchedByIgnition" SG_ 1411 ZV_Einzeltuerentriegelung 0;
BA_ "GenSigSendType" SG_ 1411 ZV_eRWK_Umfeld_Pruefung 6;
BA_ "GenSigSwitchedByIgnition" SG_ 1411 ZV_eRWK_Umfeld_Pruefung 0;
BA_ "GenSigSendType" SG_ 1411 ZV_FT_offen 3;
BA_ "GenSigSwitchedByIgnition" SG_ 1411 ZV_FT_offen 0;
BA_ "GenSigSendType" SG_ 1411 ZV_gesafet_extern_ist 3;
BA_ "GenSigSwitchedByIgnition" SG_ 1411 ZV_gesafet_extern_ist 0;
BA_ "GenSigSendType" SG_ 1411 ZV_gesafet_extern_soll 3;
BA_ "GenSigSwitchedByIgnition" SG_ 1411 ZV_gesafet_extern_soll 0;
BA_ "GenSigSendType" SG_ 1411 ZV_HBFS_offen 3;
BA_ "GenSigSwitchedByIgnition" SG_ 1411 ZV_HBFS_offen 0;
BA_ "GenSigSendType" SG_ 1411 ZV_HD_offen 3;
BA_ "GenSigSwitchedByIgnition" SG_ 1411 ZV_HD_offen 0;
BA_ "GenSigSendType" SG_ 1411 ZV_Heckeinzelentriegelung 3;
BA_ "GenSigSwitchedByIgnition" SG_ 1411 ZV_Heckeinzelentriegelung 0;
BA_ "GenSigSendType" SG_ 1411 ZV_HFS_offen 3;
BA_ "GenSigSwitchedByIgnition" SG_ 1411 ZV_HFS_offen 0;
BA_ "GenSigSendType" SG_ 1411 ZV_HS_offen 3;
BA_ "GenSigSwitchedByIgnition" SG_ 1411 ZV_HS_offen 0;
BA_ "GenSigSendType" SG_ 1411 ZV_ist_Zustand_verfuegbar 3;
BA_ "GenSigSwitchedByIgnition" SG_ 1411 ZV_ist_Zustand_verfuegbar 0;
BA_ "GenSigSendType" SG_ 1411 ZV_Oeffnungsmodus 3;
BA_ "GenSigSwitchedByIgnition" SG_ 1411 ZV_Oeffnungsmodus 0;
BA_ "GenSigSendType" SG_ 1411 ZV_Rollo_auf 3;
BA_ "GenSigSwitchedByIgnition" SG_ 1411 ZV_Rollo_auf 0;
BA_ "GenSigSendType" SG_ 1411 ZV_Rollo_zu 3;
BA_ "GenSigSwitchedByIgnition" SG_ 1411 ZV_Rollo_zu 0;
BA_ "GenSigSendType" SG_ 1411 ZV_SAD_auf 3;
BA_ "GenSigSwitchedByIgnition" SG_ 1411 ZV_SAD_auf 0;
BA_ "GenSigSendType" SG_ 1411 ZV_SAD_zu 3;
BA_ "GenSigSwitchedByIgnition" SG_ 1411 ZV_SAD_zu 0;
BA_ "GenSigSendType" SG_ 1411 ZV_SafeFunktion_aktiv 3;
BA_ "GenSigSwitchedByIgnition" SG_ 1411 ZV_SafeFunktion_aktiv 0;
BA_ "GenSigSendType" SG_ 1411 ZV_Schluessel_Zugang 3;
BA_ "GenSigSwitchedByIgnition" SG_ 1411 ZV_Schluessel_Zugang 0;
BA_ "GenSigSendType" SG_ 1411 ZV_STSG_Crashzustand 4;
BA_ "GenSigSwitchedByIgnition" SG_ 1411 ZV_STSG_Crashzustand 0;
BA_ "GenSigSendType" SG_ 1411 ZV_STSG_eKiSi_defekt 4;
BA_ "GenSigSwitchedByIgnition" SG_ 1411 ZV_STSG_eKiSi_defekt 0;
BA_ "GenSigSendType" SG_ 1411 ZV_STSG_HBFS_Anf 3;
BA_ "GenSigSwitchedByIgnition" SG_ 1411 ZV_STSG_HBFS_Anf 0;
BA_ "GenSigSendType" SG_ 1411 ZV_STSG_HFS_Anf 3;
BA_ "GenSigSwitchedByIgnition" SG_ 1411 ZV_STSG_HFS_Anf 0;
BA_ "GenSigSendType" SG_ 1411 ZV_Tankklappe_offen 0;
BA_ "GenSigSwitchedByIgnition" SG_ 1411 ZV_Tankklappe_offen 0;
BA_ "GenSigSendType" SG_ 1411 ZV_verriegeln_Anf 6;
BA_ "GenSigSwitchedByIgnition" SG_ 1411 ZV_verriegeln_Anf 0;
BA_ "GenSigSendType" SG_ 1411 ZV_verriegelt_extern_ist 3;
BA_ "GenSigSwitchedByIgnition" SG_ 1411 ZV_verriegelt_extern_ist 0;
BA_ "GenSigSendType" SG_ 1411 ZV_verriegelt_extern_soll 3;
BA_ "GenSigSwitchedByIgnition" SG_ 1411 ZV_verriegelt_extern_soll 0;
BA_ "GenSigSendType" SG_ 1411 ZV_verriegelt_intern_ist 3;
BA_ "GenSigSwitchedByIgnition" SG_ 1411 ZV_verriegelt_intern_ist 0;
BA_ "GenSigSendType" SG_ 1411 ZV_verriegelt_intern_soll 3;
BA_ "GenSigSwitchedByIgnition" SG_ 1411 ZV_verriegelt_intern_soll 0;
BA_ "GenSigSendType" SG_ 1411 ZV_verriegelt_soll 3;
BA_ "GenSigSwitchedByIgnition" SG_ 1411 ZV_verriegelt_soll 0;
BA_REL_ "GenSigTimeoutTime" BU_SG_REL_ ELV SG_ 1361 WFS_Schluessel_Ist 2000;
BA_REL_ "GenSigTimeoutTime" BU_SG_REL_ ELV SG_ 1411 ZV_verriegelt_extern_soll 2000;
BA_REL_ "GenSigTimeoutTime" BU_SG_REL_ ELV SG_ 1411 ZV_gesafet_extern_soll 2000;
BA_REL_ "GenSigTimeoutTime" BU_SG_REL_ Gateway_Max SG_ 1718 UH_Typ 5000;
BA_REL_ "GenSigTimeoutTime" BU_SG_REL_ Gateway_Max SG_ 1718 UH_DLS 5000;
BA_REL_ "GenSigTimeoutTime" BU_SG_REL_ Gateway_Max SG_ 1718 UH_Monat 5000;
BA_REL_ "GenSigTimeoutTime" BU_SG_REL_ Gateway_Max SG_ 1718 UH_Jahr 5000;
BA_REL_ "GenSigTimeoutTime" BU_SG_REL_ Gateway_Max SG_ 1718 UH_Tag 5000;
BA_REL_ "GenSigTimeoutTime" BU_SG_REL_ Gateway_Max SG_ 1718 UH_Stunde 5000;
BA_REL_ "GenSigTimeoutTime" BU_SG_REL_ Gateway_Max SG_ 1718 UH_Minute 5000;
BA_REL_ "GenSigTimeoutTime" BU_SG_REL_ Gateway_Max SG_ 1718 UH_Sekunde 5000;
BA_REL_ "GenSigTimeoutTime" BU_SG_REL_ HUD SG_ 1716 VIN_01_MUX 2000;
BA_REL_ "GenSigTimeoutTime" BU_SG_REL_ HUD SG_ 1716 VIN_4 2000;
BA_REL_ "GenSigTimeoutTime" BU_SG_REL_ HUD SG_ 1716 VIN_11 2000;
BA_REL_ "GenSigTimeoutTime" BU_SG_REL_ HUD SG_ 1716 VIN_5 2000;
BA_REL_ "GenSigTimeoutTime" BU_SG_REL_ HUD SG_ 1716 VIN_12 2000;
BA_REL_ "GenSigTimeoutTime" BU_SG_REL_ HUD SG_ 1716 VIN_6 2000;
BA_REL_ "GenSigTimeoutTime" BU_SG_REL_ HUD SG_ 1716 VIN_13 2000;
BA_REL_ "GenSigTimeoutTime" BU_SG_REL_ HUD SG_ 1716 VIN_7 2000;
BA_REL_ "GenSigTimeoutTime" BU_SG_REL_ HUD SG_ 1716 VIN_14 2000;
BA_REL_ "GenSigTimeoutTime" BU_SG_REL_ HUD SG_ 1716 VIN_1 2000;
BA_REL_ "GenSigTimeoutTime" BU_SG_REL_ HUD SG_ 1716 VIN_8 2000;
BA_REL_ "GenSigTimeoutTime" BU_SG_REL_ HUD SG_ 1716 VIN_15 2000;
BA_REL_ "GenSigTimeoutTime" BU_SG_REL_ HUD SG_ 1716 VIN_2 2000;
BA_REL_ "GenSigTimeoutTime" BU_SG_REL_ HUD SG_ 1716 VIN_9 2000;
BA_REL_ "GenSigTimeoutTime" BU_SG_REL_ HUD SG_ 1716 VIN_16 2000;
BA_REL_ "GenSigTimeoutTime" BU_SG_REL_ HUD SG_ 1716 VIN_3 2000;
BA_REL_ "GenSigTimeoutTime" BU_SG_REL_ HUD SG_ 1716 VIN_10 2000;
BA_REL_ "GenSigTimeoutTime" BU_SG_REL_ HUD SG_ 1716 VIN_17 2000;
BA_REL_ "GenSigTimeoutTime" BU_SG_REL_ HUD SG_ 2463978663 VZE_Anzeigemodus 2000;
BA_REL_ "GenSigTimeoutTime" BU_SG_REL_ HUD SG_ 2463978663 VZE_Warnung_Verkehrszeichen_1 2000;
BA_REL_ "GenSigTimeoutTime" BU_SG_REL_ HUD SG_ 2463978663 VZE_Zeichen_01_Kamera 2000;
BA_REL_ "GenSigTimeoutTime" BU_SG_REL_ HUD SG_ 2463978663 VZE_Zeichen_01_Karte 2000;
BA_REL_ "GenSigTimeoutTime" BU_SG_REL_ HUD SG_ 2463978663 VZE_FoD_Status 2000;
BA_REL_ "GenSigTimeoutTime" BU_SG_REL_ HUD SG_ 916 WBA_Fahrstufe_02 1600;
BA_REL_ "GenSigTimeoutTime" BU_SG_REL_ HUD SG_ 916 WBA_eing_Gang_02 1600;
BA_REL_ "GenSigTimeoutTime" BU_SG_REL_ Kombi SG_ 997 TSG_FT_02_CRC 1000;
BA_REL_ "GenSigTimeoutTime" BU_SG_REL_ Kombi SG_ 997 TSG_FT_02_BZ 1000;
BA_REL_ "GenSigTimeoutTime" BU_SG_REL_ Kombi SG_ 2589283772 TSL_Warnung 5000;
BA_REL_ "GenSigTimeoutTime" BU_SG_REL_ Kombi SG_ 2589283772 TSL_Hinweis 5000;
BA_REL_ "GenSigTimeoutTime" BU_SG_REL_ Kombi SG_ 2589283773 TSR_Warnung 5000;
BA_REL_ "GenSigTimeoutTime" BU_SG_REL_ Kombi SG_ 2589283773 TSR_Hinweis 5000;
BA_REL_ "GenSigTimeoutTime" BU_SG_REL_ Kombi SG_ 995 VSG_Meldungen 1000;
BA_REL_ "GenSigTimeoutTime" BU_SG_REL_ Kombi SG_ 1716 VIN_01_MUX 2000;
BA_REL_ "GenSigTimeoutTime" BU_SG_REL_ Kombi SG_ 1716 VIN_4 2000;
BA_REL_ "GenSigTimeoutTime" BU_SG_REL_ Kombi SG_ 1716 VIN_11 2000;
BA_REL_ "GenSigTimeoutTime" BU_SG_REL_ Kombi SG_ 1716 VIN_5 2000;
BA_REL_ "GenSigTimeoutTime" BU_SG_REL_ Kombi SG_ 1716 VIN_12 2000;
BA_REL_ "GenSigTimeoutTime" BU_SG_REL_ Kombi SG_ 1716 VIN_6 2000;
BA_REL_ "GenSigTimeoutTime" BU_SG_REL_ Kombi SG_ 1716 VIN_13 2000;
BA_REL_ "GenSigTimeoutTime" BU_SG_REL_ Kombi SG_ 1716 VIN_7 2000;
BA_REL_ "GenSigTimeoutTime" BU_SG_REL_ Kombi SG_ 1716 VIN_14 2000;
BA_REL_ "GenSigTimeoutTime" BU_SG_REL_ Kombi SG_ 1716 VIN_1 2000;
BA_REL_ "GenSigTimeoutTime" BU_SG_REL_ Kombi SG_ 1716 VIN_8 2000;
BA_REL_ "GenSigTimeoutTime" BU_SG_REL_ Kombi SG_ 1716 VIN_15 2000;
BA_REL_ "GenSigTimeoutTime" BU_SG_REL_ Kombi SG_ 1716 VIN_2 2000;
BA_REL_ "GenSigTimeoutTime" BU_SG_REL_ Kombi SG_ 1716 VIN_9 2000;
BA_REL_ "GenSigTimeoutTime" BU_SG_REL_ Kombi SG_ 1716 VIN_16 2000;
BA_REL_ "GenSigTimeoutTime" BU_SG_REL_ Kombi SG_ 1716 VIN_3 2000;
BA_REL_ "GenSigTimeoutTime" BU_SG_REL_ Kombi SG_ 1716 VIN_10 2000;
BA_REL_ "GenSigTimeoutTime" BU_SG_REL_ Kombi SG_ 1716 VIN_17 2000;
BA_REL_ "GenSigTimeoutTime" BU_SG_REL_ Kombi SG_ 1057 VLK_Hinweis_Weiterfahrt 1000;
BA_REL_ "GenSigTimeoutTime" BU_SG_REL_ Kombi SG_ 1057 VLK_Hinweis_Fehler_Gurt 1000;
BA_REL_ "GenSigTimeoutTime" BU_SG_REL_ Kombi SG_ 1057 VLK_Hinweis_Fehler_Sitz 1000;
BA_REL_ "GenSigTimeoutTime" BU_SG_REL_ Kombi SG_ 1057 VLK_Hinweis_Fehler_Tuer 1000;
BA_REL_ "GenSigTimeoutTime" BU_SG_REL_ Kombi SG_ 1057 VLK_Hinweis_dgr_VLW 1000;
BA_REL_ "GenSigTimeoutTime" BU_SG_REL_ Kombi SG_ 1057 VLK_Hinweis_KA_bevorstehend 1000;
BA_REL_ "GenSigTimeoutTime" BU_SG_REL_ Kombi SG_ 2463978663 VZE_Anzeigemodus 2000;
BA_REL_ "GenSigTimeoutTime" BU_SG_REL_ Kombi SG_ 2463978663 VZE_Akustik_Limitwechsel 2000;
BA_REL_ "GenSigTimeoutTime" BU_SG_REL_ Kombi SG_ 2463978663 VZE_Modus_OptischeWarnung 2000;
BA_REL_ "GenSigTimeoutTime" BU_SG_REL_ Kombi SG_ 2463978663 VZE_FoD_Status 2000;
BA_REL_ "GenSigTimeoutTime" BU_SG_REL_ Kombi SG_ 2589283476 WH_Warnung_02 5000;
BA_REL_ "GenSigTimeoutTime" BU_SG_REL_ Kombi SG_ 2589283476 WH_Verbau_Entsperrtaste 5000;
BA_REL_ "GenSigTimeoutTime" BU_SG_REL_ Kombi SG_ 2589283476 WH_Schaltschema_Orientierung 5000;
BA_REL_ "GenSigTimeoutTime" BU_SG_REL_ Kombi SG_ 2589283476 WH_FSA_HMI_Meldungen_01 5000;
BA_REL_ "GenSigTimeoutTime" BU_SG_REL_ Kombi SG_ 916 WBA_03_CRC 1600;
BA_REL_ "GenSigTimeoutTime" BU_SG_REL_ Kombi SG_ 916 WBA_03_BZ 1600;
BA_REL_ "GenSigTimeoutTime" BU_SG_REL_ Kombi SG_ 916 WBA_Fahrstufe_02 1600;
BA_REL_ "GenSigTimeoutTime" BU_SG_REL_ Kombi SG_ 916 WBA_GE_Warnung_02 1600;
BA_REL_ "GenSigTimeoutTime" BU_SG_REL_ Kombi SG_ 916 WBA_eing_Gang_02 1600;
BA_REL_ "GenSigTimeoutTime" BU_SG_REL_ Kombi SG_ 916 WBA_GE_Texte 1600;
BA_REL_ "GenSigTimeoutTime" BU_SG_REL_ Kombi SG_ 916 WBA_Segeln_aktiv 1600;
BA_REL_ "GenSigTimeoutTime" BU_SG_REL_ Kombi SG_ 916 WBA_Schaltschema_02 1600;
BA_REL_ "GenSigTimeoutTime" BU_SG_REL_ Kombi SG_ 916 WBA_Schaltschema_FS_inaktiv 1600;
BA_REL_ "GenSigTimeoutTime" BU_SG_REL_ Kombi SG_ 916 WBA_GE_Zusatzwarnungen 1600;
BA_REL_ "GenSigTimeoutTime" BU_SG_REL_ Kombi SG_ 916 GE_Sollgang 1600;
BA_REL_ "GenSigTimeoutTime" BU_SG_REL_ Kombi SG_ 916 GE_Tipschaltempf_verfuegbar 1600;
BA_REL_ "GenSigTimeoutTime" BU_SG_REL_ Kombi SG_ 916 WBA_GE_Texte_02 1600;
BA_REL_ "GenSigTimeoutTime" BU_SG_REL_ Kombi SG_ 916 WBA_Schaltschema_Tippgasse 1600;
BA_REL_ "GenSigTimeoutTime" BU_SG_REL_ Kombi SG_ 916 WBA_Schaltschema_Fahreraktion 1600;
BA_REL_ "GenSigTimeoutTime" BU_SG_REL_ Kombi SG_ 916 WBA_Schaltschema_FS_vorwaerts 1600;
BA_REL_ "GenSigTimeoutTime" BU_SG_REL_ Kombi SG_ 916 WBA_Shiftlock_Lampe 1600;
BA_REL_ "GenSigTimeoutTime" BU_SG_REL_ Kombi SG_ 916 WBA_Anforderung_Akustik 1600;
BA_REL_ "GenSigTimeoutTime" BU_SG_REL_ Kombi SG_ 1361 WFS_Schluessel_Fahrberecht 2000;
BA_REL_ "GenSigTimeoutTime" BU_SG_REL_ Kombi SG_ 1361 WFS_Schluessel_Soll 2000;
BA_REL_ "GenSigTimeoutTime" BU_SG_REL_ Kombi SG_ 1361 WFS_Schluessel_Ist 2000;
BA_REL_ "GenSigTimeoutTime" BU_SG_REL_ Kombi SG_ 1361 WFS_Safe 2000;
BA_REL_ "GenSigTimeoutTime" BU_SG_REL_ Kombi SG_ 1361 WFS_LZ 2000;
BA_REL_ "GenSigTimeoutTime" BU_SG_REL_ Kombi SG_ 1361 WFS_Fahrerhinweise 2000;
BA_REL_ "GenSigTimeoutTime" BU_SG_REL_ Kombi SG_ 1702 Wischer_vorne_defekt 5000;
BA_REL_ "GenSigTimeoutTime" BU_SG_REL_ Kombi SG_ 1702 Wischer_WH_Typ 5000;
BA_REL_ "GenSigTimeoutTime" BU_SG_REL_ Kombi SG_ 1702 Wischer_WH_PopUp_Anf 5000;
BA_REL_ "GenSigTimeoutTime" BU_SG_REL_ Kombi SG_ 1602 WIV_Verschleissindex 5000;
BA_REL_ "GenSigTimeoutTime" BU_SG_REL_ Kombi SG_ 1602 WIV_Russindex 5000;
BA_REL_ "GenSigTimeoutTime" BU_SG_REL_ Kombi SG_ 1602 WIV_t_min 5000;
BA_REL_ "GenSigTimeoutTime" BU_SG_REL_ Kombi SG_ 1602 WIV_t_max 5000;
BA_REL_ "GenSigTimeoutTime" BU_SG_REL_ Kombi SG_ 1602 WIV_W_min 5000;
BA_REL_ "GenSigTimeoutTime" BU_SG_REL_ Kombi SG_ 1602 WIV_W_max 5000;
BA_REL_ "GenSigTimeoutTime" BU_SG_REL_ Kombi SG_ 1140 DI_Screendesign 5000;
BA_REL_ "GenSigTimeoutTime" BU_SG_REL_ Kombi SG_ 1411 ZV_STSG_Crashzustand 2000;
BA_REL_ "GenSigTimeoutTime" BU_SG_REL_ Kombi SG_ 1411 ZV_STSG_eKiSi_defekt 2000;
BA_REL_ "GenSigTimeoutTime" BU_SG_REL_ Kombi SG_ 1411 ZV_verriegelt_extern_ist 2000;
BA_REL_ "GenSigTimeoutTime" BU_SG_REL_ Kombi SG_ 1411 ZV_FT_offen 2000;
BA_REL_ "GenSigTimeoutTime" BU_SG_REL_ Kombi SG_ 1411 ZV_BT_offen 2000;
BA_REL_ "GenSigTimeoutTime" BU_SG_REL_ Kombi SG_ 1411 ZV_HFS_offen 2000;
BA_REL_ "GenSigTimeoutTime" BU_SG_REL_ Kombi SG_ 1411 ZV_HBFS_offen 2000;
BA_REL_ "GenSigTimeoutTime" BU_SG_REL_ Kombi SG_ 1411 ZV_HD_offen 2000;
BA_REL_ "GenSigTimeoutTime" BU_SG_REL_ Kombi SG_ 1411 ZV_HS_offen 2000;
BA_REL_ "GenSigTimeoutTime" BU_SG_REL_ Kombi SG_ 1411 ZV_SafeFunktion_aktiv 2000;
BA_REL_ "GenSigTimeoutTime" BU_SG_REL_ Kombi SG_ 1411 FBS_Warn_Schluessel_Batt 2000;
BA_REL_ "GenSigTimeoutTime" BU_SG_REL_ Kombi SG_ 1411 ZV_Tankklappe_offen 2000;
VAL_ 997 FT_Tuer_Status 0 "Init" 1 "Tuer_geschlossen" 2 "Tuer_offen" 3 "Fehler" ;
VAL_ 997 FT_Tuer_Status_QBit 0 "Status_Tuerkontakt_sicher" 1 "Status_Tuerkontakt_unsicher" ;
VAL_ 997 FT_Lock_Taster_02 0 "nicht_betaetigt" 1 "betaetigt" ;
VAL_ 997 FT_Schluesselschalter_zu_02 0 "nicht_betaetigt" 1 "betaetigt" ;
VAL_ 997 FT_BFS_Tuer_Status 0 "Init" 1 "Tuer_geschlossen" 2 "Tuer_offen" 3 "Fehler" ;
VAL_ 997 FT_HBFS_Tuer_Status 0 "Init" 1 "Tuer_geschlossen" 2 "Tuer_offen" 3 "Fehler" ;
VAL_ 997 FT_HFS_Tuer_Status 0 "Init" 1 "Tuer_geschlossen" 2 "Tuer_offen" 3 "Fehler" ;
VAL_ 997 FT_Tueroeffnen_Warnung 0 "Tuerwarnung_nicht_aktiv" 1 "Tuerwarnung_aktiv" ;
VAL_ 997 FT_SP_Heizung_ein 0 "Aus" 1 "Ein" ;
VAL_ 997 FT_Kisi_Taster_li_02 0 "nicht_betaetigt" 1 "betaetigt" ;
VAL_ 997 FT_Kisi_Taster_re_02 0 "nicht_betaetigt" 1 "betaetigt" ;
VAL_ 997 FT_TD_Taste_Status 0 "kein_Fehler" 1 "Kurzschluss_nach_Minus" 2 "Kurzschluss_nach_Plus" 3 "Leitungsunterbrechung" ;
VAL_ 997 FT_TCR_Mode_aktiv 0 "TCR_Mode_deaktiv" 1 "TCR_Mode_aktiv" ;
VAL_ 997 TBF_FS_Touch_Event 0 "nicht_betaetigt" 1 "Tippen" 2 "Wischen" 3 "Geste" 4 "Doppeltippen" 5 "Longpress_1" 6 "Longpress_2" 7 "reserviert" 8 "reserviert" 9 "reserviert" 10 "reserviert" 11 "reserviert" 12 "reserviert" 13 "reserviert" 14 "reserviert" 15 "reserviert" ;
VAL_ 997 FT_KiSi_Status_Soll_HBFS 0 "inaktiv" 1 "aktiv" ;
VAL_ 997 FT_KiSi_Status_Soll_HFS 0 "inaktiv" 1 "aktiv" ;
VAL_ 997 FS_Push_Tuergriff 0 "nicht_erkannt" 1 "erkannt" ;
VAL_ 997 TSG_FS_Spiegel_angeklappt 0 "Spiegel_ausgeklappt" 1 "Spiegel_eingeklappt" ;
VAL_ 997 FT_Cargolock_bet 0 "nicht_betaetigt" 1 "betaetigt" ;
VAL_ 997 FT_kisi_asynchron 0 "nicht_aktiv" 1 "aktiv" ;
VAL_ 997 eTAB_FS_Bowdenzug_Auswerfen 0 "nicht_auswerfen" 1 "auswerfen" ;
VAL_ 997 FS_Status_eTAG_ext 0 "Griff_eingefahren" 1 "Griff_ausgefahren" 2 "Griff_verfaehrt" 3 "init" 4 "Fehler" ;
VAL_ 997 FT_ASW_Warnton 0 "kein_warnton" 1 "warnton_links" 2 "warnton_rechts" 3 "Fehler" ;
VAL_ 997 SSA_FT_ASW_Status 0 "Init" 1 "InfoStufe_aktiv" 2 "Warnstufe_aktiv" ;
VAL_ 975 HBFS_Tuer_geoeffnet 0 "geschlossen" 1 "offen" ;
VAL_ 975 HBFS_verriegelt 0 "nicht_verriegelt" 1 "verriegelt" ;
VAL_ 975 HBFS_gesafet 0 "nicht_gesafet" 1 "gesafet" ;
VAL_ 975 HBFS_Heckrollotaster_betaetigt 0 "keine_Verfahranweisung_in_Richtung_Hoch" 1 "In_Richtung_Hoch_Verfahren" ;
VAL_ 975 HBFS_Tuerschloss_defekt 0 "Tuerschloss_funktionsfaehig" 1 "Tuerschloss_defekt" ;
VAL_ 975 HBFS_Unlock_Taster 0 "nicht_betaetigt" 1 "betaetigt" ;
VAL_ 975 HBFS_Lock_Taster 0 "nicht_betaetigt" 1 "betaetigt" ;
VAL_ 975 HBFS_Sperrklinke 0 "Schloss_in_Vorraste_und_Hauptraste" 1 "Tuer_auf_oder_Tuer_Position_zwischen_Vor_und_Hauptraste" ;
VAL_ 975 HBFS_TAG_betaetigt 0 "nicht_betaetigt" 1 "betaetigt" ;
VAL_ 975 HBFS_TIG_betaetigt 0 "nicht_betaetigt" 1 "betaetigt" ;
VAL_ 975 HBFS_FH_S_HFS_AutoHoch 0 "keine_Bedienung" 1 "Automatiklauf_Angefordert" ;
VAL_ 975 HBFS_FH_S_HFS_AutoTief 0 "keine_Bedienung" 1 "Automatiklauf_Angefordert" ;
VAL_ 975 HBFS_FH_S_HFS_ManHoch 0 "keine_Bedienung" 1 "Manueller_Lauf_Angefordert" ;
VAL_ 975 HBFS_FH_S_HFS_ManTief 0 "keine_Bedienung" 1 "Manueller_Lauf_Angefordert" ;
VAL_ 975 HBFS_Tuer_Status 0 "Init" 1 "Tuer_geschlossen" 2 "Tuer_offen" 3 "Fehler" ;
VAL_ 975 HBFS_SAD_Schalter 0 "nicht_betaetigt" 5 "AUF_manuell" 6 "AUF_automatik" 7 "ZU_manuell" 8 "ZU_automatik" 13 "nicht_verfuegbar" 14 "Init" 15 "Fehler" ;
VAL_ 975 HBFS_FH_S_ManHoch 0 "nicht_betaetigt" 1 "betaetigt" ;
VAL_ 975 HBFS_FH_S_AutoHoch 0 "nicht_betaetigt" 1 "betaetigt" ;
VAL_ 975 HBFS_FH_S_ManTief 0 "nicht_betaetigt" 1 "betaetigt" ;
VAL_ 975 HBFS_FH_S_AutoTief 0 "nicht_betaetigt" 1 "betaetigt" ;
VAL_ 975 HBFS_FH_Bew_hoch 0 "inaktiv" 1 "aktiv" ;
VAL_ 975 HBFS_FH_Bew_tief 0 "inaktiv" 1 "aktiv" ;
VAL_ 975 HBFS_FH_Fang 0 "ausserhalb_Fangbereich" 1 "innerhalb_Fangbereich" ;
VAL_ 975 HBFS_FH_Block 0 "inaktiv" 1 "aktiv" ;
VAL_ 975 HBFS_FH_Thermo 0 "inaktiv" 1 "aktiv" ;
VAL_ 975 HBFS_UEKB_aktiviert 0 "inaktiv" 1 "aktiv" ;
VAL_ 975 HBFS_Tueroeffnen_Warnung 0 "Tuerwarnung_nicht_aktiv" 1 "Tuerwarnung_aktiv" ;
VAL_ 975 HBFS_FH_normiert 0 "inaktiv" 1 "aktiv" ;
VAL_ 975 ASW_Warnung_aktiv_HBFS 0 "nicht_angefordert" 1 "angefordert" ;
VAL_ 975 HBFS_Zuziehhilfe_aktiv 0 "Init" 1 "Zuziehhilfe_aktiv" ;
VAL_ 975 HBFS_Seitenrollo_hoch 1 "Seitenrollo_in_Bewegung_hoch" ;
VAL_ 975 HBFS_Seitenrollo_tief 0 "Init" 1 "Seitenrollo_in_Bewegung_tief" ;
VAL_ 975 HBFS_Status_KiSi 0 "inaktiv" 1 "aktiv" ;
VAL_ 975 SSR_HBFS_Pos_Unten 0 "SSR_Oben" 1 "SSR_Unten" ;
VAL_ 975 HBFS_Oben_Block_erw 0 "Fensterheber_nicht_in_Blockerwar" 1 "Fensterheber_in_Blockerwartung_o" ;
VAL_ 975 HBFS_Unten_Block_erw 0 "Fensterheber_nicht_in_Blockerwar" 1 "Fensterheber_in_Blockerwartung_u" ;
VAL_ 975 MTHBFS_M_Taste 0 "nicht_betaetigt" 1 "betaetigt" ;
VAL_ 975 MTHBFS_Pos1 0 "nicht_betaetigt" 1 "betaetigt" ;
VAL_ 975 MTHBFS_Pos2 0 "nicht_betaetigt" 1 "betaetigt" ;
VAL_ 975 MTHBFS_Pos3 0 "nicht_betaetigt" 1 "betaetigt" ;
VAL_ 975 HBFS_MRollo_Schalter 0 "nicht_betaetigt" 1 "ZU_manuell" 2 "ZU_automatik" 3 "AUF_manuell" 4 "AUF_automatik" 5 "nicht_verfuegbar" 6 "Init" 7 "Fehler" ;
VAL_ 975 HBFS_Lock_Taster_inv 0 "Lock Taster betätgit" 1 "Lock Taster nicht betätigt" ;
VAL_ 975 HBFS_Status_KiSi_inv 0 "aktiv" 1 "inaktiv" ;
VAL_ 975 HBFS_Status_eTAG 0 "Init" 1 "Griff_ausgefahren" 2 "Griff_eingefahren" 3 "Fehler" ;
VAL_ 975 HBFS_Tuer_Status_QBit 0 "Status_Tuerkontakt_sicher" 1 "Status_Tuerkontakt_unsicher" ;
VAL_ 975 HBFS_TIG_betaetigt_schliessen 0 "nicht_betaetigt" 1 "betaetigt" ;
VAL_ 975 HBFS_TIG_betaetigt_oeffnen 0 "nicht_betaetigt" 1 "betaetigt" ;
VAL_ 975 HBFS_Vorraste_betaetigt 0 "nicht_in_Vorraste" 1 "in_Vorraste" ;
VAL_ 975 HBFS_SK_betaetigt 0 "ausgehoben" 1 "eingefallen" ;
VAL_ 974 HFS_Tuer_geoeffnet 0 "geschlossen" 1 "offen" ;
VAL_ 974 HFS_verriegelt 0 "nicht_verriegelt" 1 "verriegelt" ;
VAL_ 974 HFS_gesafet 0 "nicht_gesafet" 1 "gesafet" ;
VAL_ 974 HFS_Heckrollotaster_betaetigt 0 "keine_Verfahranweisung_in_Richtung_Hoch" 1 "In_Richtung_Hoch_Verfahren" ;
VAL_ 974 HFS_Tuerschloss_defekt 0 "Tuerschloss_funktionsfaehig" 1 "Tuerschloss_defekt" ;
VAL_ 974 HFS_Unlock_Taster 0 "nicht_betaetigt" 1 "betaetigt" ;
VAL_ 974 HFS_Lock_Taster 0 "nicht_betaetigt" 1 "betaetigt" ;
VAL_ 974 HFS_Sperrklinke 0 "Schloss_in_Vorraste_und_Hauptraste" 1 "Tuer_auf_oder_Tuer_Position_zwischen_Vor_und_Hauptraste" ;
VAL_ 974 HFS_TAG_betaetigt 0 "nicht_betaetigt" 1 "betaetigt" ;
VAL_ 974 HFS_TIG_betaetigt 0 "nicht_betaetigt" 1 "betaetigt" ;
VAL_ 974 HFS_FH_S_HBFS_AutoHoch 0 "keine_Bedienung" 1 "Automatiklauf_Angefordert" ;
VAL_ 974 HFS_FH_S_HBFS_AutoTief 0 "keine_Bedienung" 1 "Automatiklauf_Angefordert" ;
VAL_ 974 HFS_FH_S_HBFS_ManHoch 0 "keine_Bedienung" 1 "Manueller_Lauf_Angefordert" ;
VAL_ 974 HFS_FH_S_HBFS_ManTief 0 "keine_Bedienung" 1 "Manueller_Lauf_Angefordert" ;
VAL_ 974 HFS_Tuer_Status 0 "Init" 1 "Tuer_geschlossen" 2 "Tuer_offen" 3 "Fehler" ;
VAL_ 974 HFS_SAD_Schalter 0 "nicht_betaetigt" 5 "AUF_manuell" 6 "AUF_automatik" 7 "ZU_manuell" 8 "ZU_automatik" 13 "nicht_verfuegbar" 14 "Init" 15 "Fehler" ;
VAL_ 974 HFS_FH_S_ManHoch 0 "nicht_betaetigt" 1 "betaetigt" ;
VAL_ 974 HFS_FH_S_AutoHoch 0 "nicht_betaetigt" 1 "betaetigt" ;
VAL_ 974 HFS_FH_S_ManTief 0 "nicht_betaetigt" 1 "betaetigt" ;
VAL_ 974 HFS_FH_S_AutoTief 0 "nicht_betaetigt" 1 "betaetigt" ;
VAL_ 974 HFS_FH_Bew_hoch 0 "inaktiv" 1 "aktiv" ;
VAL_ 974 HFS_FH_Bew_tief 0 "inaktiv" 1 "aktiv" ;
VAL_ 974 HFS_FH_Fang 0 "ausserhalb_Fangbereich" 1 "innerhalb_Fangbereich" ;
VAL_ 974 HFS_FH_Block 0 "inaktiv" 1 "aktiv" ;
VAL_ 974 HFS_FH_Thermo 0 "inaktiv" 1 "aktiv" ;
VAL_ 974 HFS_UEKB_aktiviert 0 "inaktiv" 1 "aktiv" ;
VAL_ 974 HFS_Tueroeffnen_Warnung 0 "Tuerwarnung_nicht_aktiv" 1 "Tuerwarnung_aktiv" ;
VAL_ 974 HFS_FH_normiert 0 "inaktiv" 1 "aktiv" ;
VAL_ 974 ASW_Warnung_aktiv_HFS 0 "nicht_angefordert" 1 "angefordert" ;
VAL_ 974 HFS_Zuziehhilfe_aktiv 0 "Init" 1 "Zuziehhilfe_aktiv" ;
VAL_ 974 HFS_Seitenrollo_hoch 0 "Init" 1 "Seitenrollo_in_Bewegung_hoch" ;
VAL_ 974 HFS_Seitenrollo_tief 0 "Init" 1 "Seitenrollo_in_Bewegung_tief" ;
VAL_ 974 HFS_Status_KiSi 0 "inaktiv" 1 "aktiv" ;
VAL_ 974 SSR_HFS_Pos_Unten 0 "SSR_Oben" 1 "SSR_Unten" ;
VAL_ 974 HFS_Oben_Block_erw 0 "Fensterheber_nicht_in_Blockerwar" 1 "Fensterheber_in_Blockerwartung_o" ;
VAL_ 974 HFS_Unten_Block_erw 0 "Fensterheber_nicht_in_Blockerwar" 1 "Fensterheber_in_Blockerwartung_u" ;
VAL_ 974 MTHFS_M_Taste 0 "nicht_betaetigt" 1 "betaetigt" ;
VAL_ 974 MTHFS_Pos1 0 "nicht_betaetigt" 1 "betaetigt" ;
VAL_ 974 MTHFS_Pos2 0 "nicht_betaetigt" 1 "betaetigt" ;
VAL_ 974 MTHFS_Pos3 0 "nicht_betaetigt" 1 "betaetigt" ;
VAL_ 974 HFS_MRollo_Schalter 0 "nicht_betaetigt" 1 "ZU_manuell" 2 "ZU_automatik" 3 "AUF_manuell" 4 "AUF_automatik" 5 "nicht_verfuegbar" 6 "Init" 7 "Fehler" ;
VAL_ 974 HFS_Lock_Taster_inv 0 "Lock Taster betätgit" 1 "Lock Taster nicht betätigt" ;
VAL_ 974 HFS_Status_eTAG 0 "Init" 1 "Griff_ausgefahren" 2 "Griff_eingefahren" 3 "Fehler" ;
VAL_ 974 HFS_Tuer_Status_QBit 0 "Status_Tuerkontakt_sicher" 1 "Status_Tuerkontakt_unsicher" ;
VAL_ 974 HFS_TCR_Mode_aktiv 0 "TCR_Mode_deaktiv" 1 "TCR_Mode_aktiv" ;
VAL_ 974 HFS_TIG_betaetigt_schliessen 0 "nicht_betaetigt" 1 "betaetigt" ;
VAL_ 974 HFS_TIG_betaetigt_oeffnen 0 "nicht_betaetigt" 1 "betaetigt" ;
VAL_ 974 HFS_Vorraste_betaetigt 0 "nicht_in_Vorraste" 1 "in_Vorraste" ;
VAL_ 974 HFS_SK_betaetigt 0 "ausgehoben" 1 "eingefallen" ;
VAL_ 2589283772 TSL_Warnung 0 "keine_Anzeige" 1 "Fehler_Torquesplitter" ;
VAL_ 2589283772 TSL_Hinweis 0 "Keine_Anzeige" 1 "Hinweis_thermische_Degradierung" 2 "Hinweis_reduzierte_Performance" 3 "Hinweis_Vorhalt" ;
VAL_ 2589283772 QSP_Temperatur_Oel 127 "Fehler" ;
VAL_ 2589283772 QSP_Warnlampe 0 "Warnlampe aus" 1 "Warnlampe ein (Aufprüfen), zur Zeit nicht belegt" 2 "Warnlampe ein (Warnung)  =  Fehler" 3 "Warnlampe ein (Übertemperatur)" ;
VAL_ 2589283772 QSP_Thermische_Belastung 63 "Fehler" ;
VAL_ 2589283773 TSR_Warnung 0 "keine_Anzeige" 1 "Fehler_Torquesplitter" ;
VAL_ 2589283773 TSR_Hinweis 0 "Keine_Anzeige" 1 "Hinweis_thermische_Degradierung" 2 "Hinweis_reduzierte_Performance" 3 "Hinweis_Vorhalt" ;
VAL_ 2589283773 TSR_Temperatur_Oel 127 "Fehler" ;
VAL_ 2589283773 TSR_Warnlampe 0 "Warnlampe aus" 1 "Warnlampe ein (Aufprüfen), zur Zeit nicht belegt" 2 "Warnlampe ein (Warnung)  =  Fehler" 3 "Warnlampe ein (Übertemperatur)" ;
VAL_ 2589283773 TSR_Thermische_Belastung 63 "Fehler" ;
VAL_ 1718 UH_Typ 0 "undefiniert" 1 "Quarzuhr" 2 "DCF" 3 "GPS" ;
VAL_ 1718 UH_DLS 0 "Winterzeit" 1 "Sommerzeit" ;
VAL_ 1718 UH_Monat 0 "Init" 14 "Relatives_Datum" 15 "Fehler" ;
VAL_ 1718 UH_Tag 0 "Init" ;
VAL_ 995 VS_VD_zu_ver 1 "Zustand des Verdecks verriegelt und geschlossen" ;
VAL_ 995 VS_VD_entriegelt 0 "Init" 1 "Zustand_des_Verdeck_entriegelt" ;
VAL_ 995 VS_VD_offen_ver 0 "Init" 1 "Verdeck_verriegelt_und_offen" ;
VAL_ 995 VS_VD_Zwischenposition 0 "Init" 1 "Verdeck_in_Zwischenposition" ;
VAL_ 995 VS_VD_Bew_auf 1 "Verdeck in Bewegung auf" ;
VAL_ 995 VS_VD_Bew_zu 1 "Verdeck in Bewegung zu" ;
VAL_ 995 VS_Verdeck_Anf 0 "init_nicht_aktiv" 1 "aktiv" ;
VAL_ 995 VS_Hardtop 0 "Init" 1 "Hardtop_montiert" ;
VAL_ 995 VS_VD_Fehler 0 "Init" 1 "Fehlerzustand Verdeck" ;
VAL_ 995 VS_Lampe_Blk 0 "Kontrollleuchte_inaktiv" 1 "Kontrollleuchte_aktiv" ;
VAL_ 995 VS_HD_sperren 0 "HD Entriegelung freigegeben" 1 "HD Entriegelung gesperrt" ;
VAL_ 995 VS_HHS_enable 0 "Init" 1 "Freigabe HHS" ;
VAL_ 995 VD_SpannungsAnf 0 "keine_Anforderung" 1 "Anforderung_Stufe1" 2 "Anforderung_Stufe2" 3 "Anforderung_Stufe3" ;
VAL_ 995 VS_VDKD_auf 0 "VDKD_nicht_vollst_auf" 1 "VDKD_vollstaendig_auf" ;
VAL_ 995 VS_FS_AutoHoch 0 "Keine_Verfahranforderung" 1 "Automatischer_Hochlauf" ;
VAL_ 995 VS_FS_AutoTief 0 "Keine_Verfahranforderung" 1 "Automatischer_Tieflauf" ;
VAL_ 995 VS_FS_ManHoch 0 "Keine_Verfahranforderung" 1 "Manueller_Hochlauf" ;
VAL_ 995 VS_FS_ManTief 0 "Keine_Verfahranforderung" 1 "Manueller_Tieflauf" ;
VAL_ 995 VS_BFS_AutoHoch 0 "Keine_Verfahranforderung" 1 "Automatischer_Hochlauf" ;
VAL_ 995 VS_BFS_AutoTief 0 "Keine_Verfahranforderung" 1 "Automatischer_Tieflauf" ;
VAL_ 995 VS_BFS_ManHoch 0 "Keine_Verfahranforderung" 1 "Manueller_Hochlauf" ;
VAL_ 995 VS_BFS_ManTief 0 "Keine_Verfahranforderung" 1 "Manueller_Tieflauf" ;
VAL_ 995 VS_HFS_AutoHoch 0 "Keine_Verfahranforderung" 1 "Automatischer_Hochlauf" ;
VAL_ 995 VS_HFS_AutoTief 0 "Keine_Verfahranforderung" 1 "Automatischer_Tieflauf" ;
VAL_ 995 VS_HFS_ManHoch 0 "Keine_Verfahranforderung" 1 "Manueller_Hochlauf" ;
VAL_ 995 VS_HFS_ManTief 0 "Keine_Verfahranforderung" 1 "Manueller_Tieflauf" ;
VAL_ 995 VS_HBFS_AutoHoch 0 "Keine_Verfahranforderung" 1 "Automatischer_Hochlauf" ;
VAL_ 995 VS_HBFS_AutoTief 0 "Keine_Verfahranforderung" 1 "Automatischer_Tieflauf" ;
VAL_ 995 VS_HBFS_ManHoch 0 "Keine_Verfahranforderung" 1 "Manueller_Hochlauf" ;
VAL_ 995 VS_HBFS_ManTief 0 "Keine_Verfahranforderung" 1 "Manueller_Tieflauf" ;
VAL_ 995 VS_FH_FT_Langhub 0 "Init" ;
VAL_ 995 VS_Windschott_nicht_abgelegt 0 "inaktiv" 1 "aktiv" ;
VAL_ 995 VS_FH_BT_Langhub 0 "Init" ;
VAL_ 995 VS_FH_HFS_Langhub 0 "Init" ;
VAL_ 995 VS_Heckschloss_auf 0 "kein_Oeffnen" 1 "Heckschloss_oeffnen" ;
VAL_ 995 VS_FH_HBFS_Langhub 0 "Init" ;
VAL_ 995 VSG_Meldungen 0 "keine_Meldung" ;
VAL_ 995 VS_StartStopp_Info 0 "Stoppfreigabe" 1 "Stoppverbot" 2 "Startanforderung" 3 "Fehler" ;
VAL_ 1057 VLK_Anforderung_HMS 0 "keine_Anforderung" 1 "halten" 2 "parken" 3 "halten_Standby" 4 "anfahren" 5 "Loesen_ueber_Rampe" 6 "Parken_mit_P" 7 "HMS_uebernehmen" ;
VAL_ 1057 VLK_autom_Absch_Signalisierung 0 "Init" 1 "Automatisierte_Abschaltung" ;
VAL_ 1057 VLK_VLW_Anf 0 "Init" 1 "VLW_angefordert" 2 "degradierte_VLW_FT_Fehler" 3 "reserved" ;
VAL_ 1057 VLK_Anforderung_Rollfaehigkeit 0 "Rollfaehigkeitsmode_inaktiv_Init" 1 "Rollfaehigkeitsmodus_aktiv" ;
VAL_ 1057 VLK_Parken_beibehalten_HMS 0 "Parken_nicht_beibehalten" 1 "Parken_beibehalten" 2 "Init" 3 "Fehler" ;
VAL_ 1057 VLK_Hinweis_Rollfaehigkeit 0 "Init_keinHinweis" 1 "Hinweis_ohne_Akustik" 2 "Hinweis_mit_Akustik" 3 "reserviert" ;
VAL_ 1057 VLK_Antriebsdeaktivierung 0 "Keine_Einschraenkung" 1 "Antrieb_deaktivieren" 3 "Fehler" ;
VAL_ 1057 VLK_Anf_Antrieb 0 "Init" 1 "Freigabe" 2 "VKM_Zustand_einfrieren" 3 "Zustartverbot_fuer_Fahrer" 5 "Startanforderung" 7 "Fehler" ;
VAL_ 1057 VLK_Hinweis_Weiterfahrt 0 "inaktiv" 1 "aktiv" ;
VAL_ 1057 VLK_Hinweis_Fehler_Gurt 0 "inaktiv" 1 "aktiv" ;
VAL_ 1057 VLK_Hinweis_Fehler_Sitz 0 "inaktiv" 1 "aktiv" ;
VAL_ 1057 VLK_Hinweis_Fehler_Tuer 0 "inaktiv" 1 "aktiv" ;
VAL_ 1057 VLK_Hinweis_dgr_VLW 0 "inaktiv" 1 "aktiv" ;
VAL_ 1057 VLK_Hinweis_KA_bevorstehend 0 "inaktiv" 1 "aktiv" ;
VAL_ 2463978663 VZE_Anzeigemodus 0 "EU_RDW" 1 "USA" 2 "Canada" 3 "China" ;
VAL_ 2463978663 VZE_Hinweistext 0 "kein_Hinweistext" ;
VAL_ 2463978663 VZE_Akustik_Limitwechsel 0 "keine_akustische_Signalisierung" 1 "akustische_Signalisierung_an" ;
VAL_ 2463978663 VZE_Modus_OptischeWarnung 0 "konstant" 1 "blinkend" ;
VAL_ 2463978663 VZE_Verkehrszeichen_Einheit 0 "kmh" 1 "mph" ;
VAL_ 2463978663 VZE_Anzeigeunterdrueck_Zeichen_3 0 "anzeigerelevant" 1 "nicht_anzeigerelevant" ;
VAL_ 2463978663 VZE_Anzeigeunterdrueck_Zeichen_2 0 "anzeigerelevant" 1 "nicht_anzeigerelevant" ;
VAL_ 2463978663 VZE_Verkehrszeichen_1 0 "kein_Verkehrszeichen" ;
VAL_ 2463978663 VZE_Verkehrszeichen_2 0 "kein_Verkehrszeichen" ;
VAL_ 2463978663 VZE_Verkehrszeichen_3 0 "kein_Verkehrszeichen" ;
VAL_ 2463978663 VZE_Warnung_Verkehrszeichen_1 0 "keine_Warnung_Initialwert_Fehlerwert" 1 "Warnung" ;
VAL_ 2463978663 VZE_Warnung_Verkehrszeichen_2 0 "keine_Warnung_Initialwert_Fehlerwert" 1 "Warnung" ;
VAL_ 2463978663 VZE_Warnung_Verkehrszeichen_3 0 "keine_Warnung_Initialwert_Fehlerwert" 1 "Warnung" ;
VAL_ 2463978663 VZE_Zusatzschild_1 0 "keine_Zusatzschild_Initialwert_Fehlerwert" ;
VAL_ 2463978663 VZE_Zusatzschild_2 0 "keine_Zusatzschild_Initialwert_Fehlerwert" ;
VAL_ 2463978663 VZE_Zusatzschild_3 0 "keine_Zusatzschild_Initialwert_Fehlerwert" ;
VAL_ 2463978663 VZE_Anzeigeunterdrueck_Zeichen_1 0 "anzeigerelevant" 1 "nicht_anzeigerelevant" ;
VAL_ 2463978663 VZE_Zeichen_01_KameraWied 0 "inaktiv" 1 "aktiv" ;
VAL_ 2463978663 VZE_Zeichen_02_KameraWied 0 "inaktiv" 1 "aktiv" ;
VAL_ 2463978663 VZE_Zeichen_03_KameraWied 0 "inaktiv" 1 "aktiv" ;
VAL_ 2463978663 VZE_Zeichen_01_Kamera 0 "nicht_erkannt" 1 "erkannt" ;
VAL_ 2463978663 VZE_Zeichen_01_Karte 0 "inaktiv" 1 "aktiv" ;
VAL_ 2463978663 VZE_Zeichen_01_Gesetz 0 "nicht_erkannt" 1 "erkannt" ;
VAL_ 2463978663 VZE_Zeichen_02_Kamera 0 "nicht_erkannt" 1 "erkannt" ;
VAL_ 2463978663 VZE_Zeichen_02_Karte 0 "inaktiv" 1 "aktiv" ;
VAL_ 2463978663 VZE_Zeichen_02_Gesetz 0 "nicht_erkannt" 1 "erkannt" ;
VAL_ 2463978663 VZE_Zeichen_03_Kamera 0 "nicht_erkannt" 1 "erkannt" ;
VAL_ 2463978663 VZE_Zeichen_03_Karte 0 "inaktiv" 1 "aktiv" ;
VAL_ 2463978663 VZE_Zeichen_03_Gesetz 0 "nicht_erkannt" 1 "erkannt" ;
VAL_ 2463978663 VZE_Gong 0 "Gong_deaktiv" 1 "Gong_aktiv" ;
VAL_ 2463978663 VZE_Akustik_Limitwechsel_Status 0 "keine_akustische_Signalisierung" 1 "akustische_Signalisierung_an" ;
VAL_ 2463978663 VZE_SLWF_Status 0 "Init" 1 "aktiv" 2 "deaktiv" ;
VAL_ 2463978663 VZE_Anzeigeunterdrueck_Zeichen_5 0 "anzeigerelevant" 1 "nicht_anzeigerelevant" ;
VAL_ 2463978663 VZE_Zeichen_05_KameraWied 0 "inaktiv" 1 "aktiv" ;
VAL_ 2463978663 VZE_Zeichen_05_Kamera 0 "nicht_erkannt" 1 "erkannt" ;
VAL_ 2463978663 VZE_Verkehrszeichen_4 0 "kein_Verkehrszeichen" ;
VAL_ 2463978663 VZE_Verkehrszeichen_5 0 "kein_Verkehrszeichen" ;
VAL_ 2463978663 VZE_Anhaenger_Vmax 14 "Init" 15 "Fehler" ;
VAL_ 2463978663 VZE_Zeichen_04_Gesetz 0 "nicht_erkannt" 1 "erkannt" ;
VAL_ 2463978663 VZE_Zeichen_04_Kamera 0 "nicht_erkannt" 1 "erkannt" ;
VAL_ 2463978663 VZE_Zeichen_04_KameraWied 0 "inaktiv" 1 "aktiv" ;
VAL_ 2463978663 VZE_Zeichen_04_Karte 0 "inaktiv" 1 "aktiv" ;
VAL_ 2463978663 VZE_Warnung_Verkehrszeichen_4 0 "keine_Warnung_Initialwert_Fehlerwert" 1 "Warnung" ;
VAL_ 2463978663 VZE_Warnung_Verkehrszeichen_5 0 "keine_Warnung_Initialwert_Fehlerwert" 1 "Warnung" ;
VAL_ 2463978663 VZE_Zeichen_05_Gesetz 0 "nicht_erkannt" 1 "erkannt" ;
VAL_ 2463978663 VZE_Zusatzschild_4 0 "keine_Zusatzschild_Initialwert_Fehlerwert" ;
VAL_ 2463978663 VZE_Zusatzschild_5 0 "keine_Zusatzschild_Initialwert_Fehlerwert" ;
VAL_ 2463978663 VZE_Baustelle 0 "Keine_Baustelle" 1 "Baustelle_erkannt" ;
VAL_ 2463978663 VZE_Zeichen_05_Karte 0 "inaktiv" 1 "aktiv" ;
VAL_ 2463978663 VZE_Zeichen_05_Entfernung 0 "Init" ;
VAL_ 2463978663 VZE_Zeichen_05_Entfernung_StdA 0 "Init" ;
VAL_ 2463978663 VZE_Anzeigeunterdrueck_Zeichen_4 0 "anzeigerelevant" 1 "nicht_anzeigerelevant" ;
VAL_ 2463978663 VZE_Verkehrszeichen_6 0 "kein_Verkehrszeichen" ;
VAL_ 2463978663 VZE_Zusatzschild_6 0 "keine_Zusatzschild_Initialwert_Fehlerwert" ;
VAL_ 2463978663 VZE_Zeichen_06_Entfernung 0 "Init" ;
VAL_ 2463978663 VZE_Zeichen_06_Entfernung_StdA 0 "Init" ;
VAL_ 2463978663 VZE_Umweltinfo_Naesse 0 "inaktiv" 1 "aktiv" ;
VAL_ 2463978663 VZE_Umweltinfo_Nebel 0 "inaktiv" 1 "aktiv" ;
VAL_ 2463978663 VZE_Umweltinfo_Anhaengerbetrieb 0 "inaktiv" 1 "aktiv" ;
VAL_ 2463978663 VZE_Erweiterte_Information 0 "keine_Information" ;
VAL_ 2463978663 VZE_Tempowarnung_Status 0 "inaktiv" 1 "aktiv" ;
VAL_ 2463978663 VZE_Tempowarnung_Einheit 0 "kmh" 1 "mph" ;
VAL_ 2463978663 VZE_Tempowarnung_Offset 0 "Init" ;
VAL_ 2463978663 VZE_FoD_Status 0 "Init" 1 "Funktion_inaktiv" 2 "Funktion_aktiv" ;
VAL_ 2463978663 VZE_Anzeige_ZS_1 0 "Init" ;
VAL_ 2463978663 VZE_Anzeige_ZS_2 0 "Init" ;
VAL_ 2463978663 VZE_Anzeige_ZS_3 0 "Init" ;
VAL_ 2463978663 VZE_Hinweistext_03 0 "kein_Hinweistext" ;
VAL_ 2463978663 VZE_Land 0 "Init" ;
VAL_ 2463978663 VZE_Warnung_VZ_1 0 "keine_Warnung" 1 "Warnung" ;
VAL_ 2463978663 VZE_Warnung_VZ_2 0 "keine_Warnung" 1 "Warnung" ;
VAL_ 2463978663 VZE_Warnung_VZ_3 0 "keine_Warnung" 1 "Warnung" ;
VAL_ 2463978663 VZE_Anzeige_VZ_1 0 "kein_Verkehrszeichen" ;
VAL_ 2463978663 VZE_Anzeige_VZ_2 0 "kein_Verkehrszeichen" ;
VAL_ 2463978663 VZE_Anzeige_VZ_3 0 "kein_Verkehrszeichen" ;
VAL_ 2589283476 WH_Warnung_02 0 "Keine_Anzeige" 1 "Waehlhebel_defekt_Weiterfahrt_moeglich" 2 "Waehlhebel_in_Automatgasse_zurueckstellen" 3 "P_Taste_defekt" 4 "Zeitueberschr_P_wird_eingelegt" 5 "Wegrollgefahr__P_nicht_moeglich" ;
VAL_ 2589283476 WH_Warnung_03 0 "keine_Anzeige" 1 "Fahrstufe_D_mit_rechtem_Paddle" 2 "Fahrstufe_D_ueber_MD_Button" ;
VAL_ 2589283476 WH_Verbau_Entsperrtaste 0 "keine_Entsperrtaste_verbaut" 1 "Entsperrtaste_verbaut" ;
VAL_ 2589283476 WH_Schaltschema_Orientierung 0 "R_N_D" 1 "D_N_R" ;
VAL_ 2589283476 WH_FSA_HMI_Meldungen_01 0 "keine_Anzeige" 1 "Aufwaermphase_akt__nur_P_oder_N" 2 "Parksperre_defekt__Weiterfahrt" 3 "Parksperre_defekt__Liegenbleiber" ;
VAL_ 916 WBA_Fahrstufe_02 0 "Zwischenstellung_keine_Position" 1 "Position_P" 2 "Position_R" 3 "Position_N" 4 "Position_D" 5 "Position_S" 6 "Position_M_Tippfunktion" 7 "Kurzzeit_M" 8 "Position_E" 9 "Position_MS" 10 "Position_S_Plus" 11 "Position_MS_Plus" 12 "Position_Offroad" 13 "Position_B" 14 "Position_M_Plus" ;
VAL_ 916 WBA_ZielFahrstufe 0 "keine_Gangempfehlung_kein_Gang_eingelegt" 1 "Pfeil_nach_S" 2 "Pfeil_nach_D" 3 "Pfeil_nach_M" 4 "Pfeil_nach_E" ;
VAL_ 916 WBA_GE_Warnung_02 0 "keine_Anzeige" 1 "Fehlereskalationsstufe_I" 2 "Fehlereskalationsstufe_II" 3 "Weiterfahrt_nur_eingeschraenkt_moeglich__Kein_R_Gang" 4 "Getriebefehler_Weiterfahrt_nur_in_D_moeglich__P_bei_Motor_aus" 5 "Wegrollgefahr__P_nicht_moeglich" 6 "Paddlenotbetrieb_Schema+Warnung" 7 "Paddlenotbetrieb_Schema" 8 "Geschwindigkeitsbegrenzung_Notlauf" 9 "Fehlereskalationsst_o_Einschr" 10 "Fehlereskalationsstufe_v_Limit" 11 "Parksperre_Infostufe" 12 "Parksperre_Warnstufe_I" 13 "Parksperre_Warnstufe_II" ;
VAL_ 916 WBA_eing_Gang_02 0 "keine_Ganganzeige" 1 "Gang_1" 2 "Gang_2" 3 "Gang_3" 4 "Gang_4" 5 "Gang_5" 6 "Gang_6" 7 "Gang_7" 8 "Gang_8" 9 "Gang_9" 10 "Funktion_Ganganzeigeunterdrueckung" 11 "Gang_10" ;
VAL_ 916 WBA_GE_Texte 0 "keine_Anzeige" 1 "zum_Einlegen_einer_Fahrstufe_Fussbremse_betaetigen__ShiftLock_Information" 2 "zum_Einlegen_von_R_N_D_Fussbremse_betaetigen_und_Motor_starten" 3 "Wegrollgefahr_bitte_P_einlegen" 4 "Achtung_Zeitueberschreitung_P_wird_eingelegt" 5 "Wiederanmeldeprozedur_Bremse_betaetigen" 6 "P_nur_im_Stillstand_moeglich" 7 "Rennstart_aktiv" ;
VAL_ 916 WBA_Segeln_aktiv 0 "inaktiv" 1 "aktiv" ;
VAL_ 916 WBA_Schaltschema_02 0 "kein_Schaltschema" 1 "R_N_DS" 2 "R_N_ES" 3 "R_N_DB" 4 "R_N_D" 5 "R_N_SSplus" ;
VAL_ 916 WBA_Schaltschema_FS_inaktiv 0 "alle_Fahrstufen_aktiv" 1 "Fahrstufe_Rueckwaerts_inaktiv" 2 "nur_P_und_N_aktiv" 3 "alle_Fahrstufen_inaktiv" ;
VAL_ 916 WBA_GE_Zusatzwarnungen 0 "keine_Anzeige" 1 "Getriebeueberhitzung_Warnstufe_I" 2 "Getriebeueberhitzung_Warnstufe_II" 3 "Getriebefehler_Bitte_anhalten_und_P_einlegen" ;
VAL_ 916 GE_Sollgang 0 "keine_Empfehlung" 1 "Gang_1" 2 "Gang_2" 3 "Gang_3" 4 "Gang_4" 5 "Gang_5" 6 "Gang_6" 7 "Gang_7" 8 "Gang_8" 9 "Gang_9" 11 "Gang_10" ;
VAL_ 916 GE_Tipschaltempf_verfuegbar 0 "nicht_verfuegbar" 1 "verfuegbar" ;
VAL_ 916 WBA_GE_Texte_02 0 "Keine_Anzeige" 1 "Fahrtrichtungswechsel_nur_nach_Stillstandt" 2 "Ladestecker_gesteckt" 3 "zusaetzlicher_Service_erforderlich" 4 "eLaunch_Aktiv" 5 "eLaunch_nicht_moeglich" 6 "WH_S_nicht_moeglich_Offroad" 7 "WH_S_nicht_moeglich_RangeMode" ;
VAL_ 916 WBA_Schaltschema_Tippgasse 0 "keine_Tippgasse_vorhanden" 1 "Tippgasse_vorhanden" ;
VAL_ 916 WBA_Schaltschema_Fahreraktion 0 "keine_Fahreraktion" 1 "Fahreraktion" ;
VAL_ 916 WBA_Schaltschema_FS_vorwaerts 0 "FS1_aktiv__FS2_moeglich" 1 "FS2_aktiv__FS1_moeglich" 2 "FS1_aktiv__FS2_nicht_moeglich" 3 "FS2_aktiv__FS1_nicht_moeglich" ;
VAL_ 916 WBA_Shiftlock_Lampe 0 "Shiftlock_Lampe_AUS" 1 "Shiftlock_Lampe_EIN" ;
VAL_ 916 WBA_Anforderung_Akustik 0 "Akustik_aus" 1 "Akustik_ein" ;
VAL_ 916 WBA_Blinken 0 "kein_WBA_Blinken" 1 "WBA_Blinken" ;
VAL_ 916 GE_Wiederstart_Anz_Std 0 "keine_Anzeige" 1 "Standard_Wiederstartgrund" ;
VAL_ 916 GE_Stoppverbot_Anz_01 0 "keine_Anzeige" 1 "Temperaturbedingung" ;
VAL_ 916 GE_Stoppverbot_Anz_02 0 "keine_Anzeige" 1 "Drucksensorausfall" ;
VAL_ 916 GE_Stoppverbot_Anz_03 0 "keine_Anzeige" 1 "Grundeinstellung" ;
VAL_ 916 GE_Stoppverbot_Anz_04 0 "keine_Anzeige" 1 "Demontagestellung" ;
VAL_ 916 GE_Stoppverbot_Anz_05 0 "keine_Anzeige" 1 "Eingeschraenkte_Fahrfunktion_Notlauf_Liegenbleiber" ;
VAL_ 916 GE_Stoppverbot_Anz_06 0 "keine_Anzeige" 1 "Stoppverbot_ueber_Applikation" ;
VAL_ 916 GE_Stoppverbot_Anz_07 0 "keine_Anzeige" 1 "Schaltung_aktiv" ;
VAL_ 916 GE_Stoppverbot_Anz_Std 0 "keine_Anzeige" 1 "Standard_Stoppvetogrund" ;
VAL_ 1361 WFS_Schluessel_Fahrberecht 0 "kein authorisierter Schluessel erkannt" 1 "aktive_Funkschluessel_Nr_01" 2 "aktive_Funkschluessel_Nr_02" 3 "aktive_Funkschluessel_Nr_03" 4 "aktive_Funkschluessel_Nr_04" 5 "aktive_Funkschluessel_Nr_05" 6 "aktive_Funkschluessel_Nr_06" 7 "aktive_Funkschluessel_Nr_07" 8 "aktive_Funkschluessel_Nr_08" 9 "ungueltig_09" 10 "ungueltig_10" 11 "ungueltig_11" 12 "ungueltig_12" 13 "ungueltig_13" 14 "ungueltig_14" 15 "digitaler_Schluessel_aktiv" ;
VAL_ 1361 WFS_Verbauinfo_ELV 0 "ELV_nicht_verbaut" 1 "ELV_verbaut" ;
VAL_ 1361 WFS_ID_Geb_autorisiert 0 "Schluessel_nicht_authorisiert" 1 "Schluessel_authorisiert" ;
VAL_ 1361 WFS_ID_Geb_autorisiert_in_Kl15 0 "nicht_authorisiert_in_Kl15" 1 "authorisiert_in_Kl15" ;
VAL_ 1361 WFS_ID_Geb_steckt 0 "kein_Schluessel_im_Zuendschloss" 1 " Schluessel steckt im Zuendschloss" ;
VAL_ 1361 WFS_Safe 0 "Init" 1 "WFS nicht deaktiviert" ;
VAL_ 1361 WFS_LZ 0 "nicht def." 1 "LZ 1" 2 "LZ 2" 3 "LZ 3" ;
VAL_ 1361 WFS_ELV_authorisiert 0 "ELV_nicht_authorisiert" 1 "ELV_authorisiert" ;
VAL_ 1361 WFS_LF_Aktiv 0 "Funktempfang_nicht_aktiv" 1 "LF_Funkempfang_aktiv" ;
VAL_ 1361 WFS_Betrieb_Lesespule 0 "keine_Schluesselkomm_Lesespule" 1 "Schluesselkomm_Lesespule" ;
VAL_ 1361 WFS_Klemmenfreigabe 0 "keine_Freigabe" 1 "Freigabe" ;
VAL_ 1361 WFS_Fahrerhinweise 0 "Keine_Anzeigeanforderung" 1 "Schuessel_Auth_niO" 2 "Notlauf_aktiv" 3 "Schluessel_Kessy_nicht_gefunden" ;
VAL_ 1361 WFS_Parken_Status 0 "Limitierung_inaktiv" 1 "Limitierung_aktiv" 2 "Abbruch" ;
VAL_ 830 WFS_Transp_Mod_Unterbrechung_02 0 "kein_Uebergang" 1 "Uebergang_erkannt" ;
VAL_ 830 WFS_Verbau_Transp_Ant_02 0 "inaktiv" 1 "aktiv" ;
VAL_ 830 WFS_Diag_LF_Aktiv_02 0 "inaktiv" 1 "aktiv" ;
VAL_ 830 WFS_LF_aktiv_02 0 "Feld_inaktiv" 1 "Feld_aktiv" ;
VAL_ 1702 Wischer_vorne_aktiv 0 "Init" 1 "Wischer_vorne_laeuft" ;
VAL_ 1702 Waschen_vorne_aktiv 0 "inaktiv" 1 "Waschen_aktiv" ;
VAL_ 1702 Wischer_vorne_Normal 1 "Wischer Front normal aktiv" ;
VAL_ 1702 Wischer_vorne_Schnell 1 "Wischer vorne schnell aktiv" ;
VAL_ 1702 Wischer_vorne_Parklage 0 "Wischer_Front_nicht_in_Parklage" 1 "Wischer_Front_in_Parklage__Initialzustand" ;
VAL_ 1702 WWSs_01_alt 0 "aktuell" 1 "veraltet" ;
VAL_ 1702 Wischer_vorne_defekt 0 "Init" 1 "Wischer vorne defekt" ;
VAL_ 1702 Wischer_vorne_blockiert 1 "Wischer vorne blockiert" ;
VAL_ 1702 Wischer1_Wischgeschwindigkeit 0 "0 U/min" 62 "Init" 63 "Fehler" ;
VAL_ 1702 BCM1_SRA_aktiv 0 "nicht aktiv" 1 "aktiv" ;
VAL_ 1702 Heckwischer_Anforderung 0 "Aus" 1 "Ein" ;
VAL_ 1702 Wischer_Anzeigetext 0 "keine_Anzeige" 1 "Hinweis_Service_Position" 2 "void" 3 "void" ;
VAL_ 1702 Wischer_WH_Typ 0 "Lenkstockschalter_0_Int_Stufen" 1 "Lenkstockschalter_2_Int_Stufen" 2 "Lenkstockschalter_4_Int_Stufen" ;
VAL_ 1702 Wischer_WH_PopUp_Anf 0 "keine_Anzeige" 1 "Intervallstufe_1_aktiv" 2 "Intervallstufe_2_aktiv" 3 "Intervallstufe_3_aktiv" 4 "Intervallstufe_4_aktiv" 5 "Regensensorstufe_1_aktiv" 6 "Regensensorstufe_2_aktiv" 7 "Regensensorstufe_3_aktiv" 8 "Regensensorstufe_4_aktiv" 9 "Wischerstufe_1_aktiv" 10 "Wischerstufe_2_aktiv" 11 "Tippwischen_aktiv" 12 "Heckwischen_aktiv" ;
VAL_ 1602 WIV_Verschleissindex 65535 "Fehler" ;
VAL_ 1602 WIV_Russindex 65535 "Fehler" ;
VAL_ 1140 ZR_State_DU_1 0 "Disp_Off" 1 "Disp_On" 2 "LowPow" ;
VAL_ 1140 ZR_State_DU_2 0 "Disp_Off" 1 "Disp_On" 2 "LowPow" ;
VAL_ 1140 ZR_State_DU_3 0 "Disp_Off" 1 "Disp_On" 2 "LowPow" ;
VAL_ 1140 ZR_WecktGesp 0 "entsperrt" 1 "gesperrt" ;
VAL_ 1140 MMI_State 0 "MMI_OFF" 1 "MMI_IOC" 2 "MMI_STDBY" 3 "MMI_ON" 4 "MMI_STDBY_PWR_SAVE" 5 "MMI_STDBY_RESTR" 6 "MMI_ON_DIAG" 7 "MMI_ON_TEL" 8 "MMI_ON_SWDL" 9 "MMI_ON_CUST_SWDL" 10 "MMI_STDBY_PWR_SAVE_1" 11 "MMI_STDBY_PWR_SAVE_2" 12 "MMI_STANDBY_CUST_SWDL" 13 "MMI_ONLINE_IOC" 14 "MMI_ONLINE" 15 "MMI_PHONE_IOC" 16 "MMI_PHONE" 17 "MMI_RTC" 18 "MMI_DCI" ;
VAL_ 1140 ZR_DimOffs_DU_1 14 "Init" ;
VAL_ 1140 ZR_DimOffs_DU_2 14 "Init" ;
VAL_ 1140 ZR_DimOffs_DU_3 14 "Init" ;
VAL_ 1140 SI_ICAN 0 "keine_Busruhe" 1 "Busruhe" ;
VAL_ 1140 ZR_Lenkerposition 0 "links" 1 "rechts" ;
VAL_ 1140 WLC1_Systemzustand 0 "Wireless_Charger_off" 1 "InitWert_Wireless_Charger_on" ;
VAL_ 1140 WLC2_Systemzustand 0 "Wireless_Charger_off" 1 "InitWert_Wireless_Charger_on" ;
VAL_ 1140 DI_Screendesign 0 "Automatisch" 1 "Tag" 2 "Nacht" 6 "Init" 7 "Fehler" ;
VAL_ 1140 ZR_State_DU_4 0 "Disp_Off" 1 "Disp_On" 2 "LowPow" ;
VAL_ 1140 ZR_DimOffs_DU_4 14 "Init" ;
VAL_ 1411 ZV_verriegeln_Anf 0 "nicht_betaetigt" 1 "betaetigt" ;
VAL_ 1411 ZV_STSG_HFS_Anf 0 "keine_Anforderung" 1 "Anforderung" ;
VAL_ 1411 ZV_STSG_HBFS_Anf 0 "keine_Anforderung" 1 "Anforderung" ;
VAL_ 1411 ZV_Anf_Challenge_Auth 0 "nicht_aktiv" 1 "aktiv" ;
VAL_ 1411 ZV_STSG_Crashzustand 0 "inaktiv" 1 "aktiv" ;
VAL_ 1411 ZV_STSG_eKiSi_defekt 0 "inaktiv" 1 "aktiv" ;
VAL_ 1411 ZV_eRWK_Umfeld_Pruefung 0 "nicht_aktiv" 1 "aktiv" ;
VAL_ 1411 VIP_Sensor_STSG_HFS_betaetigt 0 "keine_VIP_Anforderung_STSG_HFS" 1 "VIP_Anforderung_STSG_HFS" ;
VAL_ 1411 VIP_Sensor_STSG_HBFS_betaetigt 0 "keine_VIP_Anforderung_STSG_HBFS" 1 "VIP_Anforderung_STSG_HBFS" ;
VAL_ 1411 BCM_FH_Freigabe 1 "Funktionsfreigabe Fensterheber" ;
VAL_ 1411 BCM_Komfortfkt_Freigabe 0 "Komfortfunktion gesperrt" 1 "globale Freigabe der Komfortfunktion erteilt" ;
VAL_ 1411 BCM_HSK_Freigabe 0 "erlauben" 1 "sperren" ;
VAL_ 1411 BCM_Verdeck_Freigabe 0 "Verdeckbetrieb nicht erlaubt" 1 "Verdeckbetrieb erlaubt" ;
VAL_ 1411 ZV_verriegelt_intern_ist 1 "Fahrzeug innen verriegelt; Istzustand" ;
VAL_ 1411 ZV_verriegelt_extern_ist 1 "Fahrzeug_aussen_verriegelt_Istzustand" ;
VAL_ 1411 ZV_verriegelt_intern_soll 1 "Fahrzeug verriegelt intern; Sollzusstand" ;
VAL_ 1411 ZV_verriegelt_extern_soll 1 "Fahrzeug verriegelt extern; Sollzusstand" ;
VAL_ 1411 ZV_gesafet_extern_ist 1 "Fahrzeug aussen gesafet; Istzustand" ;
VAL_ 1411 ZV_gesafet_extern_soll 1 "Fahrzeug_aussen_gesafet_Sollzustand" ;
VAL_ 1411 ZV_Einzeltuerentriegelung 1 "Fahrzeug an Einzeltuer entriegelt" ;
VAL_ 1411 ZV_Heckeinzelentriegelung 1 "Heckdeckeleinzelentriegelung" ;
VAL_ 1411 ZV_FT_offen 0 "FT_geschlossen" 1 "FT_geoeffnet" ;
VAL_ 1411 ZV_BT_offen 0 "BT_geschlossen" 1 "BT_geoeffnet" ;
VAL_ 1411 ZV_HFS_offen 0 "geschlossen" 1 "offen" ;
VAL_ 1411 ZV_HBFS_offen 0 "geschlossen" 1 "offen" ;
VAL_ 1411 ZV_HD_offen 1 "Heckdeckel_auf" ;
VAL_ 1411 ZV_HS_offen 0 "Heckscheibe_geschlossen" 1 "Heckscheibe auf" ;
VAL_ 1411 IRUE_aktiv 0 "unscharf" 1 "scharf" ;
VAL_ 1411 DWA_aktiv 0 "unscharf" 1 "scharf" ;
VAL_ 1411 HD_Hauptraste 0 "geschlossen" 1 "offen" ;
VAL_ 1411 HD_Vorraste 0 "geschlossen" 1 "offen" ;
VAL_ 1411 FFB_HDF_Taste 0 "Taste_nicht_betaetigt" 1 "HDF_Taste_am_Funkschluessel_betaetigt" ;
VAL_ 1411 FFB_Panik_Taste 0 "Taste_nicht_betaetigt" 1 "Panik_Taste_am_Funkschluessel_betaetigt" ;
VAL_ 1411 FFB_Auf_Taste 0 "Taste_nicht_betaetigt" 1 "Oeffnentaste_betaetigt" ;
VAL_ 1411 FFB_Zu_Taste 0 "Taste_nicht_betaetigt" 1 "Zu_Taste_am_Funkschluessel_betaetigt" ;
VAL_ 1411 FFB_CarFinder 0 "nicht aktiv" 1 "aktiv" ;
VAL_ 1411 FFB_Komfortoeffnen 0 "kein_Komfortoeffnen_empfangen" 1 "Komfortoeffnen ueber Funk empfangen" ;
VAL_ 1411 FFB_Komfortschliessen 0 "kein_Komfortschliessen_empfangen" 1 "Komfortschliessen ueber Funk empfangen" ;
VAL_ 1411 FBS_IDG_in_Reichweite 0 "ausser_Reichweite_bzw_nicht_ermittelbar" 1 "innerhalb_Reichweite" ;
VAL_ 1411 ZV_Schluessel_Zugang 0 "kein_auth_Schluessel_erkannt" 1 "aktive_Funkschluessel_Nr_01" 2 "aktive_Funkschluessel_Nr_02" 3 "aktive_Funkschluessel_Nr_03" 4 "aktive_Funkschluessel_Nr_04" 5 "aktive_Funkschluessel_Nr_05" 6 "aktive_Funkschluessel_Nr_06" 7 "aktive_Funkschluessel_Nr_07" 8 "aktive_Funkschluessel_Nr_08" 9 "aktive_SmartDevice_Nr_09" 10 "ungueltig_10" 11 "ungueltig_11" 12 "ungueltig_12" 13 "ungueltig_13" 14 "ungueltig_14" 15 "ungueltig_15" ;
VAL_ 1411 ZV_SafeFunktion_aktiv 0 "inaktiv" 1 "aktiv" ;
VAL_ 1411 FBS_Warn_Schluessel_Batt 0 "i.O." 1 "defekt" ;
VAL_ 1411 ZV_Oeffnungsmodus 0 "globale_Oeffnung" 1 "ZV_mit_Einzeltuerentr" 2 "ZV_individuell_selektiv" 3 "ZV_seitenselektiv" ;
VAL_ 1411 HFS_verriegelt 0 "nicht_verriegelt" 1 "verriegelt" ;
VAL_ 1411 HFS_gesafet 0 "nicht_gesafet" 1 "gesafet" ;
VAL_ 1411 HBFS_verriegelt 0 "nicht_verriegelt" 1 "verriegelt" ;
VAL_ 1411 HBFS_gesafet 0 "nicht_gesafet" 1 "gesafet" ;
VAL_ 1411 ZV_ist_Zustand_verfuegbar 0 "nicht_verfuegbar" 1 "verfuegbar_alle_TSGs_am_Bus" ;
VAL_ 1411 IRUE_Taster_Fkts_LED 0 "LED_aus" 1 "LED_ein" ;
VAL_ 1411 ZV_Tankklappe_offen 0 "Tankklappe_geschlossen" 1 "Tankklappe_offen" ;
VAL_ 1411 ZV_Rollo_auf 0 "inaktiv" 1 "aktiv" ;
VAL_ 1411 ZV_Rollo_zu 0 "inaktiv" 1 "aktiv" ;
VAL_ 1411 ZV_SAD_auf 0 "inaktiv" 1 "aktiv" ;
VAL_ 1411 ZV_SAD_zu 0 "inaktiv" 1 "aktiv" ;
VAL_ 1411 BCM_Tankklappensteller_Fehler 0 "kein_Fehler" 1 "Fehler" ;
VAL_ 1411 ZV_verriegelt_soll 0 "Init" 1 "nicht_verriegelt" 2 "verriegelt" ;
